VERSION "dbc-export 1 2026.26.6.5"

NS_ :

BS_:

BU_: ADSP APB APP APS APSB BB BMS CC CMP CMPD CP DAS DI DIF DIR DPB EPAS3P EPAS3S EPASTP EPASTS EPBL EPBR ESP EVSE FC GTW HCML HCMR HVP IBST ICR IDB LS OCS1P ODIN PARK PCS PCS2 PLG PM PMF PMR PNCD PTC RADC RCM RCM2 RCM3 RCU SCCM SCM SCS SDCR TAS TCU TCU2 TPMS TRCM UDS UI UIS UMC USM V2G VC VCBATT VCBATT0 VCBATT1 VCBATT2 VCCC VCFRONT VCFRONT1 VCFRONT2 VCLEFT VCRIGHT VCSEAT2L VCSEAT2R VCSEC VEH

BO_ 2011 VCRIGHT_alertLog: 8 VCRIGHT
 SG_ VCRIGHT_alertID M : 0|10@1+ (1,0) [0|1023] "" Vector__XXX
 SG_ VCRIGHT_a518_seatState m518 : 16|4@1+ (1,0) [0|14] "" Vector__XXX
 SG_ VCRIGHT_a520_epbConfig m520 : 16|4@1+ (1,0) [0|15] "" Vector__XXX
 SG_ VCRIGHT_a520_gtwEpbConfig m520 : 20|4@1+ (1,0) [0|15] "" Vector__XXX
 SG_ VCRIGHT_a525_GTW_twelveVBatteryT m525 : 16|3@1+ (1,0) [0|7] "" Vector__XXX
 SG_ VCRIGHT_a525_newLVBatteryType m525 : 19|3@1+ (1,0) [0|7] "" Vector__XXX
 SG_ VCRIGHT_a525_initialLVBatteryTyp m525 : 24|3@1+ (1,0) [0|7] "" Vector__XXX
 SG_ VCRIGHT_a525_serviceMode m525 : 27|1@1+ (1,0) [0|1] "" Vector__XXX
 SG_ VCRIGHT_a525_factoryGated m525 : 28|1@1+ (1,0) [0|1] "" Vector__XXX
 SG_ VCRIGHT_a525_frunkOpen m525 : 29|1@1+ (1,0) [0|1] "" Vector__XXX
 SG_ VCRIGHT_a538_ptcHeaterFault m538 : 16|1@1+ (1,0) [0|1] "" Vector__XXX
 SG_ VCRIGHT_a538_ductTempSensorFault m538 : 17|1@1+ (1,0) [0|1] "" Vector__XXX
 SG_ VCRIGHT_a538_evapTempSensorFault m538 : 18|1@1+ (1,0) [0|1] "" Vector__XXX
 SG_ VCRIGHT_a538_cabinTempSensorFaul m538 : 19|1@1+ (1,0) [0|1] "" Vector__XXX
 SG_ VCRIGHT_a538_cabinModelNotInitia m538 : 20|1@1+ (1,0) [0|1] "" Vector__XXX
 SG_ VCRIGHT_a538_airpathsBlocked m538 : 21|1@1+ (1,0) [0|1] "" Vector__XXX
 SG_ VCRIGHT_a538_blowerFaultOrStoppe m538 : 22|1@1+ (1,0) [0|1] "" Vector__XXX
 SG_ VCRIGHT_a538_compressorFaultOrSt m538 : 23|1@1+ (1,0) [0|1] "" Vector__XXX
 SG_ VCRIGHT_a538_heatPumpModeNotAtta m538 : 24|1@1+ (1,0) [0|1] "" Vector__XXX
 SG_ VCRIGHT_a538_thsVersionMismatch m538 : 25|1@1+ (1,0) [0|1] "" Vector__XXX
 SG_ VCRIGHT_a538_thsMia m538 : 26|1@1+ (1,0) [0|1] "" Vector__XXX
 SG_ VCRIGHT_a538_hvOn m538 : 27|1@1+ (1,0) [0|1] "" Vector__XXX
 SG_ VCRIGHT_a538_hvacPowerOn m538 : 28|1@1+ (1,0) [0|1] "" Vector__XXX
 SG_ VCRIGHT_a538_limpMode m538 : 29|1@1+ (1,0) [0|1] "" Vector__XXX
 SG_ VCRIGHT_a539_hvacSystemNotNomina m539 : 16|1@1+ (1,0) [0|1] "" Vector__XXX
 SG_ VCRIGHT_a539_modeledCabinTempOut m539 : 17|1@1+ (1,0) [0|1] "" Vector__XXX
 SG_ VCRIGHT_a539_modeledCabinTempExc m539 : 18|1@1+ (1,0) [0|1] "" Vector__XXX
 SG_ VCRIGHT_a539_cabinTempSensorFaul m539 : 19|1@1+ (1,0) [0|1] "" Vector__XXX
 SG_ VCRIGHT_a539_cabinTempSensorOutO m539 : 20|1@1+ (1,0) [0|1] "" Vector__XXX
 SG_ VCRIGHT_a539_modeledCabinTempDev m539 : 21|1@1+ (1,0) [0|1] "" Vector__XXX
 SG_ VCRIGHT_a545_GTW_twelveVBatteryT m545 : 16|3@1+ (1,0) [0|7] "" Vector__XXX
 SG_ VCRIGHT_a545_newLVBatteryType m545 : 19|3@1+ (1,0) [0|7] "" Vector__XXX
 SG_ VCRIGHT_a545_serviceMode m545 : 22|1@1+ (1,0) [0|1] "" Vector__XXX
 SG_ VCRIGHT_a545_factoryGated m545 : 23|1@1+ (1,0) [0|1] "" Vector__XXX
 SG_ VCRIGHT_a545_frunkOpen m545 : 24|1@1+ (1,0) [0|1] "" Vector__XXX
 SG_ VCRIGHT_a551_restrictDoorRelease m551 : 16|1@1+ (1,0) [0|1] "" Vector__XXX
 SG_ VCRIGHT_a551_interiorReleaseReqC m551 : 24|8@1+ (1,0) [0|255] "" Vector__XXX
 SG_ VCRIGHT_a551_lastRequestSourceFr m551 : 32|3@1+ (1,0) [0|7] "" Vector__XXX
 SG_ VCRIGHT_a551_restrictDoorRe_0001 m551 : 35|1@1+ (1,0) [0|1] "" Vector__XXX
 SG_ VCRIGHT_a551_interiorReleas_0001 m551 : 40|8@1+ (1,0) [0|255] "" Vector__XXX
 SG_ VCRIGHT_a551_lastRequestSourceRe m551 : 48|3@1+ (1,0) [0|7] "" Vector__XXX
 SG_ VCRIGHT_a560_isRearwardEndstopUn m560 : 16|1@1+ (1,0) [0|1] "" Vector__XXX
 SG_ VCRIGHT_a560_isAbsPosSensorUncal m560 : 17|1@1+ (1,0) [0|1] "" Vector__XXX
 SG_ VCRIGHT_a560_seatState m560 : 18|4@1+ (1,0) [0|14] "" Vector__XXX
 SG_ VCRIGHT_a560_motorType m560 : 22|1@1+ (1,0) [0|1] "" Vector__XXX
 SG_ VCRIGHT_a560_absPosSensState m560 : 24|2@1+ (1,0) [0|3] "" Vector__XXX
 SG_ VCRIGHT_a563_calibrated m563 : 16|1@1+ (1,0) [0|1] "" Vector__XXX
 SG_ VCRIGHT_a563_angle m563 : 17|8@1- (0.5,59) [-5|122.5] "deg" Vector__XXX
 SG_ VCRIGHT_a563_seatStatePrev m563 : 25|4@1+ (1,0) [0|14] "" Vector__XXX
 SG_ VCRIGHT_a563_obstacleDetectReaso m563 : 29|4@1+ (1,0) [0|15] "" Vector__XXX
 SG_ VCRIGHT_a563_accelLookbackTripDe m563 : 33|7@1+ (1,0) [0|127] "" Vector__XXX
 SG_ VCRIGHT_a563_duty m563 : 40|8@1- (1,0) [-128|127] "%" Vector__XXX
 SG_ VCRIGHT_a563_currentAbsFilt m563 : 48|8@1+ (0.25,0) [0|63.75] "A" Vector__XXX
 SG_ VCRIGHT_a563_motorType m563 : 56|1@1+ (1,0) [0|1] "" Vector__XXX
 SG_ VCRIGHT_a563_absolutePosSensorFo m563 : 57|1@1+ (1,0) [0|1] "" Vector__XXX
 SG_ VCRIGHT_a563_cabinTemp m563 : 58|6@1- (2,20) [-44|82] "degC" Vector__XXX
 SG_ VCRIGHT_a567_isRearwardEndstopUn m567 : 16|1@1+ (1,0) [0|1] "" Vector__XXX
 SG_ VCRIGHT_a567_isAbsPosSensorUncal m567 : 17|1@1+ (1,0) [0|1] "" Vector__XXX
 SG_ VCRIGHT_a568_seatState m568 : 16|4@1+ (1,0) [0|14] "" Vector__XXX
 SG_ VCRIGHT_a570_seatHeatCurrent m570 : 16|12@1+ (0.01,0) [0|40.95] "A" Vector__XXX
 SG_ VCRIGHT_a570_seatHeatTmp m570 : 28|12@1- (0.05,0) [-102.4|102.35] "degC" Vector__XXX
 SG_ VCRIGHT_a571_seatHeatCurrent m571 : 16|12@1+ (0.01,0) [0|40.95] "A" Vector__XXX
 SG_ VCRIGHT_a571_seatHeatTmp m571 : 28|12@1- (0.05,0) [-102.4|102.35] "degC" Vector__XXX
 SG_ VCRIGHT_a572_seatHeatCurrent m572 : 16|12@1+ (0.01,0) [0|40.95] "A" Vector__XXX
 SG_ VCRIGHT_a572_seatHeatTmp m572 : 28|12@1- (0.05,0) [-102.4|102.35] "degC" Vector__XXX
 SG_ VCRIGHT_a573_seatHeatCurrent m573 : 16|12@1+ (0.01,0) [0|40.95] "A" Vector__XXX
 SG_ VCRIGHT_a573_seatHeatTmp m573 : 28|12@1- (0.05,0) [-102.4|102.35] "degC" Vector__XXX
 SG_ VCRIGHT_a577_outputFaulted m577 : 16|1@1+ (1,0) [0|1] "" Vector__XXX
 SG_ VCRIGHT_a577_currentSenseFaulted m577 : 17|1@1+ (1,0) [0|1] "" Vector__XXX
 SG_ VCRIGHT_a577_tempSenseFaulted m577 : 18|1@1+ (1,0) [0|1] "" Vector__XXX
 SG_ VCRIGHT_a577_underCurrent m577 : 19|1@1+ (1,0) [0|1] "" Vector__XXX
 SG_ VCRIGHT_a577_overCurrent m577 : 20|1@1+ (1,0) [0|1] "" Vector__XXX
 SG_ VCRIGHT_a577_overTemperature m577 : 21|1@1+ (1,0) [0|1] "" Vector__XXX
 SG_ VCRIGHT_a578_openCircuitDoorFR m578 : 16|1@1+ (1,0) [0|1] "" Vector__XXX
 SG_ VCRIGHT_a578_shortCircuitDoorFR m578 : 17|1@1+ (1,0) [0|1] "" Vector__XXX
 SG_ VCRIGHT_a578_miaDoorFR m578 : 18|1@1+ (1,0) [0|1] "" Vector__XXX
 SG_ VCRIGHT_a578_openCircuitDoorRR m578 : 19|1@1+ (1,0) [0|1] "" Vector__XXX
 SG_ VCRIGHT_a578_shortCircuitDoorRR m578 : 20|1@1+ (1,0) [0|1] "" Vector__XXX
 SG_ VCRIGHT_a578_miaDoorRR m578 : 21|1@1+ (1,0) [0|1] "" Vector__XXX
 SG_ VCRIGHT_a579_liftgateFollowerSto m579 : 16|2@1+ (1,0) [0|3] "" Vector__XXX
 SG_ VCRIGHT_a579_liftgateFollowerPos m579 : 24|7@1- (1,43) [-21|106] "deg" Vector__XXX
 SG_ VCRIGHT_a579_liftgateFollowerLat m579 : 32|4@1+ (1,0) [1|15] "" Vector__XXX
 SG_ VCRIGHT_a585_ambientTemp m585 : 16|8@1+ (0.5,-40) [-39.5|87.5] "degC" Vector__XXX
 SG_ VCRIGHT_a586_ambientTemp m586 : 16|8@1+ (0.5,-40) [-39.5|87.5] "degC" Vector__XXX
 SG_ VCRIGHT_a587_VEH_switchStatus m587 : 63|1@1+ (1,0) [0|1] "" Vector__XXX
 SG_ VCRIGHT_a588_VEH_seatStatus2 m588 : 61|1@1+ (1,0) [0|1] "" Vector__XXX
 SG_ VCRIGHT_a588_VEH_switchStatus m588 : 62|1@1+ (1,0) [0|1] "" Vector__XXX
 SG_ VCRIGHT_a588_VEH_restraintStatus m588 : 63|1@1+ (1,0) [0|1] "" Vector__XXX
 SG_ VCRIGHT_a590_seatMotorCalibrated m590 : 16|1@1+ (1,0) [0|1] "" Vector__XXX
 SG_ VCRIGHT_a590_seatMotorCurrent m590 : 17|12@1- (0.01,0) [-20.48|20.47] "A" Vector__XXX
 SG_ VCRIGHT_a590_seatMotorState m590 : 29|3@1+ (1,0) [0|7] "" Vector__XXX
 SG_ VCRIGHT_a590_seatSwitchBack m590 : 32|2@1+ (1,0) [1|3] "" Vector__XXX
 SG_ VCRIGHT_a590_seatSwitchForward m590 : 34|2@1+ (1,0) [1|3] "" Vector__XXX
 SG_ VCRIGHT_a591_seatMotorCurrent m591 : 16|12@1- (0.01,0) [-20.48|20.47] "A" Vector__XXX
 SG_ VCRIGHT_a591_seatMotorPosReal m591 : 28|12@1- (1,0) [-2048|2047] "mm" Vector__XXX
 SG_ VCRIGHT_a591_seatMotorState m591 : 40|3@1+ (1,0) [0|7] "" Vector__XXX
 SG_ VCRIGHT_a591_seatSwitchBack m591 : 43|2@1+ (1,0) [1|3] "" Vector__XXX
 SG_ VCRIGHT_a591_seatSwitchForward m591 : 45|2@1+ (1,0) [1|3] "" Vector__XXX
 SG_ VCRIGHT_a592_seatMotorCurrent m592 : 16|12@1- (0.01,0) [-20.48|20.47] "A" Vector__XXX
 SG_ VCRIGHT_a592_seatMotorPosReal m592 : 28|12@1- (1,0) [-2048|2047] "mm" Vector__XXX
 SG_ VCRIGHT_a592_seatMotorState m592 : 40|3@1+ (1,0) [0|7] "" Vector__XXX
 SG_ VCRIGHT_a592_seatSwitchBack m592 : 43|2@1+ (1,0) [1|3] "" Vector__XXX
 SG_ VCRIGHT_a592_seatSwitchForward m592 : 45|2@1+ (1,0) [1|3] "" Vector__XXX
 SG_ VCRIGHT_a593_seatMotorCalibrated m593 : 16|1@1+ (1,0) [0|1] "" Vector__XXX
 SG_ VCRIGHT_a593_seatMotorCurrent m593 : 17|12@1- (0.01,0) [-20.48|20.47] "A" Vector__XXX
 SG_ VCRIGHT_a593_seatMotorPosReal m593 : 32|12@1- (1,0) [-2048|2047] "mm" Vector__XXX
 SG_ VCRIGHT_a593_seatMotorState m593 : 44|3@1+ (1,0) [0|7] "" Vector__XXX
 SG_ VCRIGHT_a593_seatSwitchBack m593 : 48|2@1+ (1,0) [1|3] "" Vector__XXX
 SG_ VCRIGHT_a593_seatSwitchForward m593 : 50|2@1+ (1,0) [1|3] "" Vector__XXX
 SG_ VCRIGHT_a594_seatMotorCurrent m594 : 16|12@1- (0.01,0) [-20.48|20.47] "A" Vector__XXX
 SG_ VCRIGHT_a594_seatMotorDCurrent m594 : 28|12@1- (0.01,0) [-20.48|20.47] "A" Vector__XXX
 SG_ VCRIGHT_a594_seatMotorPosReal m594 : 40|12@1- (1,0) [-2048|2047] "mm" Vector__XXX
 SG_ VCRIGHT_a594_seatMotorState m594 : 52|3@1+ (1,0) [0|7] "" Vector__XXX
 SG_ VCRIGHT_a595_seatMotorCurrent m595 : 16|12@1- (0.01,0) [-20.48|20.47] "A" Vector__XXX
 SG_ VCRIGHT_a595_seatMotorDCurrent m595 : 28|12@1- (0.01,0) [-20.48|20.47] "A" Vector__XXX
 SG_ VCRIGHT_a595_seatMotorPosReal m595 : 40|12@1- (1,0) [-2048|2047] "mm" Vector__XXX
 SG_ VCRIGHT_a595_seatMotorState m595 : 52|3@1+ (1,0) [0|7] "" Vector__XXX
 SG_ VCRIGHT_a596_frontDoorLatchAjarS m596 : 16|12@1+ (1.25,0) [0|5118.75] "mV" Vector__XXX
 SG_ VCRIGHT_a597_rearDoorLatchAjarSw m597 : 16|12@1+ (1.25,0) [0|5118.75] "mV" Vector__XXX
 SG_ VCRIGHT_a599_GTW_twelveVBatteryT m599 : 16|3@1+ (1,0) [0|7] "" Vector__XXX
 SG_ VCRIGHT_a599_newLVBatteryType m599 : 19|3@1+ (1,0) [0|7] "" Vector__XXX
 SG_ VCRIGHT_a599_initialLVBatteryTyp m599 : 24|3@1+ (1,0) [0|7] "" Vector__XXX
 SG_ VCRIGHT_a599_serviceMode m599 : 27|1@1+ (1,0) [0|1] "" Vector__XXX
 SG_ VCRIGHT_a599_factoryGated m599 : 28|1@1+ (1,0) [0|1] "" Vector__XXX
 SG_ VCRIGHT_a599_frunkOpen m599 : 29|1@1+ (1,0) [0|1] "" Vector__XXX
 SG_ VCRIGHT_a605_excessiveMacFailure m605 : 16|1@1+ (1,0) [0|1] "" Vector__XXX

BO_ 960 VCRIGHT_alertMatrix: 8 VCRIGHT
 SG_ VCRIGHT_matrixIndex M : 0|4@1+ (1,0) [0|15] "" Vector__XXX
 SG_ VCRIGHT_a001_WatchdogReset m0 : 4|1@1+ (1,0) [0|1] "" Vector__XXX
 SG_ VCRIGHT_a002_PowerLossReset m0 : 5|1@1+ (1,0) [0|1] "" Vector__XXX
 SG_ VCRIGHT_a003_SWAssertion m0 : 6|1@1+ (1,0) [0|1] "" Vector__XXX
 SG_ VCRIGHT_a005_CANTXError m0 : 8|1@1+ (1,0) [0|1] "" Vector__XXX
 SG_ VCRIGHT_a006_CANTX_cyclicError m0 : 9|1@1+ (1,0) [0|1] "" Vector__XXX
 SG_ VCRIGHT_a010_ExtSupplyVoltError m0 : 13|1@1+ (1,0) [0|1] "" Vector__XXX
 SG_ VCRIGHT_a012_CPUReset m0 : 15|1@1+ (1,0) [0|1] "" Vector__XXX
 SG_ VCRIGHT_a013_AlertManagerFault m0 : 16|1@1+ (1,0) [0|1] "" Vector__XXX
 SG_ VCRIGHT_a015_NVMMError m0 : 18|1@1+ (1,0) [0|1] "" Vector__XXX
 SG_ VCRIGHT_a016_NVMMRecordError m0 : 19|1@1+ (1,0) [0|1] "" Vector__XXX
 SG_ VCRIGHT_a017_NVMMStatusDbg m0 : 20|1@1+ (1,0) [0|1] "" Vector__XXX
 SG_ VCRIGHT_a021_TaskSchedulerError m0 : 24|1@1+ (1,0) [0|1] "" Vector__XXX
 SG_ VCRIGHT_a022_TaskInitError m0 : 25|1@1+ (1,0) [0|1] "" Vector__XXX
 SG_ VCRIGHT_a029_CoreDump m0 : 32|1@1+ (1,0) [0|1] "" Vector__XXX
 SG_ VCRIGHT_a030_ECULogUploadRequest m0 : 33|1@1+ (1,0) [0|1] "" Vector__XXX
 SG_ VCRIGHT_a031_UDSActive m0 : 34|1@1+ (1,0) [0|1] "" Vector__XXX
 SG_ VCRIGHT_a041_HighCPULoad m0 : 44|1@1+ (1,0) [0|1] "" Vector__XXX
 SG_ VCRIGHT_a042_HighStackUsage m0 : 45|1@1+ (1,0) [0|1] "" Vector__XXX
 SG_ VCRIGHT_a043_Task1msError m0 : 46|1@1+ (1,0) [0|1] "" Vector__XXX
 SG_ VCRIGHT_a044_Task10msError m0 : 47|1@1+ (1,0) [0|1] "" Vector__XXX
 SG_ VCRIGHT_a045_Task100msError m0 : 48|1@1+ (1,0) [0|1] "" Vector__XXX
 SG_ VCRIGHT_a046_Task1000msError m0 : 49|1@1+ (1,0) [0|1] "" Vector__XXX
 SG_ VCRIGHT_a057_HVP_MIA m0 : 60|1@1+ (1,0) [0|1] "" Vector__XXX
 SG_ VCRIGHT_a058_inputRHighSyncDebug m0 : 61|1@1+ (1,0) [0|1] "" Vector__XXX
 SG_ VCRIGHT_a059_inputResistanceHigh m0 : 62|1@1+ (1,0) [0|1] "" Vector__XXX
 SG_ VCRIGHT_a060_engineeringBuild m0 : 63|1@1+ (1,0) [0|1] "" Vector__XXX
 SG_ VCRIGHT_a061_XCPConnected m1 : 4|1@1+ (1,0) [0|1] "" Vector__XXX
 SG_ VCRIGHT_a062_XCPWasConnected m1 : 5|1@1+ (1,0) [0|1] "" Vector__XXX
 SG_ VCRIGHT_a063_SwitchFault m1 : 6|1@1+ (1,0) [0|1] "" Vector__XXX
 SG_ VCRIGHT_a064_busSleepReqTimeout m1 : 7|1@1+ (1,0) [0|1] "" Vector__XXX
 SG_ VCRIGHT_a065_emiosIsrRateLimited m1 : 8|1@1+ (1,0) [0|1] "" Vector__XXX
 SG_ VCRIGHT_a066_emiosIsrShortPeriod m1 : 9|1@1+ (1,0) [0|1] "" Vector__XXX
 SG_ VCRIGHT_a082_VCRIGHT_IPC_MIA m1 : 25|1@1+ (1,0) [0|1] "" Vector__XXX
 SG_ VCRIGHT_a083_VCLEFT_IPC_MIA m1 : 26|1@1+ (1,0) [0|1] "" Vector__XXX
 SG_ VCRIGHT_a084_TPMS_MIA m1 : 27|1@1+ (1,0) [0|1] "" Vector__XXX
 SG_ VCRIGHT_a085_CCCM_MIA m1 : 28|1@1+ (1,0) [0|1] "" Vector__XXX
 SG_ VCRIGHT_a086_VCBATT_MIA m1 : 29|1@1+ (1,0) [0|1] "" Vector__XXX
 SG_ VCRIGHT_a087_DIREL_MIA m1 : 30|1@1+ (1,0) [0|1] "" Vector__XXX
 SG_ VCRIGHT_a088_DIRER_MIA m1 : 31|1@1+ (1,0) [0|1] "" Vector__XXX
 SG_ VCRIGHT_a089_IBST_MIA m1 : 32|1@1+ (1,0) [0|1] "" Vector__XXX
 SG_ VCRIGHT_a090_APS_MIA m1 : 33|1@1+ (1,0) [0|1] "" Vector__XXX
 SG_ VCRIGHT_a091_CMPD_MIA m1 : 34|1@1+ (1,0) [0|1] "" Vector__XXX
 SG_ VCRIGHT_a092_VCSEATD_MIA m1 : 35|1@1+ (1,0) [0|1] "" Vector__XXX
 SG_ VCRIGHT_a093_VCSEATP_MIA m1 : 36|1@1+ (1,0) [0|1] "" Vector__XXX
 SG_ VCRIGHT_a094_EPAS3P_MIA m1 : 37|1@1+ (1,0) [0|1] "" Vector__XXX
 SG_ VCRIGHT_a095_CHG_MIA m1 : 38|1@1+ (1,0) [0|1] "" Vector__XXX
 SG_ VCRIGHT_a096_OCS1P_MIA m1 : 39|1@1+ (1,0) [0|1] "" Vector__XXX
 SG_ VCRIGHT_a097_CMP_MIA m1 : 40|1@1+ (1,0) [0|1] "" Vector__XXX
 SG_ VCRIGHT_a098_DIR_MIA m1 : 41|1@1+ (1,0) [0|1] "" Vector__XXX
 SG_ VCRIGHT_a099_PARK_MIA m1 : 42|1@1+ (1,0) [0|1] "" Vector__XXX
 SG_ VCRIGHT_a100_CANbus_MIA m1 : 43|1@1+ (1,0) [0|1] "" Vector__XXX
 SG_ VCRIGHT_a101_PM_MIA m1 : 44|1@1+ (1,0) [0|1] "" Vector__XXX
 SG_ VCRIGHT_a102_PTC_MIA m1 : 45|1@1+ (1,0) [0|1] "" Vector__XXX
 SG_ VCRIGHT_a103_CP_MIA m1 : 46|1@1+ (1,0) [0|1] "" Vector__XXX
 SG_ VCRIGHT_a104_DAS_MIA m1 : 47|1@1+ (1,0) [0|1] "" Vector__XXX
 SG_ VCRIGHT_a105_TAS_MIA m1 : 48|1@1+ (1,0) [0|1] "" Vector__XXX
 SG_ VCRIGHT_a106_PCS_MIA m1 : 49|1@1+ (1,0) [0|1] "" Vector__XXX
 SG_ VCRIGHT_a107_BMS_MIA m1 : 50|1@1+ (1,0) [0|1] "" Vector__XXX
 SG_ VCRIGHT_a108_DIF_MIA m1 : 51|1@1+ (1,0) [0|1] "" Vector__XXX
 SG_ VCRIGHT_a109_RCM_MIA m1 : 52|1@1+ (1,0) [0|1] "" Vector__XXX
 SG_ VCRIGHT_a110_GTW_MIA m1 : 53|1@1+ (1,0) [0|1] "" Vector__XXX
 SG_ VCRIGHT_a111_EPBR_MIA m1 : 54|1@1+ (1,0) [0|1] "" Vector__XXX
 SG_ VCRIGHT_a112_EPBL_MIA m1 : 55|1@1+ (1,0) [0|1] "" Vector__XXX
 SG_ VCRIGHT_a113_UI_MIA m1 : 56|1@1+ (1,0) [0|1] "" Vector__XXX
 SG_ VCRIGHT_a114_ESP_MIA m1 : 57|1@1+ (1,0) [0|1] "" Vector__XXX
 SG_ VCRIGHT_a115_VCSEC_MIA m1 : 58|1@1+ (1,0) [0|1] "" Vector__XXX
 SG_ VCRIGHT_a116_VCRIGHT_MIA m1 : 59|1@1+ (1,0) [0|1] "" Vector__XXX
 SG_ VCRIGHT_a117_VCLEFT_MIA m1 : 60|1@1+ (1,0) [0|1] "" Vector__XXX
 SG_ VCRIGHT_a118_VCFRONT_MIA m1 : 61|1@1+ (1,0) [0|1] "" Vector__XXX
 SG_ VCRIGHT_a119_SCCM_MIA m1 : 62|1@1+ (1,0) [0|1] "" Vector__XXX
 SG_ VCRIGHT_a120_DI_DRIVE_MIA m1 : 63|1@1+ (1,0) [0|1] "" Vector__XXX
 SG_ VCRIGHT_a121_ETC_MIA m2 : 4|1@1+ (1,0) [0|1] "" Vector__XXX
 SG_ VCRIGHT_a122_ICR_MIA m2 : 5|1@1+ (1,0) [0|1] "" Vector__XXX
 SG_ VCRIGHT_a123_VC_SECONDARY_LIGHTI m2 : 6|1@1+ (1,0) [0|1] "" Vector__XXX
 SG_ VCRIGHT_a124_BB_MIA m2 : 7|1@1+ (1,0) [0|1] "" Vector__XXX
 SG_ VCRIGHT_a125_RCU_MIA m2 : 8|1@1+ (1,0) [0|1] "" Vector__XXX
 SG_ VCRIGHT_a126_hvacActOpenLoadDBG m2 : 9|1@1+ (1,0) [0|1] "" Vector__XXX
 SG_ VCRIGHT_a127_hvacActOvercurrentD m2 : 10|1@1+ (1,0) [0|1] "" Vector__XXX
 SG_ VCRIGHT_a128_hvacActDrvFaultDBG m2 : 11|1@1+ (1,0) [0|1] "" Vector__XXX
 SG_ VCRIGHT_a129_hvacIntakeUncalib m2 : 12|1@1+ (1,0) [0|1] "" Vector__XXX
 SG_ VCRIGHT_a130_hvacLHBleedUncalib m2 : 13|1@1+ (1,0) [0|1] "" Vector__XXX
 SG_ VCRIGHT_a131_hvacRHBleedUncalib m2 : 14|1@1+ (1,0) [0|1] "" Vector__XXX
 SG_ VCRIGHT_a132_hvacLHVaneUncalib m2 : 15|1@1+ (1,0) [0|1] "" Vector__XXX
 SG_ VCRIGHT_a133_hvacRHVaneUncalib m2 : 16|1@1+ (1,0) [0|1] "" Vector__XXX
 SG_ VCRIGHT_a134_hvacUpprModeUncalib m2 : 17|1@1+ (1,0) [0|1] "" Vector__XXX
 SG_ VCRIGHT_a135_hvacLowrModeUncalib m2 : 18|1@1+ (1,0) [0|1] "" Vector__XXX
 SG_ VCRIGHT_a136_hvacIntakeFault m2 : 19|1@1+ (1,0) [0|1] "" Vector__XXX
 SG_ VCRIGHT_a137_hvacLHBleedFault m2 : 20|1@1+ (1,0) [0|1] "" Vector__XXX
 SG_ VCRIGHT_a138_hvacRHBleedFault m2 : 21|1@1+ (1,0) [0|1] "" Vector__XXX
 SG_ VCRIGHT_a139_hvacLHVaneFault m2 : 22|1@1+ (1,0) [0|1] "" Vector__XXX
 SG_ VCRIGHT_a140_hvacRHVaneFault m2 : 23|1@1+ (1,0) [0|1] "" Vector__XXX
 SG_ VCRIGHT_a141_hvacUpperModeFault m2 : 24|1@1+ (1,0) [0|1] "" Vector__XXX
 SG_ VCRIGHT_a142_hvacLowerModeFault m2 : 25|1@1+ (1,0) [0|1] "" Vector__XXX
 SG_ VCRIGHT_a143_mirrorManuallyFolde m2 : 26|1@1+ (1,0) [0|1] "" Vector__XXX
 SG_ VCRIGHT_a144_evaporatorTempSns m2 : 27|1@1+ (1,0) [0|1] "" Vector__XXX
 SG_ VCRIGHT_a145_ductLeftTempSns m2 : 28|1@1+ (1,0) [0|1] "" Vector__XXX
 SG_ VCRIGHT_a146_ductRightTempSns m2 : 29|1@1+ (1,0) [0|1] "" Vector__XXX
 SG_ VCRIGHT_a147_incarProbeTempSns m2 : 30|1@1+ (1,0) [0|1] "" Vector__XXX
 SG_ VCRIGHT_a148_incarMidTempSns m2 : 31|1@1+ (1,0) [0|1] "" Vector__XXX
 SG_ VCRIGHT_a149_incarDeepTempSns m2 : 32|1@1+ (1,0) [0|1] "" Vector__XXX
 SG_ VCRIGHT_a150_windowPinchFront m2 : 33|1@1+ (1,0) [0|1] "" Vector__XXX
 SG_ VCRIGHT_a151_windowPinchRear m2 : 34|1@1+ (1,0) [0|1] "" Vector__XXX
 SG_ VCRIGHT_a152_windowUncalFront m2 : 35|1@1+ (1,0) [0|1] "" Vector__XXX
 SG_ VCRIGHT_a153_windowUncalRear m2 : 36|1@1+ (1,0) [0|1] "" Vector__XXX
 SG_ VCRIGHT_a154_windowThermalFront m2 : 37|1@1+ (1,0) [0|1] "" Vector__XXX
 SG_ VCRIGHT_a155_windowThermalRear m2 : 38|1@1+ (1,0) [0|1] "" Vector__XXX
 SG_ VCRIGHT_a156_windowNoInputFront m2 : 39|1@1+ (1,0) [0|1] "" Vector__XXX
 SG_ VCRIGHT_a157_windowNoInputRear m2 : 40|1@1+ (1,0) [0|1] "" Vector__XXX
 SG_ VCRIGHT_a158_windowPinchOverideF m2 : 41|1@1+ (1,0) [0|1] "" Vector__XXX
 SG_ VCRIGHT_a159_windowPinchOverideR m2 : 42|1@1+ (1,0) [0|1] "" Vector__XXX
 SG_ VCRIGHT_a160_windowUndercurrentF m2 : 43|1@1+ (1,0) [0|1] "" Vector__XXX
 SG_ VCRIGHT_a161_windowUndercurrentR m2 : 44|1@1+ (1,0) [0|1] "" Vector__XXX
 SG_ VCRIGHT_a162_windowEncoderStallF m2 : 45|1@1+ (1,0) [0|1] "" Vector__XXX
 SG_ VCRIGHT_a163_windowEncoderStallR m2 : 46|1@1+ (1,0) [0|1] "" Vector__XXX
 SG_ VCRIGHT_a164_windowFactoryTest m2 : 47|1@1+ (1,0) [0|1] "" Vector__XXX
 SG_ VCRIGHT_a165_windowFactoryTest2 m2 : 48|1@1+ (1,0) [0|1] "" Vector__XXX
 SG_ VCRIGHT_a166_windowDebug m2 : 49|1@1+ (1,0) [0|1] "" Vector__XXX
 SG_ VCRIGHT_a167_windowDebugPinchF m2 : 50|1@1+ (1,0) [0|1] "" Vector__XXX
 SG_ VCRIGHT_a168_windowDebugPinchR m2 : 51|1@1+ (1,0) [0|1] "" Vector__XXX
 SG_ VCRIGHT_a169_windowCurrentPeakF m2 : 52|1@1+ (1,0) [0|1] "" Vector__XXX
 SG_ VCRIGHT_a170_windowCurrentPeakR m2 : 53|1@1+ (1,0) [0|1] "" Vector__XXX
 SG_ VCRIGHT_a171_hvacRearUncalib m2 : 54|1@1+ (1,0) [0|1] "" Vector__XXX
 SG_ VCRIGHT_a172_SPI_MIA m2 : 55|1@1+ (1,0) [0|1] "" Vector__XXX
 SG_ VCRIGHT_a173_windowBtnDoorOpen m2 : 56|1@1+ (1,0) [0|1] "" Vector__XXX
 SG_ VCRIGHT_a174_BLERightPowerCycled m2 : 57|1@1+ (1,0) [0|1] "" Vector__XXX
 SG_ VCRIGHT_a175_windowSealDefectFro m2 : 58|1@1+ (1,0) [0|1] "" Vector__XXX
 SG_ VCRIGHT_a176_windowSealDefectRea m2 : 59|1@1+ (1,0) [0|1] "" Vector__XXX
 SG_ VCRIGHT_a177_hvacRearFault m2 : 60|1@1+ (1,0) [0|1] "" Vector__XXX
 SG_ VCRIGHT_a178_trunkSwitchVCBATTMI m2 : 61|1@1+ (1,0) [0|1] "" Vector__XXX
 SG_ VCRIGHT_a179_trunkSwitchVCFRONTM m2 : 62|1@1+ (1,0) [0|1] "" Vector__XXX
 SG_ VCRIGHT_a180_frontDoorLatchRehom m2 : 63|1@1+ (1,0) [0|1] "" Vector__XXX
 SG_ VCRIGHT_a181_rearDoorLatchRehome m3 : 4|1@1+ (1,0) [0|1] "" Vector__XXX
 SG_ VCRIGHT_a182_emergencyLatchRel m3 : 5|1@1+ (1,0) [0|1] "" Vector__XXX
 SG_ VCRIGHT_a183_doorStateFactoryTes m3 : 6|1@1+ (1,0) [0|1] "" Vector__XXX
 SG_ VCRIGHT_a184_trunkFailedOpening m3 : 7|1@1+ (1,0) [0|1] "" Vector__XXX
 SG_ VCRIGHT_a185_summonAborted m3 : 8|1@1+ (1,0) [0|1] "" Vector__XXX
 SG_ VCRIGHT_a186_latchReleaseFailedF m3 : 9|1@1+ (1,0) [0|1] "" Vector__XXX
 SG_ VCRIGHT_a187_latchReleaseFailedR m3 : 10|1@1+ (1,0) [0|1] "" Vector__XXX
 SG_ VCRIGHT_a188_latchUnableToRearmF m3 : 11|1@1+ (1,0) [0|1] "" Vector__XXX
 SG_ VCRIGHT_a189_latchUnableToRearmR m3 : 12|1@1+ (1,0) [0|1] "" Vector__XXX
 SG_ VCRIGHT_a190_eFuseMgmtVbatFused m3 : 13|1@1+ (1,0) [0|1] "" Vector__XXX
 SG_ VCRIGHT_a191_gloveboxPower m3 : 14|1@1+ (1,0) [0|1] "" Vector__XXX
 SG_ VCRIGHT_a192_gloveboxLatchRel m3 : 15|1@1+ (1,0) [0|1] "" Vector__XXX
 SG_ VCRIGHT_a193_amplifierEFuseFault m3 : 16|1@1+ (1,0) [0|1] "" Vector__XXX
 SG_ VCRIGHT_a194_cntctrPwrEFuseFault m3 : 17|1@1+ (1,0) [0|1] "" Vector__XXX
 SG_ VCRIGHT_a195_hvcEFuseFault m3 : 18|1@1+ (1,0) [0|1] "" Vector__XXX
 SG_ VCRIGHT_a196_VEHCANOverterminate m3 : 19|1@1+ (1,0) [0|1] "" Vector__XXX
 SG_ VCRIGHT_a197_VEHCANUndertrminate m3 : 20|1@1+ (1,0) [0|1] "" Vector__XXX
 SG_ VCRIGHT_a198_PRVCANOverterminate m3 : 21|1@1+ (1,0) [0|1] "" Vector__XXX
 SG_ VCRIGHT_a199_PRVCANUndertrminate m3 : 22|1@1+ (1,0) [0|1] "" Vector__XXX
 SG_ VCRIGHT_a200_motorPhantomEncoder m3 : 23|1@1+ (1,0) [0|1] "" Vector__XXX
 SG_ VCRIGHT_a201_motorDutyEncDisabl m3 : 24|1@1+ (1,0) [0|1] "" Vector__XXX
 SG_ VCRIGHT_a202_epbmUnderIStatic m3 : 25|1@1+ (1,0) [0|1] "" Vector__XXX
 SG_ VCRIGHT_a203_epbmOverIStatic m3 : 26|1@1+ (1,0) [0|1] "" Vector__XXX
 SG_ VCRIGHT_a204_epbmUnderIDyn m3 : 27|1@1+ (1,0) [0|1] "" Vector__XXX
 SG_ VCRIGHT_a205_epbmOverIDyn m3 : 28|1@1+ (1,0) [0|1] "" Vector__XXX
 SG_ VCRIGHT_a206_epbWrongDirection m3 : 29|1@1+ (1,0) [0|1] "" Vector__XXX
 SG_ VCRIGHT_a207_epbmEnableWrong m3 : 30|1@1+ (1,0) [0|1] "" Vector__XXX
 SG_ VCRIGHT_a208_epbFaulted m3 : 31|1@1+ (1,0) [0|1] "" Vector__XXX
 SG_ VCRIGHT_a209_epbStateMisTime m3 : 32|1@1+ (1,0) [0|1] "" Vector__XXX
 SG_ VCRIGHT_a210_epbStateTime m3 : 33|1@1+ (1,0) [0|1] "" Vector__XXX
 SG_ VCRIGHT_a211_epbmUnderIStaticNew m3 : 34|1@1+ (1,0) [0|1] "" Vector__XXX
 SG_ VCRIGHT_a212_epbmOverIStaticNew m3 : 35|1@1+ (1,0) [0|1] "" Vector__XXX
 SG_ VCRIGHT_a213_epbmUnderIDynNew m3 : 36|1@1+ (1,0) [0|1] "" Vector__XXX
 SG_ VCRIGHT_a214_epbmOverIDynNew m3 : 37|1@1+ (1,0) [0|1] "" Vector__XXX
 SG_ VCRIGHT_a215_currentDesyncWarnin m3 : 38|1@1+ (1,0) [0|1] "" Vector__XXX
 SG_ VCRIGHT_a216_SPI_MIA_debugData1 m3 : 39|1@1+ (1,0) [0|1] "" Vector__XXX
 SG_ VCRIGHT_a217_SPI_MIA_debugData2 m3 : 40|1@1+ (1,0) [0|1] "" Vector__XXX
 SG_ VCRIGHT_a218_motorDriverFault m3 : 41|1@1+ (1,0) [0|1] "" Vector__XXX
 SG_ VCRIGHT_a219_motorCurrentDropout m3 : 42|1@1+ (1,0) [0|1] "" Vector__XXX
 SG_ VCRIGHT_a220_reverseLightFaultUs m3 : 43|1@1+ (1,0) [0|1] "" Vector__XXX
 SG_ VCRIGHT_a221_undervoltageLoadshe m3 : 44|1@1+ (1,0) [0|1] "" Vector__XXX
 SG_ VCRIGHT_a222_rearFasciaFogLightF m3 : 45|1@1+ (1,0) [0|1] "" Vector__XXX
 SG_ VCRIGHT_a223_VCBATT1_MIA m3 : 46|1@1+ (1,0) [0|1] "" Vector__XXX
 SG_ VCRIGHT_a224_seatEncStallTrack m3 : 47|1@1+ (1,0) [0|1] "" Vector__XXX
 SG_ VCRIGHT_a225_seatEncStallBack m3 : 48|1@1+ (1,0) [0|1] "" Vector__XXX
 SG_ VCRIGHT_a226_seatEncStallTilt m3 : 49|1@1+ (1,0) [0|1] "" Vector__XXX
 SG_ VCRIGHT_a227_seatEncStallLift m3 : 50|1@1+ (1,0) [0|1] "" Vector__XXX
 SG_ VCRIGHT_a228_seatEncOverTrack m3 : 51|1@1+ (1,0) [0|1] "" Vector__XXX
 SG_ VCRIGHT_a229_seatEncOverBack m3 : 52|1@1+ (1,0) [0|1] "" Vector__XXX
 SG_ VCRIGHT_a230_seatEncOverTilt m3 : 53|1@1+ (1,0) [0|1] "" Vector__XXX
 SG_ VCRIGHT_a231_seatEncOverLift m3 : 54|1@1+ (1,0) [0|1] "" Vector__XXX
 SG_ VCRIGHT_a232_seatCurrUnderTrack m3 : 55|1@1+ (1,0) [0|1] "" Vector__XXX
 SG_ VCRIGHT_a233_seatCurrUnderBack m3 : 56|1@1+ (1,0) [0|1] "" Vector__XXX
 SG_ VCRIGHT_a234_seatCurrUnderTilt m3 : 57|1@1+ (1,0) [0|1] "" Vector__XXX
 SG_ VCRIGHT_a235_seatCurrUnderLift m3 : 58|1@1+ (1,0) [0|1] "" Vector__XXX
 SG_ VCRIGHT_a236_lumbarOverPresA m3 : 59|1@1+ (1,0) [0|1] "" Vector__XXX
 SG_ VCRIGHT_a237_lumbarOverPresB m3 : 60|1@1+ (1,0) [0|1] "" Vector__XXX
 SG_ VCRIGHT_a238_lumbarValveMIA m3 : 61|1@1+ (1,0) [0|1] "" Vector__XXX
 SG_ VCRIGHT_a239_seatHeatIFront m3 : 62|1@1+ (1,0) [0|1] "" Vector__XXX
 SG_ VCRIGHT_a240_seatHeatShortFront m3 : 63|1@1+ (1,0) [0|1] "" Vector__XXX
 SG_ VCRIGHT_a241_seatHeatMIAFront m4 : 4|1@1+ (1,0) [0|1] "" Vector__XXX
 SG_ VCRIGHT_a242_seatHeatIRearL m4 : 5|1@1+ (1,0) [0|1] "" Vector__XXX
 SG_ VCRIGHT_a243_seatHeatShortRearL m4 : 6|1@1+ (1,0) [0|1] "" Vector__XXX
 SG_ VCRIGHT_a244_seatHeatMIARearL m4 : 7|1@1+ (1,0) [0|1] "" Vector__XXX
 SG_ VCRIGHT_a245_seatHeatIRearC m4 : 8|1@1+ (1,0) [0|1] "" Vector__XXX
 SG_ VCRIGHT_a246_seatHeatShortRearC m4 : 9|1@1+ (1,0) [0|1] "" Vector__XXX
 SG_ VCRIGHT_a247_seatHeatMIARearC m4 : 10|1@1+ (1,0) [0|1] "" Vector__XXX
 SG_ VCRIGHT_a248_seatHeatIRearR m4 : 11|1@1+ (1,0) [0|1] "" Vector__XXX
 SG_ VCRIGHT_a249_seatHeatShortRearR m4 : 12|1@1+ (1,0) [0|1] "" Vector__XXX
 SG_ VCRIGHT_a250_seatHeatMIARearR m4 : 13|1@1+ (1,0) [0|1] "" Vector__XXX
 SG_ VCRIGHT_a251_seatUncalTrack m4 : 14|1@1+ (1,0) [0|1] "" Vector__XXX
 SG_ VCRIGHT_a252_seatUncalBack m4 : 15|1@1+ (1,0) [0|1] "" Vector__XXX
 SG_ VCRIGHT_a253_seatUncalTilt m4 : 16|1@1+ (1,0) [0|1] "" Vector__XXX
 SG_ VCRIGHT_a254_seatUncalLift m4 : 17|1@1+ (1,0) [0|1] "" Vector__XXX
 SG_ VCRIGHT_a255_PTCOverTemp m4 : 18|1@1+ (1,0) [0|1] "" Vector__XXX
 SG_ VCRIGHT_a256_PTCCurrentDrawNoReq m4 : 19|1@1+ (1,0) [0|1] "" Vector__XXX
 SG_ VCRIGHT_a257_THSMIA m4 : 20|1@1+ (1,0) [0|1] "" Vector__XXX
 SG_ VCRIGHT_a258_PTCStuckInBoot m4 : 21|1@1+ (1,0) [0|1] "" Vector__XXX
 SG_ VCRIGHT_a259_latchDisarmDelayF m4 : 22|1@1+ (1,0) [0|1] "" Vector__XXX
 SG_ VCRIGHT_a260_latchDisarmDelayR m4 : 23|1@1+ (1,0) [0|1] "" Vector__XXX
 SG_ VCRIGHT_a261_emergencyLatchRelRe m4 : 24|1@1+ (1,0) [0|1] "" Vector__XXX
 SG_ VCRIGHT_a262_PTCFaulted m4 : 25|1@1+ (1,0) [0|1] "" Vector__XXX
 SG_ VCRIGHT_a263_seatTrackStallDebug m4 : 26|1@1+ (1,0) [0|1] "" Vector__XXX
 SG_ VCRIGHT_a264_seatBackStallDebug m4 : 27|1@1+ (1,0) [0|1] "" Vector__XXX
 SG_ VCRIGHT_a265_seatTiltStallDebug m4 : 28|1@1+ (1,0) [0|1] "" Vector__XXX
 SG_ VCRIGHT_a266_seatLiftStallDebug m4 : 29|1@1+ (1,0) [0|1] "" Vector__XXX
 SG_ VCRIGHT_a267_seatTrackHCEncStlDb m4 : 30|1@1+ (1,0) [0|1] "" Vector__XXX
 SG_ VCRIGHT_a268_seatBackHCEncStlDbg m4 : 31|1@1+ (1,0) [0|1] "" Vector__XXX
 SG_ VCRIGHT_a269_seatTiltHCEncStlDbg m4 : 32|1@1+ (1,0) [0|1] "" Vector__XXX
 SG_ VCRIGHT_a270_seatLiftHCEncStlDbg m4 : 33|1@1+ (1,0) [0|1] "" Vector__XXX
 SG_ VCRIGHT_a271_THSSensorFault m4 : 34|1@1+ (1,0) [0|1] "" Vector__XXX
 SG_ VCRIGHT_a272_vhclPwrStateMsmtch m4 : 35|1@1+ (1,0) [0|1] "" Vector__XXX
 SG_ VCRIGHT_a273_handleStuckActiveF m4 : 36|1@1+ (1,0) [0|1] "" Vector__XXX
 SG_ VCRIGHT_a274_handleStuckActiveR m4 : 37|1@1+ (1,0) [0|1] "" Vector__XXX
 SG_ VCRIGHT_a275_rightTurnLightFault m4 : 38|1@1+ (1,0) [0|1] "" Vector__XXX
 SG_ VCRIGHT_a276_mirrorDebug m4 : 39|1@1+ (1,0) [0|1] "" Vector__XXX
 SG_ VCRIGHT_a277_BLERightUnderVoltag m4 : 40|1@1+ (1,0) [0|1] "" Vector__XXX
 SG_ VCRIGHT_a278_hvacPtcHeatingUnava m4 : 41|1@1+ (1,0) [0|1] "" Vector__XXX
 SG_ VCRIGHT_a279_trunkFailedToClose m4 : 42|1@1+ (1,0) [0|1] "" Vector__XXX
 SG_ VCRIGHT_a280_latchDidNotDisarmF m4 : 43|1@1+ (1,0) [0|1] "" Vector__XXX
 SG_ VCRIGHT_a281_latchDidNotDisarmR m4 : 44|1@1+ (1,0) [0|1] "" Vector__XXX
 SG_ VCRIGHT_a282_latchUnexpectedArmF m4 : 45|1@1+ (1,0) [0|1] "" Vector__XXX
 SG_ VCRIGHT_a283_latchUnexpectedArmR m4 : 46|1@1+ (1,0) [0|1] "" Vector__XXX
 SG_ VCRIGHT_a284_gloveboxUnderCurren m4 : 47|1@1+ (1,0) [0|1] "" Vector__XXX
 SG_ VCRIGHT_a285_gloveboxOverCurrent m4 : 48|1@1+ (1,0) [0|1] "" Vector__XXX
 SG_ VCRIGHT_a286_windowSpeedInvalidF m4 : 49|1@1+ (1,0) [0|1] "" Vector__XXX
 SG_ VCRIGHT_a287_windowSpeedInvalidR m4 : 50|1@1+ (1,0) [0|1] "" Vector__XXX
 SG_ VCRIGHT_a288_handlePWMPeriodF m4 : 51|1@1+ (1,0) [0|1] "" Vector__XXX
 SG_ VCRIGHT_a289_handlePWMPeriodR m4 : 52|1@1+ (1,0) [0|1] "" Vector__XXX
 SG_ VCRIGHT_a290_occupancyFaultedFro m4 : 53|1@1+ (1,0) [0|1] "" Vector__XXX
 SG_ VCRIGHT_a291_buckleFaultedFront m4 : 54|1@1+ (1,0) [0|1] "" Vector__XXX
 SG_ VCRIGHT_a292_buckleFaultedRearC m4 : 55|1@1+ (1,0) [0|1] "" Vector__XXX
 SG_ VCRIGHT_a293_buckleFaultedRearR m4 : 56|1@1+ (1,0) [0|1] "" Vector__XXX
 SG_ VCRIGHT_a294_occupancyFaultedRea m4 : 57|1@1+ (1,0) [0|1] "" Vector__XXX
 SG_ VCRIGHT_a295_occupancyFaulted3Ro m4 : 58|1@1+ (1,0) [0|1] "" Vector__XXX
 SG_ VCRIGHT_a296_occupancyFaulted3Ro m4 : 59|1@1+ (1,0) [0|1] "" Vector__XXX
 SG_ VCRIGHT_a297_seatBelowMinPumpTmp m4 : 60|1@1+ (1,0) [0|1] "" Vector__XXX
 SG_ VCRIGHT_a298_buckleFaulted3RowL m4 : 61|1@1+ (1,0) [0|1] "" Vector__XXX
 SG_ VCRIGHT_a299_buckleFaulted3RowR m4 : 62|1@1+ (1,0) [0|1] "" Vector__XXX
 SG_ VCRIGHT_a300_VCFRONT1_MIA m4 : 63|1@1+ (1,0) [0|1] "" Vector__XXX
 SG_ VCRIGHT_a301_airwaveRightVertica m5 : 4|1@1+ (1,0) [0|1] "" Vector__XXX
 SG_ VCRIGHT_a302_airwaveRightVertica m5 : 5|1@1+ (1,0) [0|1] "" Vector__XXX
 SG_ VCRIGHT_a303_eFuseMgmtWindowLift m5 : 6|1@1+ (1,0) [0|1] "" Vector__XXX
 SG_ VCRIGHT_a304_frontIntHandleUnexp m5 : 7|1@1+ (1,0) [0|1] "" Vector__XXX
 SG_ VCRIGHT_a305_rearIntHandleUnexpe m5 : 8|1@1+ (1,0) [0|1] "" Vector__XXX
 SG_ VCRIGHT_a306_handleDisconnectedF m5 : 9|1@1+ (1,0) [0|1] "" Vector__XXX
 SG_ VCRIGHT_a307_handleDisconnectedR m5 : 10|1@1+ (1,0) [0|1] "" Vector__XXX
 SG_ VCRIGHT_a308_airwaveRightLateral m5 : 11|1@1+ (1,0) [0|1] "" Vector__XXX
 SG_ VCRIGHT_a310_mirrorFoldStall m5 : 13|1@1+ (1,0) [0|1] "" Vector__XXX
 SG_ VCRIGHT_a311_rightBrakeLightFaul m5 : 14|1@1+ (1,0) [0|1] "" Vector__XXX
 SG_ VCRIGHT_a312_rightTailLightFault m5 : 15|1@1+ (1,0) [0|1] "" Vector__XXX
 SG_ VCRIGHT_a313_rightFootwellLightF m5 : 16|1@1+ (1,0) [0|1] "" Vector__XXX
 SG_ VCRIGHT_a314_rightMapPocketLight m5 : 17|1@1+ (1,0) [0|1] "" Vector__XXX
 SG_ VCRIGHT_a315_rightInteriorTrunkL m5 : 18|1@1+ (1,0) [0|1] "" Vector__XXX
 SG_ VCRIGHT_a316_mirrorPrematureFold m5 : 19|1@1+ (1,0) [0|1] "" Vector__XXX
 SG_ VCRIGHT_a317_epbmLimpModeEnabled m5 : 20|1@1+ (1,0) [0|1] "" Vector__XXX
 SG_ VCRIGHT_a318_leftExteriorTrunkLi m5 : 21|1@1+ (1,0) [0|1] "" Vector__XXX
 SG_ VCRIGHT_a319_rightExteriorTrunkL m5 : 22|1@1+ (1,0) [0|1] "" Vector__XXX
 SG_ VCRIGHT_a320_windowReportCracked m5 : 23|1@1+ (1,0) [0|1] "" Vector__XXX
 SG_ VCRIGHT_a321_windowRezeroedDebug m5 : 24|1@1+ (1,0) [0|1] "" Vector__XXX
 SG_ VCRIGHT_a322_windowRezeroedDebug m5 : 25|1@1+ (1,0) [0|1] "" Vector__XXX
 SG_ VCRIGHT_a323_mirrorCalibrated m5 : 26|1@1+ (1,0) [0|1] "" Vector__XXX
 SG_ VCRIGHT_a324_mirrorHeatFault m5 : 27|1@1+ (1,0) [0|1] "" Vector__XXX
 SG_ VCRIGHT_a325_airwaveLeftVertical m5 : 28|1@1+ (1,0) [0|1] "" Vector__XXX
 SG_ VCRIGHT_a326_airwaveLeftLateralU m5 : 29|1@1+ (1,0) [0|1] "" Vector__XXX
 SG_ VCRIGHT_a327_airwaveLeftLateralW m5 : 30|1@1+ (1,0) [0|1] "" Vector__XXX
 SG_ VCRIGHT_a328_airwaveLeftVertical m5 : 31|1@1+ (1,0) [0|1] "" Vector__XXX
 SG_ VCRIGHT_a329_airwaveRightLateral m5 : 32|1@1+ (1,0) [0|1] "" Vector__XXX
 SG_ VCRIGHT_a330_shortDropFailedF m5 : 33|1@1+ (1,0) [0|1] "" Vector__XXX
 SG_ VCRIGHT_a331_shortDropFailedR m5 : 34|1@1+ (1,0) [0|1] "" Vector__XXX
 SG_ VCRIGHT_a336_windowDropRevTherma m5 : 39|1@1+ (1,0) [0|1] "" Vector__XXX
 SG_ VCRIGHT_a337_windowDropRevTherma m5 : 40|1@1+ (1,0) [0|1] "" Vector__XXX
 SG_ VCRIGHT_a342_rearDefrostDisabled m5 : 45|1@1+ (1,0) [0|1] "" Vector__XXX
 SG_ VCRIGHT_a343_rearDefrostUndercur m5 : 46|1@1+ (1,0) [0|1] "" Vector__XXX
 SG_ VCRIGHT_a344_rearDefrostOvercurr m5 : 47|1@1+ (1,0) [0|1] "" Vector__XXX
 SG_ VCRIGHT_a345_HVACPTCHeaterPwrEFu m5 : 48|1@1+ (1,0) [0|1] "" Vector__XXX
 SG_ VCRIGHT_a346_cabinRadarEFuseFaul m5 : 49|1@1+ (1,0) [0|1] "" Vector__XXX
 SG_ VCRIGHT_a347_nonContMonitorClear m5 : 50|1@1+ (1,0) [0|1] "" Vector__XXX
 SG_ VCRIGHT_a352_audioCurrentSpikeDa m5 : 55|1@1+ (1,0) [0|1] "" Vector__XXX
 SG_ VCRIGHT_a355_hvacLHBleedWarning m5 : 58|1@1+ (1,0) [0|1] "" Vector__XXX
 SG_ VCRIGHT_a356_hvacRHBleedWarning m5 : 59|1@1+ (1,0) [0|1] "" Vector__XXX
 SG_ VCRIGHT_a357_hvacLHVaneWarning m5 : 60|1@1+ (1,0) [0|1] "" Vector__XXX
 SG_ VCRIGHT_a358_hvacRHVaneWarning m5 : 61|1@1+ (1,0) [0|1] "" Vector__XXX
 SG_ VCRIGHT_a359_hvacUpperModeWarnin m5 : 62|1@1+ (1,0) [0|1] "" Vector__XXX
 SG_ VCRIGHT_a360_detectedStationaryW m5 : 63|1@1+ (1,0) [0|1] "" Vector__XXX
 SG_ VCRIGHT_a361_stationaryThreshold m6 : 4|1@1+ (1,0) [0|1] "" Vector__XXX
 SG_ VCRIGHT_a362_movingThresholdsInc m6 : 5|1@1+ (1,0) [0|1] "" Vector__XXX
 SG_ VCRIGHT_a363_hvacLowerModeWarnin m6 : 6|1@1+ (1,0) [0|1] "" Vector__XXX
 SG_ VCRIGHT_a364_hvacIntakeWarning m6 : 7|1@1+ (1,0) [0|1] "" Vector__XXX
 SG_ VCRIGHT_a365_pitchUnlatchDisable m6 : 8|1@1+ (1,0) [0|1] "" Vector__XXX
 SG_ VCRIGHT_a366_trunkLatchUnhomed m6 : 9|1@1+ (1,0) [0|1] "" Vector__XXX
 SG_ VCRIGHT_a367_trunkLatchSwFault m6 : 10|1@1+ (1,0) [0|1] "" Vector__XXX
 SG_ VCRIGHT_a368_ductLeftLowerTempSn m6 : 11|1@1+ (1,0) [0|1] "" Vector__XXX
 SG_ VCRIGHT_a369_ductRightLowerTempS m6 : 12|1@1+ (1,0) [0|1] "" Vector__XXX
 SG_ VCRIGHT_a370_seat2RowPitchUnlatc m6 : 13|1@1+ (1,0) [0|1] "" Vector__XXX
 SG_ VCRIGHT_a371_seat2RowTrackUnlatc m6 : 14|1@1+ (1,0) [0|1] "" Vector__XXX
 SG_ VCRIGHT_a372_seat2RowBackrestUnl m6 : 15|1@1+ (1,0) [0|1] "" Vector__XXX
 SG_ VCRIGHT_a373_windowSwOpenReqInDo m6 : 16|1@1+ (1,0) [0|1] "" Vector__XXX
 SG_ VCRIGHT_a375_windowPinchOverride m6 : 18|1@1+ (1,0) [0|1] "" Vector__XXX
 SG_ VCRIGHT_a376_seat2RowBridgeCurre m6 : 19|1@1+ (1,0) [0|1] "" Vector__XXX
 SG_ VCRIGHT_a377_ambientTempSns m6 : 20|1@1+ (1,0) [0|1] "" Vector__XXX
 SG_ VCRIGHT_a378_ductLeftUpperTempSn m6 : 21|1@1+ (1,0) [0|1] "" Vector__XXX
 SG_ VCRIGHT_a379_ductRightUpperTempS m6 : 22|1@1+ (1,0) [0|1] "" Vector__XXX
 SG_ VCRIGHT_a380_reverseLightFault m6 : 23|1@1+ (1,0) [0|1] "" Vector__XXX
 SG_ VCRIGHT_a381_rearFogLightFault m6 : 24|1@1+ (1,0) [0|1] "" Vector__XXX
 SG_ VCRIGHT_a382_leftLiftgateTailLig m6 : 25|1@1+ (1,0) [0|1] "" Vector__XXX
 SG_ VCRIGHT_a383_hvacRearWarning m6 : 26|1@1+ (1,0) [0|1] "" Vector__XXX
 SG_ VCRIGHT_a385_glareShieldHeaterUn m6 : 28|1@1+ (1,0) [0|1] "" Vector__XXX
 SG_ VCRIGHT_a406_aptivOCSMIA m6 : 49|1@1+ (1,0) [0|1] "" Vector__XXX
 SG_ VCRIGHT_a407_aptivOCSInterfaceEr m6 : 50|1@1+ (1,0) [0|1] "" Vector__XXX
 SG_ VCRIGHT_a408_aptivOCSDeviceError m6 : 51|1@1+ (1,0) [0|1] "" Vector__XXX
 SG_ VCRIGHT_a409_aptivOCSDeviceError m6 : 52|1@1+ (1,0) [0|1] "" Vector__XXX
 SG_ VCRIGHT_a411_undervoltageSelfTes m6 : 54|1@1+ (1,0) [0|1] "" Vector__XXX
 SG_ VCRIGHT_a412_rightBrakeTailLight m6 : 55|1@1+ (1,0) [0|1] "" Vector__XXX
 SG_ VCRIGHT_a413_centerHighMountStop m6 : 56|1@1+ (1,0) [0|1] "" Vector__XXX
 SG_ VCRIGHT_a414_rearFasciaReverseLi m6 : 57|1@1+ (1,0) [0|1] "" Vector__XXX
 SG_ VCRIGHT_a415_rearFasciaFogLightF m6 : 58|1@1+ (1,0) [0|1] "" Vector__XXX
 SG_ VCRIGHT_a416_rearFasciaTailLight m6 : 59|1@1+ (1,0) [0|1] "" Vector__XXX
 SG_ VCRIGHT_a417_rearFasciaLeftTurnL m6 : 60|1@1+ (1,0) [0|1] "" Vector__XXX
 SG_ VCRIGHT_a418_rearFasciaRightTurn m6 : 61|1@1+ (1,0) [0|1] "" Vector__XXX
 SG_ VCRIGHT_a419_tailFasciaLeftLight m6 : 62|1@1+ (1,0) [0|1] "" Vector__XXX
 SG_ VCRIGHT_a420_tailFasciaRightLigh m6 : 63|1@1+ (1,0) [0|1] "" Vector__XXX
 SG_ VCRIGHT_a421_leftTailLightFault m7 : 4|1@1+ (1,0) [0|1] "" Vector__XXX
 SG_ VCRIGHT_a422_undervoltageSelfTes m7 : 5|1@1+ (1,0) [0|1] "" Vector__XXX
 SG_ VCRIGHT_a426_seatAbuseMotorWarn m7 : 9|1@1+ (1,0) [0|1] "" Vector__XXX
 SG_ VCRIGHT_a427_seatAbuseMotorStop m7 : 10|1@1+ (1,0) [0|1] "" Vector__XXX
 SG_ VCRIGHT_a428_seatAbuseBufferWarn m7 : 11|1@1+ (1,0) [0|1] "" Vector__XXX
 SG_ VCRIGHT_a429_seatAbuseBufferFull m7 : 12|1@1+ (1,0) [0|1] "" Vector__XXX
 SG_ VCRIGHT_a444_drv8703Fault m7 : 27|1@1+ (1,0) [0|1] "" Vector__XXX
 SG_ VCRIGHT_a445_drv8703SpiFaultDBG m7 : 28|1@1+ (1,0) [0|1] "" Vector__XXX
 SG_ VCRIGHT_a446_cabinHVACUnavailabl m7 : 29|1@1+ (1,0) [0|1] "" Vector__XXX
 SG_ VCRIGHT_a448_manualHVACAlert m7 : 31|1@1+ (1,0) [0|1] "" Vector__XXX
 SG_ VCRIGHT_a450_ptcForcedOutOfSeqRo m7 : 33|1@1+ (1,0) [0|1] "" Vector__XXX
 SG_ VCRIGHT_a451_ptcSeqRodOutOfRetri m7 : 34|1@1+ (1,0) [0|1] "" Vector__XXX
 SG_ VCRIGHT_a454_ptcHeaterBadRodDete m7 : 37|1@1+ (1,0) [0|1] "" Vector__XXX
 SG_ VCRIGHT_a482_NCV77XXFault m8 : 5|1@1+ (1,0) [0|1] "" Vector__XXX
 SG_ VCRIGHT_a483_rightTurnLightFault m8 : 6|1@1+ (1,0) [0|1] "" Vector__XXX
 SG_ VCRIGHT_a484_rightBrakeLightFaul m8 : 7|1@1+ (1,0) [0|1] "" Vector__XXX
 SG_ VCRIGHT_a485_leftTailLightFaultU m8 : 8|1@1+ (1,0) [0|1] "" Vector__XXX
 SG_ VCRIGHT_a486_rightTailLightFault m8 : 9|1@1+ (1,0) [0|1] "" Vector__XXX
 SG_ VCRIGHT_a487_centerHighMountStop m8 : 10|1@1+ (1,0) [0|1] "" Vector__XXX
 SG_ VCRIGHT_a488_undervoltageSelfTes m8 : 11|1@1+ (1,0) [0|1] "" Vector__XXX
 SG_ VCRIGHT_a489_undervoltageSelfTes m8 : 12|1@1+ (1,0) [0|1] "" Vector__XXX
 SG_ VCRIGHT_a490_vehicleOccupiedOnOT m8 : 13|1@1+ (1,0) [0|1] "" Vector__XXX
 SG_ VCRIGHT_a491_BPillarCameraHeater m8 : 14|1@1+ (1,0) [0|1] "" Vector__XXX
 SG_ VCRIGHT_a492_uvSelfTestLoadUnatt m8 : 15|1@1+ (1,0) [0|1] "" Vector__XXX
 SG_ VCRIGHT_a496_gloveboxOpenFailed m8 : 19|1@1+ (1,0) [0|1] "" Vector__XXX
 SG_ VCRIGHT_a497_CANMsgMACVerificati m8 : 20|1@1+ (1,0) [0|1] "" Vector__XXX
 SG_ VCRIGHT_a498_CANMsgMACVerificati m8 : 21|1@1+ (1,0) [0|1] "" Vector__XXX
 SG_ VCRIGHT_a499_epbmInvalidateCdp m8 : 22|1@1+ (1,0) [0|1] "" Vector__XXX
 SG_ VCRIGHT_a510_3RowSeatUncalibrate m8 : 33|1@1+ (1,0) [0|1] "" Vector__XXX
 SG_ VCRIGHT_a511_3RowSeatPositionNon m8 : 34|1@1+ (1,0) [0|1] "" Vector__XXX
 SG_ VCRIGHT_a512_3RowSeatAbsPosOffse m8 : 35|1@1+ (1,0) [0|1] "" Vector__XXX
 SG_ VCRIGHT_a513_3RowSeatObstacleDet m8 : 36|1@1+ (1,0) [0|1] "" Vector__XXX
 SG_ VCRIGHT_a514_3RowSeatTempHigh m8 : 37|1@1+ (1,0) [0|1] "" Vector__XXX
 SG_ VCRIGHT_a515_3RowSeatAbsPosSenso m8 : 38|1@1+ (1,0) [0|1] "" Vector__XXX
 SG_ VCRIGHT_a516_3RowSeatStatsFromLa m8 : 39|1@1+ (1,0) [0|1] "" Vector__XXX
 SG_ VCRIGHT_a517_3RowSeatRequestWhil m8 : 40|1@1+ (1,0) [0|1] "" Vector__XXX
 SG_ VCRIGHT_a518_3RowSeatClashAvoida m8 : 41|1@1+ (1,0) [0|1] "" Vector__XXX
 SG_ VCRIGHT_a519_3RowSeatOverfolded m8 : 42|1@1+ (1,0) [0|1] "" Vector__XXX
 SG_ VCRIGHT_a520_configMismatch m8 : 43|1@1+ (1,0) [0|1] "" Vector__XXX
 SG_ VCRIGHT_a525_LVBatterySWMisconfi m8 : 48|1@1+ (1,0) [0|1] "" Vector__XXX
 SG_ VCRIGHT_a526_pcbaOverTemperature m8 : 49|1@1+ (1,0) [0|1] "" Vector__XXX
 SG_ VCRIGHT_a527_continuousFeedUnexp m8 : 50|1@1+ (1,0) [0|1] "" Vector__XXX
 SG_ VCRIGHT_a528_unableToRunStuckOnT m8 : 51|1@1+ (1,0) [0|1] "" Vector__XXX
 SG_ VCRIGHT_a529_airflowFeedBackMode m8 : 52|1@1+ (1,0) [0|1] "" Vector__XXX
 SG_ VCRIGHT_a531_airflowModelTmpComp m8 : 54|1@1+ (1,0) [0|1] "" Vector__XXX
 SG_ VCRIGHT_a532_airflowModelFeedFor m8 : 55|1@1+ (1,0) [0|1] "" Vector__XXX
 SG_ VCRIGHT_a533_cabinModelDebug m8 : 56|1@1+ (1,0) [0|1] "" Vector__XXX
 SG_ VCRIGHT_a537_solarCalcsNotNomina m8 : 60|1@1+ (1,0) [0|1] "" Vector__XXX
 SG_ VCRIGHT_a538_hvacSystemNotNomina m8 : 61|1@1+ (1,0) [0|1] "" Vector__XXX
 SG_ VCRIGHT_a539_dogModeMonitorTrip m8 : 62|1@1+ (1,0) [0|1] "" Vector__XXX
 SG_ VCRIGHT_a540_hvacActuatorDitherD m8 : 63|1@1+ (1,0) [0|1] "" Vector__XXX
 SG_ VCRIGHT_a542_steeringWheelHeatin m9 : 5|1@1+ (1,0) [0|1] "" Vector__XXX
 SG_ VCRIGHT_a545_LVBatteryTypeUnknow m9 : 8|1@1+ (1,0) [0|1] "" Vector__XXX
 SG_ VCRIGHT_a546_mirrorFoldTypeChang m9 : 9|1@1+ (1,0) [0|1] "" Vector__XXX
 SG_ VCRIGHT_a550_ambientTempDelta m9 : 13|1@1+ (1,0) [0|1] "" Vector__XXX
 SG_ VCRIGHT_a551_interiorDoorRequest m9 : 14|1@1+ (1,0) [0|1] "" Vector__XXX
 SG_ VCRIGHT_a555_RCM2_MIA m9 : 18|1@1+ (1,0) [0|1] "" Vector__XXX
 SG_ VCRIGHT_a556_rcmReportedOCSError m9 : 19|1@1+ (1,0) [0|1] "" Vector__XXX
 SG_ VCRIGHT_a560_2RowSeatUncalibrate m9 : 23|1@1+ (1,0) [0|1] "" Vector__XXX
 SG_ VCRIGHT_a561_2RowSeatPositionNon m9 : 24|1@1+ (1,0) [0|1] "" Vector__XXX
 SG_ VCRIGHT_a562_2RowSeatAbsPosOffse m9 : 25|1@1+ (1,0) [0|1] "" Vector__XXX
 SG_ VCRIGHT_a563_2RowSeatObstacleDet m9 : 26|1@1+ (1,0) [0|1] "" Vector__XXX
 SG_ VCRIGHT_a564_2RowSeatTempHigh m9 : 27|1@1+ (1,0) [0|1] "" Vector__XXX
 SG_ VCRIGHT_a565_2RowSeatAbsPosSenso m9 : 28|1@1+ (1,0) [0|1] "" Vector__XXX
 SG_ VCRIGHT_a566_2RowSeatStatsFromLa m9 : 29|1@1+ (1,0) [0|1] "" Vector__XXX
 SG_ VCRIGHT_a567_2RowSeatRequestWhil m9 : 30|1@1+ (1,0) [0|1] "" Vector__XXX
 SG_ VCRIGHT_a568_2RowSeatClashAvoida m9 : 31|1@1+ (1,0) [0|1] "" Vector__XXX
 SG_ VCRIGHT_a569_2RowSeatOverfolded m9 : 32|1@1+ (1,0) [0|1] "" Vector__XXX
 SG_ VCRIGHT_a570_seatHeatDisabledF m9 : 33|1@1+ (1,0) [0|1] "" Vector__XXX
 SG_ VCRIGHT_a571_seatHeatDisabledRea m9 : 34|1@1+ (1,0) [0|1] "" Vector__XXX
 SG_ VCRIGHT_a572_seatHeatDisabledRea m9 : 35|1@1+ (1,0) [0|1] "" Vector__XXX
 SG_ VCRIGHT_a573_seatHeatDisabledRea m9 : 36|1@1+ (1,0) [0|1] "" Vector__XXX
 SG_ VCRIGHT_a574_2RowSeatStatsFromLa m9 : 37|1@1+ (1,0) [0|1] "" Vector__XXX
 SG_ VCRIGHT_a575_3RowSeatStatsFromLa m9 : 38|1@1+ (1,0) [0|1] "" Vector__XXX
 SG_ VCRIGHT_a577_bsiHardwareIssue m9 : 40|1@1+ (1,0) [0|1] "" Vector__XXX
 SG_ VCRIGHT_a578_RGBLightFault m9 : 41|1@1+ (1,0) [0|1] "" Vector__XXX
 SG_ VCRIGHT_a579_liftgateFollowerUne m9 : 42|1@1+ (1,0) [0|1] "" Vector__XXX
 SG_ VCRIGHT_a580_debugLiftgateFollow m9 : 43|1@1+ (1,0) [0|1] "" Vector__XXX
 SG_ VCRIGHT_a583_doorRemoteUnlatched m9 : 46|1@1+ (1,0) [0|1] "" Vector__XXX
 SG_ VCRIGHT_a584_doorRemoteUnlatched m9 : 47|1@1+ (1,0) [0|1] "" Vector__XXX
 SG_ VCRIGHT_a585_doorRemoteUnlatchFa m9 : 48|1@1+ (1,0) [0|1] "" Vector__XXX
 SG_ VCRIGHT_a586_doorRemoteUnlatchFa m9 : 49|1@1+ (1,0) [0|1] "" Vector__XXX
 SG_ VCRIGHT_a587_VCSEAT2L_MIA m9 : 50|1@1+ (1,0) [0|1] "" Vector__XXX
 SG_ VCRIGHT_a588_VCSEAT2R_MIA m9 : 51|1@1+ (1,0) [0|1] "" Vector__XXX
 SG_ VCRIGHT_a589_defogSysDriverlessS m9 : 52|1@1+ (1,0) [0|1] "" Vector__XXX
 SG_ VCRIGHT_a590_seatEncStallThighSu m9 : 53|1@1+ (1,0) [0|1] "" Vector__XXX
 SG_ VCRIGHT_a591_seatCurrUnderThighS m9 : 54|1@1+ (1,0) [0|1] "" Vector__XXX
 SG_ VCRIGHT_a592_seatUncalThighSuppo m9 : 55|1@1+ (1,0) [0|1] "" Vector__XXX
 SG_ VCRIGHT_a593_seatEncOverThighSup m9 : 56|1@1+ (1,0) [0|1] "" Vector__XXX
 SG_ VCRIGHT_a594_seatThighSupportSta m9 : 57|1@1+ (1,0) [0|1] "" Vector__XXX
 SG_ VCRIGHT_a595_seatThighSupportHCE m9 : 58|1@1+ (1,0) [0|1] "" Vector__XXX
 SG_ VCRIGHT_a596_frontDoorLatchUnexp m9 : 59|1@1+ (1,0) [0|1] "" Vector__XXX
 SG_ VCRIGHT_a597_rearDoorLatchUnexpe m9 : 60|1@1+ (1,0) [0|1] "" Vector__XXX
 SG_ VCRIGHT_a598_childModeMonitorTri m9 : 61|1@1+ (1,0) [0|1] "" Vector__XXX
 SG_ VCRIGHT_a599_LVBatteryTypeUnsupp m9 : 62|1@1+ (1,0) [0|1] "" Vector__XXX
 SG_ VCRIGHT_a601_wakeToOpenDoorDbg m10 : 4|1@1+ (1,0) [0|1] "" Vector__XXX
 SG_ VCRIGHT_a605_CANMsgMACVerificati m10 : 8|1@1+ (1,0) [0|1] "" Vector__XXX
 SG_ VCRIGHT_a617_APP_MIA m10 : 20|1@1+ (1,0) [0|1] "" Vector__XXX

BO_ 1795 VCRIGHT_debugThermal10Hz: 8 VCRIGHT
 SG_ VCRIGHT_debugThermal10HzIndex M : 0|4@1+ (1,0) [0|15] "" Vector__XXX
 SG_ VCRIGHT_hvacPanelFloorSplitRow1 m2 : 8|8@1+ (0.4,0) [0|100] "%" Vector__XXX
 SG_ VCRIGHT_hvacDefrostPercent m2 : 16|8@1+ (0.4,0) [0|100] "%" Vector__XXX
 SG_ VCRIGHT_hvacRow2Percent m2 : 24|8@1+ (0.4,0) [0|100] "%" Vector__XXX
 SG_ VCRIGHT_hvacPanelFloorSplitRow2 m2 : 32|8@1+ (0.4,0) [0|100] "%" Vector__XXX
 SG_ VCRIGHT_hvacFreshMassCounter m2 : 40|12@1+ (10,0) [0|40000] "kg" Vector__XXX
 SG_ VCRIGHT_hvacRecircMassCounter m2 : 52|12@1+ (10,0) [0|40000] "kg" Vector__XXX
 SG_ VCRIGHT_setTempAdjustmentLeft m3 : 8|7@1+ (0.1,0) [0|12] "degC" Vector__XXX
 SG_ VCRIGHT_setTempAdjustmentRight m3 : 16|7@1+ (0.1,0) [0|12] "degC" Vector__XXX
 SG_ VCRIGHT_hvacLHVaneVelocity m3 : 24|8@1- (0.8,0) [-100|100] "deg/s" Vector__XXX
 SG_ VCRIGHT_hvacRHVaneVelocity m3 : 32|8@1- (0.8,0) [-100|100] "deg/s" Vector__XXX
 SG_ VCRIGHT_hvacVehicleSpeed m3 : 40|5@1+ (5,0) [0|150] "kph" Vector__XXX
 SG_ VCRIGHT_hvacMassflowCompensated m3 : 47|8@1+ (1.5,0) [0|250] "g/s" Vector__XXX
 SG_ VCRIGHT_PTCcenterPowerLeft m5 : 8|6@1+ (30,0) [0|1800] "W" Vector__XXX
 SG_ VCRIGHT_PTCouterPowerLeft m5 : 16|6@1+ (30,0) [0|1800] "W" Vector__XXX
 SG_ VCRIGHT_PTCinnerPowerLeft m5 : 24|6@1+ (30,0) [0|1800] "W" Vector__XXX
 SG_ VCRIGHT_PTCcenterPowerRight m5 : 32|6@1+ (30,0) [0|1800] "W" Vector__XXX
 SG_ VCRIGHT_PTCouterPowerRight m5 : 40|6@1+ (30,0) [0|1800] "W" Vector__XXX
 SG_ VCRIGHT_PTCinnerPowerRight m5 : 48|6@1+ (30,0) [0|1800] "W" Vector__XXX
 SG_ VCRIGHT_PTCcenterStoneTempLeft m6 : 8|8@1+ (2,-70) [-70|438] "degC" Vector__XXX
 SG_ VCRIGHT_PTCcenterStoneTempRight m6 : 16|8@1+ (2,-70) [-70|438] "degC" Vector__XXX
 SG_ VCRIGHT_PTCinnerStoneTempLeft m6 : 24|8@1+ (2,-70) [-70|438] "degC" Vector__XXX
 SG_ VCRIGHT_PTCinnerStoneTempRight m6 : 32|8@1+ (2,-70) [-70|438] "degC" Vector__XXX
 SG_ VCRIGHT_PTCouterStoneTempLeft m7 : 8|8@1+ (2,-70) [-70|438] "degC" Vector__XXX
 SG_ VCRIGHT_PTCouterRodTempLeft m7 : 16|8@1+ (2,-70) [-70|438] "degC" Vector__XXX
 SG_ VCRIGHT_PTCouterAirTempLeft m7 : 24|8@1+ (2,-70) [-70|438] "degC" Vector__XXX
 SG_ VCRIGHT_PTCcenterRodTempLeft m7 : 32|8@1+ (2,-70) [-70|438] "degC" Vector__XXX
 SG_ VCRIGHT_PTCinnerRodTempLeft m7 : 40|8@1+ (2,-70) [-70|438] "degC" Vector__XXX
 SG_ VCRIGHT_PTCcenterAirTempLeft m7 : 48|8@1+ (2,-70) [-70|438] "degC" Vector__XXX
 SG_ VCRIGHT_PTCinnerAirTempLeft m7 : 56|8@1+ (2,-70) [-70|438] "degC" Vector__XXX
 SG_ VCRIGHT_PTCouterStoneTempRight m8 : 8|8@1+ (2,-70) [-70|438] "degC" Vector__XXX
 SG_ VCRIGHT_PTCouterRodTempRight m8 : 16|8@1+ (2,-70) [-70|438] "degC" Vector__XXX
 SG_ VCRIGHT_PTCouterAirTempRight m8 : 24|8@1+ (2,-70) [-70|438] "degC" Vector__XXX
 SG_ VCRIGHT_PTCcenterRodTempRight m8 : 32|8@1+ (2,-70) [-70|438] "degC" Vector__XXX
 SG_ VCRIGHT_PTCinnerRodTempRight m8 : 40|8@1+ (2,-70) [-70|438] "degC" Vector__XXX
 SG_ VCRIGHT_PTCcenterAirTempRight m8 : 48|8@1+ (2,-70) [-70|438] "degC" Vector__XXX
 SG_ VCRIGHT_PTCinnerAirTempRight m8 : 56|8@1+ (2,-70) [-70|438] "degC" Vector__XXX

BO_ 259 VCRIGHT_doorStatus: 8 VCRIGHT
 SG_ VCRIGHT_doorClosureStatusFront : 0|4@1+ (1,0) [1|15] "" Vector__XXX
 SG_ VCRIGHT_doorClosureStatusRear : 4|4@1+ (1,0) [1|15] "" Vector__XXX
 SG_ VCRIGHT_frontLatchSwitch : 8|1@1+ (1,0) [0|1] "" Vector__XXX
 SG_ VCRIGHT_rearLatchSwitch : 9|1@1+ (1,0) [0|1] "" Vector__XXX
 SG_ VCRIGHT_frontHandlePulled : 10|1@1+ (1,0) [0|1] "" Vector__XXX
 SG_ VCRIGHT_rearHandlePulled : 11|1@1+ (1,0) [0|1] "" Vector__XXX
 SG_ VCRIGHT_frontRelActuatorSwitch : 12|1@1+ (1,0) [0|1] "" Vector__XXX
 SG_ VCRIGHT_rearRelActuatorSwitch : 13|1@1+ (1,0) [0|1] "" Vector__XXX
 SG_ VCRIGHT_frontLatchStatus : 14|4@1+ (1,0) [1|15] "" Vector__XXX
 SG_ VCRIGHT_rearLatchStatus : 18|4@1+ (1,0) [1|15] "" Vector__XXX
 SG_ VCRIGHT_lastDoorReqSourceFront : 22|3@1+ (1,0) [0|7] "" Vector__XXX
 SG_ VCRIGHT_lastDoorReqSourceRear : 25|3@1+ (1,0) [0|7] "" Vector__XXX
 SG_ VCRIGHT_frontIntSwitchFaulted : 28|1@1+ (1,0) [0|1] "" Vector__XXX
 SG_ VCRIGHT_rearIntSwitchFaulted : 29|1@1+ (1,0) [0|1] "" Vector__XXX
 SG_ VCRIGHT_frontHandlePulledPersist : 30|1@1+ (1,0) [0|1] "" Vector__XXX
 SG_ VCRIGHT_frontIntSwitchPressed : 31|1@1+ (1,0) [0|1] "" Vector__XXX
 SG_ VCRIGHT_rearIntSwitchPressed : 32|1@1+ (1,0) [0|1] "" Vector__XXX
 SG_ VCRIGHT_mirrorTiltXPosition : 33|8@1+ (0.02,0) [0|5] "V" Vector__XXX
 SG_ VCRIGHT_mirrorTiltYPosition : 41|8@1+ (0.02,0) [0|5] "V" Vector__XXX
 SG_ VCRIGHT_mirrorState : 49|3@1+ (1,0) [0|7] "" Vector__XXX
 SG_ VCRIGHT_mirrorFoldState : 52|3@1+ (1,0) [0|7] "" Vector__XXX
 SG_ VCRIGHT_mirrorDipped : 55|1@1+ (1,0) [0|1] "" Vector__XXX
 SG_ VCRIGHT_trunkLatchStatus : 56|4@1+ (1,0) [1|15] "" Vector__XXX
 SG_ VCRIGHT_mirrorRecallState : 60|3@1+ (1,0) [0|7] "" Vector__XXX
 SG_ VCRIGHT_rearHandlePulledPersist : 63|1@1+ (1,0) [0|1] "" Vector__XXX

BO_ 2010 VCRIGHT_doorStatus2: 8 VCRIGHT
 SG_ VCRIGHT_doorStatus2Index M : 0|1@1+ (1,0) [0|1] "" Vector__XXX
 SG_ VCRIGHT_frontLatchRelDuty m1 : 8|8@1+ (1,0) [0|255] "%" Vector__XXX
 SG_ VCRIGHT_BPillarCameraHeaterState m1 : 16|3@1+ (1,0) [1|7] "" Vector__XXX
 SG_ VCRIGHT_doorLatchAjarSwitchVolta m1 : 24|8@1+ (0.02,0) [0|5] "V" Vector__XXX
 SG_ VCRIGHT_doorLatchAjarSwitch_0001 m1 : 32|8@1+ (0.02,0) [0|5] "V" Vector__XXX
 SG_ VCRIGHT_BPillarCameraHeaterCurre m1 : 40|6@1+ (0.02,0) [0|1.24] "A" Vector__XXX
 SG_ VCRIGHT_mirrorTiltXOffset m1 : 48|8@1- (0.02,0) [-2.5|2.5] "V" Vector__XXX
 SG_ VCRIGHT_mirrorTiltYOffset m1 : 56|8@1- (0.02,0) [-2.5|2.5] "V" Vector__XXX

BO_ 915 VCRIGHT_epbmDebug: 8 VCRIGHT
 SG_ VCRIGHT_epbmDebugIndex M : 0|1@1+ (1,0) [0|1] "" Vector__XXX
 SG_ VCRIGHT_epbmCaliperState m0 : 1|3@1+ (1,0) [0|7] "" Vector__XXX
 SG_ VCRIGHT_epbmMotorEnabled m0 : 4|1@1+ (1,0) [0|1] "" Vector__XXX
 SG_ VCRIGHT_epbMotorCurrent m0 : 5|11@1+ (0.01,0) [0|20.47] "A" Vector__XXX
 SG_ VCRIGHT_epbmApplyVoltage m0 : 16|11@1+ (0.01,0) [0|20.47] "A" Vector__XXX
 SG_ VCRIGHT_epbmReleaseVoltage m0 : 27|11@1+ (0.01,0) [0|20.47] "A" Vector__XXX
 SG_ VCRIGHT_summonFaultReason m0 : 38|5@1+ (1,0) [0|31] "" Vector__XXX
 SG_ VCRIGHT_epbSummonState m0 : 43|3@1+ (1,0) [0|7] "" Vector__XXX
 SG_ VCRIGHT_epbmSummonState m0 : 46|3@1+ (1,0) [0|7] "" Vector__XXX
 SG_ VCRIGHT_epbUnitStatus m0 : 49|5@1+ (1,0) [0|31] "" Vector__XXX
 SG_ VCRIGHT_epbmFaultStatus m0 : 54|2@1+ (1,0) [0|3] "" Vector__XXX
 SG_ VCRIGHT_epbFaultStatus m0 : 56|2@1+ (1,0) [0|3] "" Vector__XXX
 SG_ VCRIGHT_epbmSystemStatus m0 : 58|4@1+ (1,0) [0|15] "" Vector__XXX
 SG_ VCRIGHT_epbmAutonomyBehavior m0 : 62|2@1+ (1,0) [0|3] "" Vector__XXX

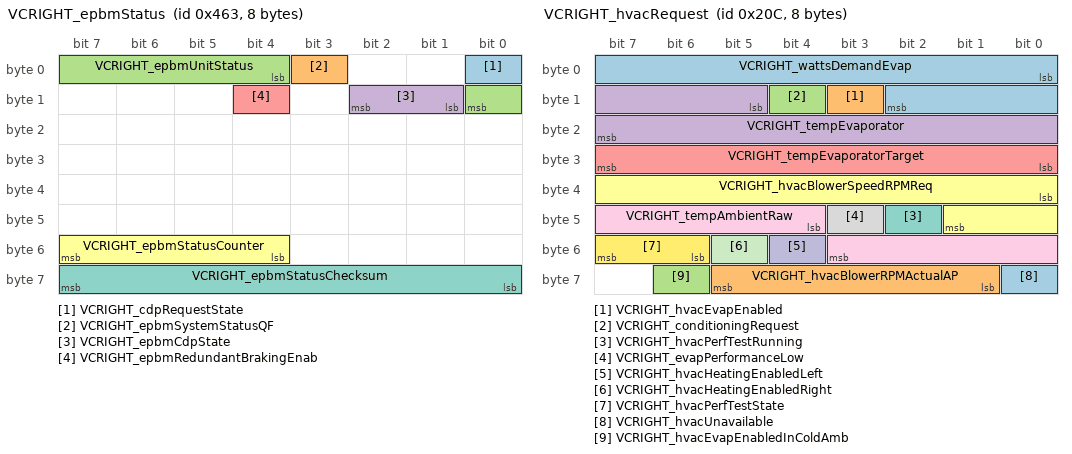
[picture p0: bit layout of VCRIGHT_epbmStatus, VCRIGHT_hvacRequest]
BO_ 1123 VCRIGHT_epbmStatus: 8 VCRIGHT
 SG_ VCRIGHT_cdpRequestState : 0|1@1+ (1,0) [0|1] "" Vector__XXX
 SG_ VCRIGHT_epbmSystemStatusQF : 3|1@1+ (1,0) [0|1] "" Vector__XXX
 SG_ VCRIGHT_epbmUnitStatus : 4|5@1+ (1,0) [0|31] "" Vector__XXX
 SG_ VCRIGHT_epbmCdpState : 9|2@1+ (1,0) [0|3] "" Vector__XXX
 SG_ VCRIGHT_epbmRedundantBrakingEnab : 12|1@1+ (1,0) [0|1] "" Vector__XXX
 SG_ VCRIGHT_epbmStatusCounter : 52|4@1+ (1,0) [0|15] "" Vector__XXX
 SG_ VCRIGHT_epbmStatusChecksum : 56|8@1+ (1,0) [0|255] "" Vector__XXX

BO_ 524 VCRIGHT_hvacRequest: 8 VCRIGHT
 SG_ VCRIGHT_wattsDemandEvap : 0|11@1+ (5,0) [0|10000] "W" Vector__XXX
 SG_ VCRIGHT_hvacEvapEnabled : 11|1@1+ (1,0) [0|1] "" Vector__XXX
 SG_ VCRIGHT_conditioningRequest : 12|1@1+ (1,0) [0|1] "" Vector__XXX
 SG_ VCRIGHT_tempEvaporator : 13|11@1+ (0.1,-40) [-40|105] "degC" Vector__XXX
 SG_ VCRIGHT_tempEvaporatorTarget : 24|8@1+ (0.2,0) [0|50] "degC" Vector__XXX
 SG_ VCRIGHT_hvacBlowerSpeedRPMReq : 32|10@1+ (5,0) [0|5115] "RPM" Vector__XXX
 SG_ VCRIGHT_hvacPerfTestRunning : 42|1@1+ (1,0) [0|1] "" Vector__XXX
 SG_ VCRIGHT_evapPerformanceLow : 43|1@1+ (1,0) [0|1] "" Vector__XXX
 SG_ VCRIGHT_tempAmbientRaw : 44|8@1+ (0.5,-40) [-39.5|80] "degC" Vector__XXX
 SG_ VCRIGHT_hvacHeatingEnabledLeft : 52|1@1+ (1,0) [0|1] "" Vector__XXX
 SG_ VCRIGHT_hvacHeatingEnabledRight : 53|1@1+ (1,0) [0|1] "" Vector__XXX
 SG_ VCRIGHT_hvacPerfTestState : 54|2@1+ (1,0) [0|3] "" Vector__XXX
 SG_ VCRIGHT_hvacUnavailable : 56|1@1+ (1,0) [0|1] "" Vector__XXX
 SG_ VCRIGHT_hvacBlowerRPMActualAP : 57|5@1+ (200,0) [0|4200] "rpm" Vector__XXX
 SG_ VCRIGHT_hvacEvapEnabledInColdAmb : 62|1@1+ (1,0) [0|1] "" Vector__XXX

BO_ 579 VCRIGHT_hvacStatus: 8 VCRIGHT
 SG_ VCRIGHT_hvacStatusIndex M : 0|3@1+ (1,0) [0|7] "" Vector__XXX
 SG_ VCRIGHT_warmingUpStatus m0 : 10|5@1+ (3,7) [7|100] "%" Vector__XXX
 SG_ VCRIGHT_coolingDownStatus m0 : 15|5@1+ (3,7) [7|100] "%" Vector__XXX
 SG_ VCRIGHT_childModeHVACState m0 : 20|2@1+ (1,0) [0|3] "" Vector__XXX
 SG_ VCRIGHT_dogModeState m0 : 22|4@1+ (1,0) [0|15] "" Vector__XXX
 SG_ VCRIGHT_hvacCabinTempEstValid m0 : 26|1@1+ (1,0) [0|1] "" Vector__XXX
 SG_ VCRIGHT_COPNotRunningReasonFilte m0 : 27|3@1+ (1,0) [0|7] "" Vector__XXX
 SG_ VCRIGHT_hvacCabinTempEst m0 : 30|11@1+ (0.1,-40) [-40|164] "degC" Vector__XXX
 SG_ VCRIGHT_hvacAirDistributionMode m0 : 41|3@1+ (1,0) [0|7] "" Vector__XXX
 SG_ VCRIGHT_hvacBlowerSegment m0 : 44|4@1+ (1,0) [0|15] "" Vector__XXX
 SG_ VCRIGHT_hvacRecirc m0 : 48|2@1+ (1,0) [0|3] "" Vector__XXX
 SG_ VCRIGHT_hvacACRunning m0 : 50|1@1+ (1,0) [0|1] "" Vector__XXX
 SG_ VCRIGHT_hvacPowerState m0 : 51|3@1+ (1,0) [0|7] "" Vector__XXX
 SG_ VCRIGHT_hvacVentStatus m0 : 54|2@1+ (1,0) [0|3] "" Vector__XXX
 SG_ VCRIGHT_hvacSecondRowState m0 : 56|3@1+ (1,0) [0|7] "" Vector__XXX
 SG_ VCRIGHT_hvacSystemNominal m0 : 59|1@1+ (1,0) [0|1] "" Vector__XXX
 SG_ VCRIGHT_hvacModelInitStatus m0 : 60|4@1+ (1,0) [0|15] "" Vector__XXX
 SG_ VCRIGHT_hvacMassflowRefrigSysRig m1 : 3|7@1+ (1,0) [0|125] "g/s" Vector__XXX
 SG_ VCRIGHT_hvacRecircDoorPercent m1 : 10|6@1+ (1.6,0) [0|100] "%" Vector__XXX
 SG_ VCRIGHT_tempDuctLeft m1 : 16|8@1+ (0.5,-22) [-22|105] "degC" Vector__XXX
 SG_ VCRIGHT_hvacMassflowRefrigSystem m1 : 24|8@1+ (1,0) [0|250] "g/s" Vector__XXX
 SG_ VCRIGHT_tempDuctRight m1 : 32|8@1+ (0.5,-22) [-22|105] "degC" Vector__XXX
 SG_ VCRIGHT_hvacMassflowRefrigSysLef m1 : 40|7@1+ (1,0) [0|125] "g/s" Vector__XXX
 SG_ VCRIGHT_hvacDuctTargetLeft m1 : 48|8@1+ (0.5,-40) [-40|80] "degC" Vector__XXX
 SG_ VCRIGHT_hvacDuctTargetRight m1 : 56|8@1+ (0.5,-40) [-40|80] "degC" Vector__XXX
 SG_ VCRIGHT_enableTripleCameraFanPow m2 : 9|1@1+ (1,0) [0|1] "" Vector__XXX
 SG_ VCRIGHT_tempDuctRightUpper m2 : 10|8@1+ (0.5,-22) [-22|105] "degC" Vector__XXX
 SG_ VCRIGHT_hpSplitTempsEnabled m2 : 18|1@1+ (1,0) [0|1] "" Vector__XXX
 SG_ VCRIGHT_hvacEvapInletTempEstimat m2 : 19|10@1+ (0.13,-40) [-40|90] "degC" Vector__XXX
 SG_ VCRIGHT_tempMonitorNotNominal m2 : 29|1@1+ (1,0) [0|1] "" Vector__XXX
 SG_ VCRIGHT_hvacCabinAtTempTarget m2 : 30|1@1+ (1,0) [0|1] "" Vector__XXX
 SG_ VCRIGHT_hvacReqSecondRow m2 : 31|1@1+ (1,0) [0|1] "" Vector__XXX
 SG_ VCRIGHT_hvacAirflowReason m2 : 32|5@1+ (1,0) [0|31] "" Vector__XXX
 SG_ VCRIGHT_autoHvacBlowerShouldLimi m2 : 37|1@1+ (1,0) [0|1] "" Vector__XXX
 SG_ VCRIGHT_hvacReqThirdRow m2 : 38|1@1+ (1,0) [0|1] "" Vector__XXX
 SG_ VCRIGHT_solarLoadOnVehicle m2 : 40|8@1+ (4,0) [0|1016] "W/m2" Vector__XXX
 SG_ VCRIGHT_refrigDistCommanded m2 : 48|1@1+ (1,0) [0|1] "" Vector__XXX
 SG_ VCRIGHT_hvacFrontRightSeatFanSta m2 : 49|2@1+ (1,0) [0|3] "" Vector__XXX
 SG_ VCRIGHT_hvacFrontLeftSeatFanStat m2 : 51|2@1+ (1,0) [0|3] "" Vector__XXX
 SG_ VCRIGHT_hvacRefHighPowerRequest m2 : 53|1@1+ (1,0) [0|1] "" Vector__XXX
 SG_ VCRIGHT_windshieldCameraHeaterDu m2 : 54|5@1+ (5,0) [0|100] "%" Vector__XXX
 SG_ VCRIGHT_extendedHvacPerfTestSupp m2 : 59|4@1+ (1,0) [0|15] "" Vector__XXX
 SG_ VCRIGHT_hvacFrontRightSeatHeatSt m3 : 4|2@1+ (1,0) [0|3] "" Vector__XXX
 SG_ VCRIGHT_hvacSeatFrontLeftTempTar m3 : 6|8@1+ (0.5,-40) [-40|80] "degC" Vector__XXX
 SG_ VCRIGHT_hvacManualToAutoNotify m3 : 14|3@1+ (1,0) [0|7] "" Vector__XXX
 SG_ VCRIGHT_hvacRequestsFullAuto m3 : 17|3@1+ (1,0) [0|7] "" Vector__XXX
 SG_ VCRIGHT_passengerPresentHvacCycl m3 : 21|1@1+ (1,0) [0|1] "" Vector__XXX
 SG_ VCRIGHT_hvacRequestsAutoIntake m3 : 22|1@1+ (1,0) [0|1] "" Vector__XXX
 SG_ VCRIGHT_steeringWheelHeatStatus m3 : 24|2@1+ (1,0) [0|3] "" Vector__XXX
 SG_ VCRIGHT_autoDefogStatus m3 : 26|2@1+ (1,0) [0|3] "" Vector__XXX
 SG_ VCRIGHT_solarElevation m3 : 31|9@1- (0.5,0) [-127.5|127.5] "deg" Vector__XXX
 SG_ VCRIGHT_minsToSunrise m3 : 40|8@1+ (10,0) [0|2540] "min" Vector__XXX
 SG_ VCRIGHT_minsToSunset m3 : 48|8@1+ (10,0) [0|2540] "min" Vector__XXX
 SG_ VCRIGHT_hvacLimitedReasonRight m3 : 56|3@1+ (1,0) [0|7] "" Vector__XXX
 SG_ VCRIGHT_hvacLimitedReasonLeft m3 : 59|3@1+ (1,0) [0|7] "" Vector__XXX
 SG_ VCRIGHT_hvacOverheatProtActive m3 : 63|1@1+ (1,0) [0|1] "" Vector__XXX
 SG_ VCRIGHT_autoSwingAvailable m4 : 9|1@1+ (1,0) [0|1] "" Vector__XXX
 SG_ VCRIGHT_tempDuctLeftUpper m4 : 10|8@1+ (0.5,-22) [-22|105] "degC" Vector__XXX
 SG_ VCRIGHT_hvacFrontLeftSeatHeatSta m4 : 18|2@1+ (1,0) [0|3] "" Vector__XXX
 SG_ VCRIGHT_hvacQdotLeft m4 : 20|14@1+ (1,-8191) [-8191|8191] "W" Vector__XXX
 SG_ VCRIGHT_hvacQdotRight m4 : 34|14@1+ (1,-8191) [-8191|8191] "W" Vector__XXX
 SG_ VCRIGHT_tempDuctLeftLower m4 : 48|8@1+ (0.5,-22) [-22|105] "degC" Vector__XXX
 SG_ VCRIGHT_tempDuctRightLower m4 : 56|8@1+ (0.5,-22) [-22|105] "degC" Vector__XXX
 SG_ VCRIGHT_foggingControllerResetRe m5 : 9|15@1+ (1,0) [0|32767] "" Vector__XXX
 SG_ VCRIGHT_modeledCabinPressure m5 : 24|8@1+ (1,0) [0|255] "Pa" Vector__XXX
 SG_ VCRIGHT_blowerTorqueIndex m5 : 32|7@1+ (1,0) [0|127] "%" Vector__XXX
 SG_ VCRIGHT_autoSwingLeftPosX m5 : 39|8@1+ (0.4,0) [0|100] "%" Vector__XXX
 SG_ VCRIGHT_autoSwingRightPositionX m5 : 48|8@1+ (0.4,0) [0|100] "%" Vector__XXX

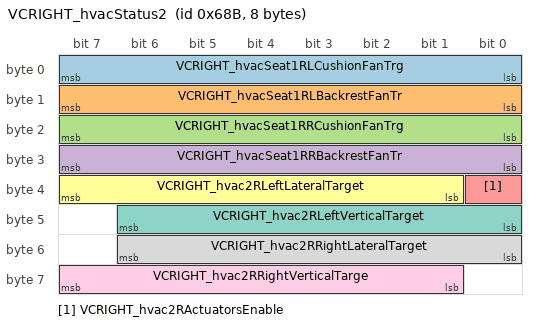
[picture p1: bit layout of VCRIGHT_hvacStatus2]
BO_ 1675 VCRIGHT_hvacStatus2: 8 VCRIGHT
 SG_ VCRIGHT_hvacSeat1RLCushionFanTrg : 0|8@1+ (0.5,0) [0|100] "%" Vector__XXX
 SG_ VCRIGHT_hvacSeat1RLBackrestFanTr : 8|8@1+ (0.5,0) [0|100] "%" Vector__XXX
 SG_ VCRIGHT_hvacSeat1RRCushionFanTrg : 16|8@1+ (0.5,0) [0|100] "%" Vector__XXX
 SG_ VCRIGHT_hvacSeat1RRBackrestFanTr : 24|8@1+ (0.5,0) [0|100] "%" Vector__XXX
 SG_ VCRIGHT_hvac2RActuatorsEnable : 32|1@1+ (1,0) [0|1] "" Vector__XXX
 SG_ VCRIGHT_hvac2RLeftLateralTarget : 33|7@1+ (1,0) [0|100] "%" Vector__XXX
 SG_ VCRIGHT_hvac2RLeftVerticalTarget : 40|7@1+ (1,0) [0|100] "%" Vector__XXX
 SG_ VCRIGHT_hvac2RRightLateralTarget : 48|7@1+ (1,0) [0|100] "%" Vector__XXX
 SG_ VCRIGHT_hvac2RRightVerticalTarge : 57|7@1+ (1,0) [0|100] "%" Vector__XXX

BO_ 774 VCRIGHT_info: 8 VCRIGHT
 SG_ VCRIGHT_infoIndex M : 0|8@1+ (1,0) [0|255] "" Vector__XXX
 SG_ VCRIGHT_infoBuildType m10 : 8|3@1+ (1,0) [0|7] "" Vector__XXX
 SG_ VCRIGHT_infoBuildConfigId m10 : 16|16@1+ (1,0) [0|65535] "" Vector__XXX
 SG_ VCRIGHT_infoHardwareId m10 : 32|16@1+ (1,0) [0|65535] "" Vector__XXX
 SG_ VCRIGHT_infoComponentId m10 : 48|16@1+ (1,0) [0|65535] "" Vector__XXX
 SG_ VCRIGHT_infoPcbaId m11 : 8|8@1+ (1,0) [0|255] "" Vector__XXX
 SG_ VCRIGHT_infoAssemblyId m11 : 16|8@1+ (1,0) [0|254] "" Vector__XXX
 SG_ VCRIGHT_infoUsageId m11 : 24|16@1+ (1,0) [0|65535] "" Vector__XXX
 SG_ VCRIGHT_infoSubUsageId m11 : 40|16@1+ (1,0) [0|65535] "" Vector__XXX
 SG_ VCRIGHT_infoAppCrc m13 : 8|32@1+ (1,0) [0|4294967295] "" Vector__XXX
 SG_ VCRIGHT_infoLUMBARRAppCRC m16 : 32|32@1+ (1,0) [0|4294967295] "" Vector__XXX
 SG_ VCRIGHT_infoAppGitHash m17 : 8|56@1+ (1,0) [0|7.20575940379e+16] "" Vector__XXX
 SG_ VCRIGHT_infoBootGitHash m18 : 8|56@1+ (1,0) [0|7.20575940379e+16] "" Vector__XXX
 SG_ VCRIGHT_infoPlatformType m19 : 8|8@1+ (1,0) [0|255] "" Vector__XXX
 SG_ VCRIGHT_infoBootUdsProtoVersion m20 : 8|16@1+ (1,0) [0|65535] "" Vector__XXX
 SG_ VCRIGHT_infoBootCrc m20 : 24|32@1+ (1,0) [0|4294967295] "" Vector__XXX

BO_TX_BU_ 960 : VCRIGHT;
BO_TX_BU_ 1795 : VCRIGHT;
BO_TX_BU_ 259 : VCRIGHT;
BO_TX_BU_ 2010 : VCRIGHT;
BO_TX_BU_ 915 : VCRIGHT;
BO_TX_BU_ 1123 : VCRIGHT;
BO_TX_BU_ 524 : VCRIGHT;
BO_TX_BU_ 579 : VCRIGHT;
BO_TX_BU_ 1675 : VCRIGHT;
BO_TX_BU_ 774 : VCRIGHT;
CM_ SG_ 2011 VCRIGHT_a518_seatState "Right body controller: a518 seat state; raw 15 = signal not available (SNA)";
CM_ SG_ 2011 VCRIGHT_a520_epbConfig "Right body controller: a520 epb config";
CM_ SG_ 2011 VCRIGHT_a520_gtwEpbConfig "Right body controller: a520 gtw epb config";
CM_ SG_ 2011 VCRIGHT_a525_GTW_twelveVBatteryT "Right body controller: a525 GTW twelve v battery type";
CM_ SG_ 2011 VCRIGHT_a525_newLVBatteryType "Right body controller: a525 new LV battery type";
CM_ SG_ 2011 VCRIGHT_a525_initialLVBatteryTyp "Right body controller: a525 initial LV battery type";
CM_ SG_ 2011 VCRIGHT_a525_serviceMode "Signal reported by Right body controller";
CM_ SG_ 2011 VCRIGHT_a525_factoryGated "Right body controller: a525 factory gated";
CM_ SG_ 2011 VCRIGHT_a525_frunkOpen "Right body controller: a525 frunk open";
CM_ SG_ 2011 VCRIGHT_a538_ptcHeaterFault "Right body controller: a538 ptc heater fault";
CM_ SG_ 2011 VCRIGHT_a538_ductTempSensorFault "Right body controller: a538 duct temp sensor fault";
CM_ SG_ 2011 VCRIGHT_a538_evapTempSensorFault "Right body controller: a538 evap temp sensor fault";
CM_ SG_ 2011 VCRIGHT_a538_cabinTempSensorFaul "Right body controller: a538 cabin temp sensor fault";
CM_ SG_ 2011 VCRIGHT_a538_cabinModelNotInitia "Right body controller: a538 cabin model not initialized";
CM_ SG_ 2011 VCRIGHT_a538_airpathsBlocked "Right body controller: a538 airpaths blocked";
CM_ SG_ 2011 VCRIGHT_a538_blowerFaultOrStoppe "Right body controller: a538 blower fault or stopped";
CM_ SG_ 2011 VCRIGHT_a538_compressorFaultOrSt "Right body controller: a538 compressor fault or standby";
CM_ SG_ 2011 VCRIGHT_a538_heatPumpModeNotAtta "Right body controller: a538 heat pump mode not attainable";
CM_ SG_ 2011 VCRIGHT_a538_thsVersionMismatch "Right body controller: a538 ths version mismatch";
CM_ SG_ 2011 VCRIGHT_a538_thsMia "Right body controller: a538 ths mia";
CM_ SG_ 2011 VCRIGHT_a538_hvOn "Right body controller: a538 hv on";
CM_ SG_ 2011 VCRIGHT_a538_hvacPowerOn "Right body controller: a538 hvac power on";
CM_ SG_ 2011 VCRIGHT_a538_limpMode "Right body controller: a538 limp mode";
CM_ SG_ 2011 VCRIGHT_a539_hvacSystemNotNomina "Right body controller: a539 hvac system not nominal";
CM_ SG_ 2011 VCRIGHT_a539_modeledCabinTempOut "Right body controller: a539 modeled cabin temp out of range";
CM_ SG_ 2011 VCRIGHT_a539_modeledCabinTempExc "Right body controller: a539 modeled cabin temp exceeding set temp";
CM_ SG_ 2011 VCRIGHT_a539_cabinTempSensorFaul "Right body controller: a539 cabin temp sensor fault";
CM_ SG_ 2011 VCRIGHT_a539_cabinTempSensorOutO "Right body controller: a539 cabin temp sensor out of range";
CM_ SG_ 2011 VCRIGHT_a539_modeledCabinTempDev "Right body controller: a539 modeled cabin temp deviation";
CM_ SG_ 2011 VCRIGHT_a545_GTW_twelveVBatteryT "Right body controller: a545 GTW twelve v battery type";
CM_ SG_ 2011 VCRIGHT_a545_newLVBatteryType "Right body controller: a545 new LV battery type";
CM_ SG_ 2011 VCRIGHT_a545_serviceMode "Signal reported by Right body controller";
CM_ SG_ 2011 VCRIGHT_a545_factoryGated "Right body controller: a545 factory gated";
CM_ SG_ 2011 VCRIGHT_a545_frunkOpen "Right body controller: a545 frunk open";
CM_ SG_ 2011 VCRIGHT_a551_restrictDoorRelease "Right body controller: a551 restrict door release signal front";
CM_ SG_ 2011 VCRIGHT_a551_interiorReleaseReqC "Right body controller: a551 interior release req count front";
CM_ SG_ 2011 VCRIGHT_a551_lastRequestSourceFr "Right body controller: a551 last request source front";
CM_ SG_ 2011 VCRIGHT_a551_restrictDoorRe_0001 "Right body controller: a551 restrict door release signal rear";
CM_ SG_ 2011 VCRIGHT_a551_interiorReleas_0001 "Right body controller: a551 interior release req count rear";
CM_ SG_ 2011 VCRIGHT_a551_lastRequestSourceRe "Right body controller: a551 last request source rear";
CM_ SG_ 2011 VCRIGHT_a560_isRearwardEndstopUn "Right body controller: a560 is rearward endstop uncalibrated";
CM_ SG_ 2011 VCRIGHT_a560_isAbsPosSensorUncal "Right body controller: a560 is abs pos sensor uncalibrated";
CM_ SG_ 2011 VCRIGHT_a560_seatState "Right body controller: a560 seat state; raw 15 = signal not available (SNA)";
CM_ SG_ 2011 VCRIGHT_a560_motorType "Right body controller: a560 motor type";
CM_ SG_ 2011 VCRIGHT_a560_absPosSensState "Right body controller: a560 abs pos sens state";
CM_ SG_ 2011 VCRIGHT_a563_calibrated "Right body controller: a563 calibrated";
CM_ SG_ 2011 VCRIGHT_a563_angle "Right body controller: a563 angle";
CM_ SG_ 2011 VCRIGHT_a563_seatStatePrev "Right body controller: a563 seat state prev; raw 15 = signal not available (SNA)";
CM_ SG_ 2011 VCRIGHT_a563_obstacleDetectReaso "Right body controller: a563 obstacle detect reason";
CM_ SG_ 2011 VCRIGHT_a563_accelLookbackTripDe "Right body controller: a563 accel lookback trip depth";
CM_ SG_ 2011 VCRIGHT_a563_duty "Right body controller: a563 duty";
CM_ SG_ 2011 VCRIGHT_a563_currentAbsFilt "Right body controller: a563 current abs filt";
CM_ SG_ 2011 VCRIGHT_a563_motorType "Right body controller: a563 motor type";
CM_ SG_ 2011 VCRIGHT_a563_absolutePosSensorFo "Right body controller: a563 absolute pos sensor forward";
CM_ SG_ 2011 VCRIGHT_a563_cabinTemp "Right body controller: a563 cabin temp";
CM_ SG_ 2011 VCRIGHT_a567_isRearwardEndstopUn "Right body controller: a567 is rearward endstop uncalibrated";
CM_ SG_ 2011 VCRIGHT_a567_isAbsPosSensorUncal "Right body controller: a567 is abs pos sensor uncalibrated";
CM_ SG_ 2011 VCRIGHT_a568_seatState "Right body controller: a568 seat state; raw 15 = signal not available (SNA)";
CM_ SG_ 2011 VCRIGHT_a570_seatHeatCurrent "Right body controller: a570 seat heat current";
CM_ SG_ 2011 VCRIGHT_a570_seatHeatTmp "Right body controller: a570 seat heat tmp";
CM_ SG_ 2011 VCRIGHT_a571_seatHeatCurrent "Right body controller: a571 seat heat current";
CM_ SG_ 2011 VCRIGHT_a571_seatHeatTmp "Right body controller: a571 seat heat tmp";
CM_ SG_ 2011 VCRIGHT_a572_seatHeatCurrent "Right body controller: a572 seat heat current";
CM_ SG_ 2011 VCRIGHT_a572_seatHeatTmp "Right body controller: a572 seat heat tmp";
CM_ SG_ 2011 VCRIGHT_a573_seatHeatCurrent "Right body controller: a573 seat heat current";
CM_ SG_ 2011 VCRIGHT_a573_seatHeatTmp "Right body controller: a573 seat heat tmp";
CM_ SG_ 2011 VCRIGHT_a577_outputFaulted "Right body controller: a577 output faulted";
CM_ SG_ 2011 VCRIGHT_a577_currentSenseFaulted "Right body controller: a577 current sense faulted";
CM_ SG_ 2011 VCRIGHT_a577_tempSenseFaulted "Right body controller: a577 temp sense faulted";
CM_ SG_ 2011 VCRIGHT_a577_underCurrent "Right body controller: a577 under current";
CM_ SG_ 2011 VCRIGHT_a577_overCurrent "Right body controller: a577 over current";
CM_ SG_ 2011 VCRIGHT_a577_overTemperature "Right body controller: a577 over temperature";
CM_ SG_ 2011 VCRIGHT_a578_openCircuitDoorFR "Right body controller: a578 open circuit door FR";
CM_ SG_ 2011 VCRIGHT_a578_shortCircuitDoorFR "Right body controller: a578 short circuit door FR";
CM_ SG_ 2011 VCRIGHT_a578_miaDoorFR "Right body controller: a578 mia door FR";
CM_ SG_ 2011 VCRIGHT_a578_openCircuitDoorRR "Right body controller: a578 open circuit door RR";
CM_ SG_ 2011 VCRIGHT_a578_shortCircuitDoorRR "Right body controller: a578 short circuit door RR";
CM_ SG_ 2011 VCRIGHT_a578_miaDoorRR "Right body controller: a578 mia door RR";
CM_ SG_ 2011 VCRIGHT_a579_liftgateFollowerSto "Right body controller: a579 liftgate follower stopping condition";
CM_ SG_ 2011 VCRIGHT_a579_liftgateFollowerPos "Right body controller: a579 liftgate follower position";
CM_ SG_ 2011 VCRIGHT_a579_liftgateFollowerLat "Right body controller: a579 liftgate follower latch status; raw 0 = signal not available (SNA)";
CM_ SG_ 2011 VCRIGHT_a585_ambientTemp "Right body controller: a585 ambient temp; raw 0 = signal not available (SNA)";
CM_ SG_ 2011 VCRIGHT_a586_ambientTemp "Right body controller: a586 ambient temp; raw 0 = signal not available (SNA)";
CM_ SG_ 2011 VCRIGHT_a587_VEH_switchStatus "Right body controller: a587 VEH switch status";
CM_ SG_ 2011 VCRIGHT_a588_VEH_seatStatus2 "Right body controller: a588 VEH seat status2";
CM_ SG_ 2011 VCRIGHT_a588_VEH_switchStatus "Right body controller: a588 VEH switch status";
CM_ SG_ 2011 VCRIGHT_a588_VEH_restraintStatus "Right body controller: a588 VEH restraint status";
CM_ SG_ 2011 VCRIGHT_a590_seatMotorCalibrated "Right body controller: a590 seat motor calibrated";
CM_ SG_ 2011 VCRIGHT_a590_seatMotorCurrent "Right body controller: a590 seat motor current";
CM_ SG_ 2011 VCRIGHT_a590_seatMotorState "Right body controller: a590 seat motor state";
CM_ SG_ 2011 VCRIGHT_a590_seatSwitchBack "Right body controller: a590 seat switch back; raw 0 = signal not available (SNA)";
CM_ SG_ 2011 VCRIGHT_a590_seatSwitchForward "Right body controller: a590 seat switch forward; raw 0 = signal not available (SNA)";
CM_ SG_ 2011 VCRIGHT_a591_seatMotorCurrent "Right body controller: a591 seat motor current";
CM_ SG_ 2011 VCRIGHT_a591_seatMotorPosReal "Right body controller: a591 seat motor pos real";
CM_ SG_ 2011 VCRIGHT_a591_seatMotorState "Right body controller: a591 seat motor state";
CM_ SG_ 2011 VCRIGHT_a591_seatSwitchBack "Right body controller: a591 seat switch back; raw 0 = signal not available (SNA)";
CM_ SG_ 2011 VCRIGHT_a591_seatSwitchForward "Right body controller: a591 seat switch forward; raw 0 = signal not available (SNA)";
CM_ SG_ 2011 VCRIGHT_a592_seatMotorCurrent "Right body controller: a592 seat motor current";
CM_ SG_ 2011 VCRIGHT_a592_seatMotorPosReal "Right body controller: a592 seat motor pos real";
CM_ SG_ 2011 VCRIGHT_a592_seatMotorState "Right body controller: a592 seat motor state";
CM_ SG_ 2011 VCRIGHT_a592_seatSwitchBack "Right body controller: a592 seat switch back; raw 0 = signal not available (SNA)";
CM_ SG_ 2011 VCRIGHT_a592_seatSwitchForward "Right body controller: a592 seat switch forward; raw 0 = signal not available (SNA)";
CM_ SG_ 2011 VCRIGHT_a593_seatMotorCalibrated "Right body controller: a593 seat motor calibrated";
CM_ SG_ 2011 VCRIGHT_a593_seatMotorCurrent "Right body controller: a593 seat motor current";
CM_ SG_ 2011 VCRIGHT_a593_seatMotorPosReal "Right body controller: a593 seat motor pos real";
CM_ SG_ 2011 VCRIGHT_a593_seatMotorState "Right body controller: a593 seat motor state";
CM_ SG_ 2011 VCRIGHT_a593_seatSwitchBack "Right body controller: a593 seat switch back; raw 0 = signal not available (SNA)";
CM_ SG_ 2011 VCRIGHT_a593_seatSwitchForward "Right body controller: a593 seat switch forward; raw 0 = signal not available (SNA)";
CM_ SG_ 2011 VCRIGHT_a594_seatMotorCurrent "Right body controller: a594 seat motor current";
CM_ SG_ 2011 VCRIGHT_a594_seatMotorDCurrent "Right body controller: a594 seat motor d current";
CM_ SG_ 2011 VCRIGHT_a594_seatMotorPosReal "Right body controller: a594 seat motor pos real";
CM_ SG_ 2011 VCRIGHT_a594_seatMotorState "Right body controller: a594 seat motor state";
CM_ SG_ 2011 VCRIGHT_a595_seatMotorCurrent "Right body controller: a595 seat motor current";
CM_ SG_ 2011 VCRIGHT_a595_seatMotorDCurrent "Right body controller: a595 seat motor d current";
CM_ SG_ 2011 VCRIGHT_a595_seatMotorPosReal "Right body controller: a595 seat motor pos real";
CM_ SG_ 2011 VCRIGHT_a595_seatMotorState "Right body controller: a595 seat motor state";
CM_ SG_ 2011 VCRIGHT_a596_frontDoorLatchAjarS "Right body controller: a596 front door latch ajar switch voltage";
CM_ SG_ 2011 VCRIGHT_a597_rearDoorLatchAjarSw "Right body controller: a597 rear door latch ajar switch voltage";
CM_ SG_ 2011 VCRIGHT_a599_GTW_twelveVBatteryT "Right body controller: a599 GTW twelve v battery type";
CM_ SG_ 2011 VCRIGHT_a599_newLVBatteryType "Right body controller: a599 new LV battery type";
CM_ SG_ 2011 VCRIGHT_a599_initialLVBatteryTyp "Right body controller: a599 initial LV battery type";
CM_ SG_ 2011 VCRIGHT_a599_serviceMode "Signal reported by Right body controller";
CM_ SG_ 2011 VCRIGHT_a599_factoryGated "Right body controller: a599 factory gated";
CM_ SG_ 2011 VCRIGHT_a599_frunkOpen "Right body controller: a599 frunk open";
CM_ SG_ 2011 VCRIGHT_a605_excessiveMacFailure "Right body controller: a605 excessive mac failures";
CM_ BO_ 960 "Right body controller message: alert matrix";
CM_ SG_ 960 VCRIGHT_matrixIndex "Right body controller: matrix index";
CM_ SG_ 960 VCRIGHT_a001_WatchdogReset "Right body controller: a001 watchdog reset";
CM_ SG_ 960 VCRIGHT_a002_PowerLossReset "Right body controller: a002 power loss reset";
CM_ SG_ 960 VCRIGHT_a003_SWAssertion "Right body controller: a003 SW assertion";
CM_ SG_ 960 VCRIGHT_a005_CANTXError "Right body controller: a005 CANTX error";
CM_ SG_ 960 VCRIGHT_a006_CANTX_cyclicError "Right body controller: a006 CANTX cyclic error";
CM_ SG_ 960 VCRIGHT_a010_ExtSupplyVoltError "Right body controller: a010 ext supply volt error";
CM_ SG_ 960 VCRIGHT_a012_CPUReset "Right body controller: a012 CPU reset";
CM_ SG_ 960 VCRIGHT_a013_AlertManagerFault "Right body controller: a013 alert manager fault";
CM_ SG_ 960 VCRIGHT_a015_NVMMError "Right body controller: a015 NVMM error";
CM_ SG_ 960 VCRIGHT_a016_NVMMRecordError "Right body controller: a016 NVMM record error";
CM_ SG_ 960 VCRIGHT_a017_NVMMStatusDbg "Right body controller: a017 NVMM status dbg";
CM_ SG_ 960 VCRIGHT_a021_TaskSchedulerError "Right body controller: a021 task scheduler error";
CM_ SG_ 960 VCRIGHT_a022_TaskInitError "Right body controller: a022 task init error";
CM_ SG_ 960 VCRIGHT_a029_CoreDump "Right body controller: a029 core dump";
CM_ SG_ 960 VCRIGHT_a030_ECULogUploadRequest "Right body controller: a030 ECU log upload request";
CM_ SG_ 960 VCRIGHT_a031_UDSActive "Right body controller: a031 UDS active";
CM_ SG_ 960 VCRIGHT_a041_HighCPULoad "Right body controller: a041 high CPU load";
CM_ SG_ 960 VCRIGHT_a042_HighStackUsage "Right body controller: a042 high stack usage";
CM_ SG_ 960 VCRIGHT_a043_Task1msError "Right body controller: a043 task1ms error";
CM_ SG_ 960 VCRIGHT_a044_Task10msError "Right body controller: a044 task10ms error";
CM_ SG_ 960 VCRIGHT_a045_Task100msError "Right body controller: a045 task100ms error";
CM_ SG_ 960 VCRIGHT_a046_Task1000msError "Right body controller: a046 task1000ms error";
CM_ SG_ 960 VCRIGHT_a057_HVP_MIA "Right body controller: a057 HVP MIA";
CM_ SG_ 960 VCRIGHT_a058_inputRHighSyncDebug "Right body controller: a058 input r high sync debug";
CM_ SG_ 960 VCRIGHT_a059_inputResistanceHigh "Right body controller: a059 input resistance high";
CM_ SG_ 960 VCRIGHT_a060_engineeringBuild "Right body controller: a060 engineering build";
CM_ SG_ 960 VCRIGHT_a061_XCPConnected "Right body controller: a061 XCP connected";
CM_ SG_ 960 VCRIGHT_a062_XCPWasConnected "Right body controller: a062 XCP was connected";
CM_ SG_ 960 VCRIGHT_a063_SwitchFault "Right body controller: a063 switch fault";
CM_ SG_ 960 VCRIGHT_a064_busSleepReqTimeout "Right body controller: a064 bus sleep req timeout";
CM_ SG_ 960 VCRIGHT_a065_emiosIsrRateLimited "Right body controller: a065 emios isr rate limited dbg";
CM_ SG_ 960 VCRIGHT_a066_emiosIsrShortPeriod "Right body controller: a066 emios isr short period detected dbg";
CM_ SG_ 960 VCRIGHT_a082_VCRIGHT_IPC_MIA "Right body controller: a082 VCRIGHT IPC MIA";
CM_ SG_ 960 VCRIGHT_a083_VCLEFT_IPC_MIA "Right body controller: a083 VCLEFT IPC MIA";
CM_ SG_ 960 VCRIGHT_a084_TPMS_MIA "Right body controller: a084 TPMS MIA";
CM_ SG_ 960 VCRIGHT_a085_CCCM_MIA "Right body controller: a085 CCCM MIA";
CM_ SG_ 960 VCRIGHT_a086_VCBATT_MIA "Right body controller: a086 VCBATT MIA";
CM_ SG_ 960 VCRIGHT_a087_DIREL_MIA "Right body controller: a087 DIREL MIA";
CM_ SG_ 960 VCRIGHT_a088_DIRER_MIA "Right body controller: a088 DIRER MIA";
CM_ SG_ 960 VCRIGHT_a089_IBST_MIA "Right body controller: a089 IBST MIA";
CM_ SG_ 960 VCRIGHT_a090_APS_MIA "Right body controller: a090 APS MIA";
CM_ SG_ 960 VCRIGHT_a091_CMPD_MIA "Right body controller: a091 CMPD MIA";
CM_ SG_ 960 VCRIGHT_a092_VCSEATD_MIA "Right body controller: a092 VCSEATD MIA";
CM_ SG_ 960 VCRIGHT_a093_VCSEATP_MIA "Right body controller: a093 VCSEATP MIA";
CM_ SG_ 960 VCRIGHT_a094_EPAS3P_MIA "Right body controller: a094 EPAS3 p MIA";
CM_ SG_ 960 VCRIGHT_a095_CHG_MIA "Right body controller: a095 CHG MIA";
CM_ SG_ 960 VCRIGHT_a096_OCS1P_MIA "Right body controller: a096 OCS1 p MIA";
CM_ SG_ 960 VCRIGHT_a097_CMP_MIA "Right body controller: a097 CMP MIA";
CM_ SG_ 960 VCRIGHT_a098_DIR_MIA "Right body controller: a098 DIR MIA";
CM_ SG_ 960 VCRIGHT_a099_PARK_MIA "Right body controller: a099 PARK MIA";
CM_ SG_ 960 VCRIGHT_a100_CANbus_MIA "Right body controller: a100 CA nbus MIA";
CM_ SG_ 960 VCRIGHT_a101_PM_MIA "Right body controller: a101 PM MIA";
CM_ SG_ 960 VCRIGHT_a102_PTC_MIA "Right body controller: a102 PTC MIA";
CM_ SG_ 960 VCRIGHT_a103_CP_MIA "Right body controller: a103 CP MIA";
CM_ SG_ 960 VCRIGHT_a104_DAS_MIA "Right body controller: a104 DAS MIA";
CM_ SG_ 960 VCRIGHT_a105_TAS_MIA "Right body controller: a105 TAS MIA";
CM_ SG_ 960 VCRIGHT_a106_PCS_MIA "Right body controller: a106 PCS MIA";
CM_ SG_ 960 VCRIGHT_a107_BMS_MIA "Right body controller: a107 BMS MIA";
CM_ SG_ 960 VCRIGHT_a108_DIF_MIA "Right body controller: a108 DIF MIA";
CM_ SG_ 960 VCRIGHT_a109_RCM_MIA "Right body controller: a109 RCM MIA";
CM_ SG_ 960 VCRIGHT_a110_GTW_MIA "Right body controller: a110 GTW MIA";
CM_ SG_ 960 VCRIGHT_a111_EPBR_MIA "Right body controller: a111 EPBR MIA";
CM_ SG_ 960 VCRIGHT_a112_EPBL_MIA "Right body controller: a112 EPBL MIA";
CM_ SG_ 960 VCRIGHT_a113_UI_MIA "Right body controller: a113 UI MIA";
CM_ SG_ 960 VCRIGHT_a114_ESP_MIA "Right body controller: a114 ESP MIA";
CM_ SG_ 960 VCRIGHT_a115_VCSEC_MIA "Right body controller: a115 VCSEC MIA";
CM_ SG_ 960 VCRIGHT_a116_VCRIGHT_MIA "Right body controller: a116 VCRIGHT MIA";
CM_ SG_ 960 VCRIGHT_a117_VCLEFT_MIA "Right body controller: a117 VCLEFT MIA";
CM_ SG_ 960 VCRIGHT_a118_VCFRONT_MIA "Right body controller: a118 VCFRONT MIA";
CM_ SG_ 960 VCRIGHT_a119_SCCM_MIA "Right body controller: a119 SCCM MIA";
CM_ SG_ 960 VCRIGHT_a120_DI_DRIVE_MIA "Right body controller: a120 DI DRIVE MIA";
CM_ SG_ 960 VCRIGHT_a121_ETC_MIA "Right body controller: a121 ETC MIA";
CM_ SG_ 960 VCRIGHT_a122_ICR_MIA "Right body controller: a122 ICR MIA";
CM_ SG_ 960 VCRIGHT_a123_VC_SECONDARY_LIGHTI "Right body controller: a123 VC SECONDARY LIGHTING LEADER MIA";
CM_ SG_ 960 VCRIGHT_a124_BB_MIA "Right body controller: a124 BB MIA";
CM_ SG_ 960 VCRIGHT_a125_RCU_MIA "Right body controller: a125 RCU MIA";
CM_ SG_ 960 VCRIGHT_a126_hvacActOpenLoadDBG "Right body controller: a126 hvac act open load DBG";
CM_ SG_ 960 VCRIGHT_a127_hvacActOvercurrentD "Right body controller: a127 hvac act overcurrent DBG";
CM_ SG_ 960 VCRIGHT_a128_hvacActDrvFaultDBG "Right body controller: a128 hvac act drv fault DBG";
CM_ SG_ 960 VCRIGHT_a129_hvacIntakeUncalib "Right body controller: a129 hvac intake uncalib";
CM_ SG_ 960 VCRIGHT_a130_hvacLHBleedUncalib "Right body controller: a130 hvac LH bleed uncalib";
CM_ SG_ 960 VCRIGHT_a131_hvacRHBleedUncalib "Right body controller: a131 hvac RH bleed uncalib";
CM_ SG_ 960 VCRIGHT_a132_hvacLHVaneUncalib "Right body controller: a132 hvac LH vane uncalib";
CM_ SG_ 960 VCRIGHT_a133_hvacRHVaneUncalib "Right body controller: a133 hvac RH vane uncalib";
CM_ SG_ 960 VCRIGHT_a134_hvacUpprModeUncalib "Right body controller: a134 hvac uppr mode uncalib";
CM_ SG_ 960 VCRIGHT_a135_hvacLowrModeUncalib "Right body controller: a135 hvac lowr mode uncalib";
CM_ SG_ 960 VCRIGHT_a136_hvacIntakeFault "Right body controller: a136 hvac intake fault";
CM_ SG_ 960 VCRIGHT_a137_hvacLHBleedFault "Right body controller: a137 hvac LH bleed fault";
CM_ SG_ 960 VCRIGHT_a138_hvacRHBleedFault "Right body controller: a138 hvac RH bleed fault";
CM_ SG_ 960 VCRIGHT_a139_hvacLHVaneFault "Right body controller: a139 hvac LH vane fault";
CM_ SG_ 960 VCRIGHT_a140_hvacRHVaneFault "Right body controller: a140 hvac RH vane fault";
CM_ SG_ 960 VCRIGHT_a141_hvacUpperModeFault "Right body controller: a141 hvac upper mode fault";
CM_ SG_ 960 VCRIGHT_a142_hvacLowerModeFault "Right body controller: a142 hvac lower mode fault";
CM_ SG_ 960 VCRIGHT_a143_mirrorManuallyFolde "Right body controller: a143 mirror manually folded";
CM_ SG_ 960 VCRIGHT_a144_evaporatorTempSns "Right body controller: a144 evaporator temp sns";
CM_ SG_ 960 VCRIGHT_a145_ductLeftTempSns "Right body controller: a145 duct left temp sns";
CM_ SG_ 960 VCRIGHT_a146_ductRightTempSns "Right body controller: a146 duct right temp sns";
CM_ SG_ 960 VCRIGHT_a147_incarProbeTempSns "Right body controller: a147 incar probe temp sns";
CM_ SG_ 960 VCRIGHT_a148_incarMidTempSns "Right body controller: a148 incar mid temp sns";
CM_ SG_ 960 VCRIGHT_a149_incarDeepTempSns "Right body controller: a149 incar deep temp sns";
CM_ SG_ 960 VCRIGHT_a150_windowPinchFront "Right body controller: a150 window pinch front";
CM_ SG_ 960 VCRIGHT_a151_windowPinchRear "Right body controller: a151 window pinch rear";
CM_ SG_ 960 VCRIGHT_a152_windowUncalFront "Right body controller: a152 window uncal front";
CM_ SG_ 960 VCRIGHT_a153_windowUncalRear "Right body controller: a153 window uncal rear";
CM_ SG_ 960 VCRIGHT_a154_windowThermalFront "Right body controller: a154 window thermal front";
CM_ SG_ 960 VCRIGHT_a155_windowThermalRear "Right body controller: a155 window thermal rear";
CM_ SG_ 960 VCRIGHT_a156_windowNoInputFront "Right body controller: a156 window no input front";
CM_ SG_ 960 VCRIGHT_a157_windowNoInputRear "Right body controller: a157 window no input rear";
CM_ SG_ 960 VCRIGHT_a158_windowPinchOverideF "Right body controller: a158 window pinch overide f";
CM_ SG_ 960 VCRIGHT_a159_windowPinchOverideR "Right body controller: a159 window pinch overide r";
CM_ SG_ 960 VCRIGHT_a160_windowUndercurrentF "Right body controller: a160 window undercurrent f";
CM_ SG_ 960 VCRIGHT_a161_windowUndercurrentR "Right body controller: a161 window undercurrent r";
CM_ SG_ 960 VCRIGHT_a162_windowEncoderStallF "Right body controller: a162 window encoder stall f";
CM_ SG_ 960 VCRIGHT_a163_windowEncoderStallR "Right body controller: a163 window encoder stall r";
CM_ SG_ 960 VCRIGHT_a164_windowFactoryTest "Right body controller: a164 window factory test";
CM_ SG_ 960 VCRIGHT_a165_windowFactoryTest2 "Right body controller: a165 window factory test2";
CM_ SG_ 960 VCRIGHT_a166_windowDebug "Right body controller: a166 window debug";
CM_ SG_ 960 VCRIGHT_a167_windowDebugPinchF "Right body controller: a167 window debug pinch f";
CM_ SG_ 960 VCRIGHT_a168_windowDebugPinchR "Right body controller: a168 window debug pinch r";
CM_ SG_ 960 VCRIGHT_a169_windowCurrentPeakF "Right body controller: a169 window current peak f";
CM_ SG_ 960 VCRIGHT_a170_windowCurrentPeakR "Right body controller: a170 window current peak r";
CM_ SG_ 960 VCRIGHT_a171_hvacRearUncalib "Right body controller: a171 hvac rear uncalib";
CM_ SG_ 960 VCRIGHT_a172_SPI_MIA "Right body controller: a172 SPI MIA";
CM_ SG_ 960 VCRIGHT_a173_windowBtnDoorOpen "Right body controller: a173 window btn door open";
CM_ SG_ 960 VCRIGHT_a174_BLERightPowerCycled "Right body controller: a174 BLE right power cycled";
CM_ SG_ 960 VCRIGHT_a175_windowSealDefectFro "Right body controller: a175 window seal defect front";
CM_ SG_ 960 VCRIGHT_a176_windowSealDefectRea "Right body controller: a176 window seal defect rear";
CM_ SG_ 960 VCRIGHT_a177_hvacRearFault "Right body controller: a177 hvac rear fault";
CM_ SG_ 960 VCRIGHT_a178_trunkSwitchVCBATTMI "Right body controller: a178 trunk switch VCBATTMIA";
CM_ SG_ 960 VCRIGHT_a179_trunkSwitchVCFRONTM "Right body controller: a179 trunk switch VCFRONTMIA";
CM_ SG_ 960 VCRIGHT_a180_frontDoorLatchRehom "Right body controller: a180 front door latch rehome";
CM_ SG_ 960 VCRIGHT_a181_rearDoorLatchRehome "Right body controller: a181 rear door latch rehome";
CM_ SG_ 960 VCRIGHT_a182_emergencyLatchRel "Right body controller: a182 emergency latch rel";
CM_ SG_ 960 VCRIGHT_a183_doorStateFactoryTes "Right body controller: a183 door state factory test";
CM_ SG_ 960 VCRIGHT_a184_trunkFailedOpening "Right body controller: a184 trunk failed opening";
CM_ SG_ 960 VCRIGHT_a185_summonAborted "Right body controller: a185 summon aborted";
CM_ SG_ 960 VCRIGHT_a186_latchReleaseFailedF "Right body controller: a186 latch release failed f";
CM_ SG_ 960 VCRIGHT_a187_latchReleaseFailedR "Right body controller: a187 latch release failed r";
CM_ SG_ 960 VCRIGHT_a188_latchUnableToRearmF "Right body controller: a188 latch unable to rearm f";
CM_ SG_ 960 VCRIGHT_a189_latchUnableToRearmR "Right body controller: a189 latch unable to rearm r";
CM_ SG_ 960 VCRIGHT_a190_eFuseMgmtVbatFused "Right body controller: a190 e fuse mgmt vbat fused";
CM_ SG_ 960 VCRIGHT_a191_gloveboxPower "Right body controller: a191 glovebox power";
CM_ SG_ 960 VCRIGHT_a192_gloveboxLatchRel "Right body controller: a192 glovebox latch rel";
CM_ SG_ 960 VCRIGHT_a193_amplifierEFuseFault "Right body controller: a193 amplifier e fuse fault";
CM_ SG_ 960 VCRIGHT_a194_cntctrPwrEFuseFault "Right body controller: a194 cntctr pwr e fuse fault";
CM_ SG_ 960 VCRIGHT_a195_hvcEFuseFault "Right body controller: a195 hvc e fuse fault";
CM_ SG_ 960 VCRIGHT_a196_VEHCANOverterminate "Right body controller: a196 VEHCAN overterminate";
CM_ SG_ 960 VCRIGHT_a197_VEHCANUndertrminate "Right body controller: a197 VEHCAN undertrminate";
CM_ SG_ 960 VCRIGHT_a198_PRVCANOverterminate "Right body controller: a198 PRVCAN overterminate";
CM_ SG_ 960 VCRIGHT_a199_PRVCANUndertrminate "Right body controller: a199 PRVCAN undertrminate";
CM_ SG_ 960 VCRIGHT_a200_motorPhantomEncoder "Right body controller: a200 motor phantom encoder";
CM_ SG_ 960 VCRIGHT_a201_motorDutyEncDisabl "Right body controller: a201 motor duty enc disabl";
CM_ SG_ 960 VCRIGHT_a202_epbmUnderIStatic "Right body controller: a202 epbm under i static";
CM_ SG_ 960 VCRIGHT_a203_epbmOverIStatic "Right body controller: a203 epbm over i static";
CM_ SG_ 960 VCRIGHT_a204_epbmUnderIDyn "Right body controller: a204 epbm under i dyn";
CM_ SG_ 960 VCRIGHT_a205_epbmOverIDyn "Right body controller: a205 epbm over i dyn";
CM_ SG_ 960 VCRIGHT_a206_epbWrongDirection "Right body controller: a206 epb wrong direction";
CM_ SG_ 960 VCRIGHT_a207_epbmEnableWrong "Right body controller: a207 epbm enable wrong";
CM_ SG_ 960 VCRIGHT_a208_epbFaulted "Right body controller: a208 epb faulted";
CM_ SG_ 960 VCRIGHT_a209_epbStateMisTime "Right body controller: a209 epb state mis time";
CM_ SG_ 960 VCRIGHT_a210_epbStateTime "Right body controller: a210 epb state time";
CM_ SG_ 960 VCRIGHT_a211_epbmUnderIStaticNew "Right body controller: a211 epbm under i static new";
CM_ SG_ 960 VCRIGHT_a212_epbmOverIStaticNew "Right body controller: a212 epbm over i static new";
CM_ SG_ 960 VCRIGHT_a213_epbmUnderIDynNew "Right body controller: a213 epbm under i dyn new";
CM_ SG_ 960 VCRIGHT_a214_epbmOverIDynNew "Right body controller: a214 epbm over i dyn new";
CM_ SG_ 960 VCRIGHT_a215_currentDesyncWarnin "Right body controller: a215 current desync warning";
CM_ SG_ 960 VCRIGHT_a216_SPI_MIA_debugData1 "Right body controller: a216 SPI MIA debug data1";
CM_ SG_ 960 VCRIGHT_a217_SPI_MIA_debugData2 "Right body controller: a217 SPI MIA debug data2";
CM_ SG_ 960 VCRIGHT_a218_motorDriverFault "Right body controller: a218 motor driver fault";
CM_ SG_ 960 VCRIGHT_a219_motorCurrentDropout "Right body controller: a219 motor current dropout";
CM_ SG_ 960 VCRIGHT_a220_reverseLightFaultUs "Right body controller: a220 reverse light fault user";
CM_ SG_ 960 VCRIGHT_a221_undervoltageLoadshe "Right body controller: a221 undervoltage loadshed triggered";
CM_ SG_ 960 VCRIGHT_a222_rearFasciaFogLightF "Right body controller: a222 rear fascia fog light fault user";
CM_ SG_ 960 VCRIGHT_a223_VCBATT1_MIA "Right body controller: a223 VCBATT1 MIA";
CM_ SG_ 960 VCRIGHT_a224_seatEncStallTrack "Right body controller: a224 seat enc stall track";
CM_ SG_ 960 VCRIGHT_a225_seatEncStallBack "Right body controller: a225 seat enc stall back";
CM_ SG_ 960 VCRIGHT_a226_seatEncStallTilt "Right body controller: a226 seat enc stall tilt";
CM_ SG_ 960 VCRIGHT_a227_seatEncStallLift "Right body controller: a227 seat enc stall lift";
CM_ SG_ 960 VCRIGHT_a228_seatEncOverTrack "Right body controller: a228 seat enc over track";
CM_ SG_ 960 VCRIGHT_a229_seatEncOverBack "Right body controller: a229 seat enc over back";
CM_ SG_ 960 VCRIGHT_a230_seatEncOverTilt "Right body controller: a230 seat enc over tilt";
CM_ SG_ 960 VCRIGHT_a231_seatEncOverLift "Right body controller: a231 seat enc over lift";
CM_ SG_ 960 VCRIGHT_a232_seatCurrUnderTrack "Right body controller: a232 seat curr under track";
CM_ SG_ 960 VCRIGHT_a233_seatCurrUnderBack "Right body controller: a233 seat curr under back";
CM_ SG_ 960 VCRIGHT_a234_seatCurrUnderTilt "Right body controller: a234 seat curr under tilt";
CM_ SG_ 960 VCRIGHT_a235_seatCurrUnderLift "Right body controller: a235 seat curr under lift";
CM_ SG_ 960 VCRIGHT_a236_lumbarOverPresA "Right body controller: a236 lumbar over pres a";
CM_ SG_ 960 VCRIGHT_a237_lumbarOverPresB "Right body controller: a237 lumbar over pres b";
CM_ SG_ 960 VCRIGHT_a238_lumbarValveMIA "Right body controller: a238 lumbar valve MIA";
CM_ SG_ 960 VCRIGHT_a239_seatHeatIFront "Right body controller: a239 seat heat i front";
CM_ SG_ 960 VCRIGHT_a240_seatHeatShortFront "Right body controller: a240 seat heat short front";
CM_ SG_ 960 VCRIGHT_a241_seatHeatMIAFront "Right body controller: a241 seat heat MIA front";
CM_ SG_ 960 VCRIGHT_a242_seatHeatIRearL "Right body controller: a242 seat heat i rear l";
CM_ SG_ 960 VCRIGHT_a243_seatHeatShortRearL "Right body controller: a243 seat heat short rear l";
CM_ SG_ 960 VCRIGHT_a244_seatHeatMIARearL "Right body controller: a244 seat heat MIA rear l";
CM_ SG_ 960 VCRIGHT_a245_seatHeatIRearC "Right body controller: a245 seat heat i rear c";
CM_ SG_ 960 VCRIGHT_a246_seatHeatShortRearC "Right body controller: a246 seat heat short rear c";
CM_ SG_ 960 VCRIGHT_a247_seatHeatMIARearC "Right body controller: a247 seat heat MIA rear c";
CM_ SG_ 960 VCRIGHT_a248_seatHeatIRearR "Right body controller: a248 seat heat i rear r";
CM_ SG_ 960 VCRIGHT_a249_seatHeatShortRearR "Right body controller: a249 seat heat short rear r";
CM_ SG_ 960 VCRIGHT_a250_seatHeatMIARearR "Right body controller: a250 seat heat MIA rear r";
CM_ SG_ 960 VCRIGHT_a251_seatUncalTrack "Right body controller: a251 seat uncal track";
CM_ SG_ 960 VCRIGHT_a252_seatUncalBack "Right body controller: a252 seat uncal back";
CM_ SG_ 960 VCRIGHT_a253_seatUncalTilt "Right body controller: a253 seat uncal tilt";
CM_ SG_ 960 VCRIGHT_a254_seatUncalLift "Right body controller: a254 seat uncal lift";
CM_ SG_ 960 VCRIGHT_a255_PTCOverTemp "Right body controller: a255 PTC over temp";
CM_ SG_ 960 VCRIGHT_a256_PTCCurrentDrawNoReq "Right body controller: a256 PTC current draw no req";
CM_ SG_ 960 VCRIGHT_a257_THSMIA "Right body controller: a257 THSMIA";
CM_ SG_ 960 VCRIGHT_a258_PTCStuckInBoot "Right body controller: a258 PTC stuck in boot";
CM_ SG_ 960 VCRIGHT_a259_latchDisarmDelayF "Right body controller: a259 latch disarm delay f";
CM_ SG_ 960 VCRIGHT_a260_latchDisarmDelayR "Right body controller: a260 latch disarm delay r";
CM_ SG_ 960 VCRIGHT_a261_emergencyLatchRelRe "Right body controller: a261 emergency latch rel rear";
CM_ SG_ 960 VCRIGHT_a262_PTCFaulted "Right body controller: a262 PTC faulted";
CM_ SG_ 960 VCRIGHT_a263_seatTrackStallDebug "Right body controller: a263 seat track stall debug";
CM_ SG_ 960 VCRIGHT_a264_seatBackStallDebug "Right body controller: a264 seat back stall debug";
CM_ SG_ 960 VCRIGHT_a265_seatTiltStallDebug "Right body controller: a265 seat tilt stall debug";
CM_ SG_ 960 VCRIGHT_a266_seatLiftStallDebug "Right body controller: a266 seat lift stall debug";
CM_ SG_ 960 VCRIGHT_a267_seatTrackHCEncStlDb "Right body controller: a267 seat track HC enc stl dbg";
CM_ SG_ 960 VCRIGHT_a268_seatBackHCEncStlDbg "Right body controller: a268 seat back HC enc stl dbg";
CM_ SG_ 960 VCRIGHT_a269_seatTiltHCEncStlDbg "Right body controller: a269 seat tilt HC enc stl dbg";
CM_ SG_ 960 VCRIGHT_a270_seatLiftHCEncStlDbg "Right body controller: a270 seat lift HC enc stl dbg";
CM_ SG_ 960 VCRIGHT_a271_THSSensorFault "Right body controller: a271 THS sensor fault";
CM_ SG_ 960 VCRIGHT_a272_vhclPwrStateMsmtch "Right body controller: a272 vhcl pwr state msmtch";
CM_ SG_ 960 VCRIGHT_a273_handleStuckActiveF "Right body controller: a273 handle stuck active f";
CM_ SG_ 960 VCRIGHT_a274_handleStuckActiveR "Right body controller: a274 handle stuck active r";
CM_ SG_ 960 VCRIGHT_a275_rightTurnLightFault "Right body controller: a275 right turn light fault";
CM_ SG_ 960 VCRIGHT_a276_mirrorDebug "Right body controller: a276 mirror debug";
CM_ SG_ 960 VCRIGHT_a277_BLERightUnderVoltag "Right body controller: a277 BLE right under voltage";
CM_ SG_ 960 VCRIGHT_a278_hvacPtcHeatingUnava "Right body controller: a278 hvac ptc heating unavailable";
CM_ SG_ 960 VCRIGHT_a279_trunkFailedToClose "Right body controller: a279 trunk failed to close";
CM_ SG_ 960 VCRIGHT_a280_latchDidNotDisarmF "Right body controller: a280 latch did not disarm f";
CM_ SG_ 960 VCRIGHT_a281_latchDidNotDisarmR "Right body controller: a281 latch did not disarm r";
CM_ SG_ 960 VCRIGHT_a282_latchUnexpectedArmF "Right body controller: a282 latch unexpected arm f";
CM_ SG_ 960 VCRIGHT_a283_latchUnexpectedArmR "Right body controller: a283 latch unexpected arm r";
CM_ SG_ 960 VCRIGHT_a284_gloveboxUnderCurren "Right body controller: a284 glovebox under current detected";
CM_ SG_ 960 VCRIGHT_a285_gloveboxOverCurrent "Right body controller: a285 glovebox over current detected";
CM_ SG_ 960 VCRIGHT_a286_windowSpeedInvalidF "Right body controller: a286 window speed invalid f";
CM_ SG_ 960 VCRIGHT_a287_windowSpeedInvalidR "Right body controller: a287 window speed invalid r";
CM_ SG_ 960 VCRIGHT_a288_handlePWMPeriodF "Right body controller: a288 handle PWM period f";
CM_ SG_ 960 VCRIGHT_a289_handlePWMPeriodR "Right body controller: a289 handle PWM period r";
CM_ SG_ 960 VCRIGHT_a290_occupancyFaultedFro "Right body controller: a290 occupancy faulted front";
CM_ SG_ 960 VCRIGHT_a291_buckleFaultedFront "Right body controller: a291 buckle faulted front";
CM_ SG_ 960 VCRIGHT_a292_buckleFaultedRearC "Right body controller: a292 buckle faulted rear c";
CM_ SG_ 960 VCRIGHT_a293_buckleFaultedRearR "Right body controller: a293 buckle faulted rear r";
CM_ SG_ 960 VCRIGHT_a294_occupancyFaultedRea "Right body controller: a294 occupancy faulted rear r";
CM_ SG_ 960 VCRIGHT_a295_occupancyFaulted3Ro "Right body controller: a295 occupancy faulted3 row l";
CM_ SG_ 960 VCRIGHT_a296_occupancyFaulted3Ro "Right body controller: a296 occupancy faulted3 row r";
CM_ SG_ 960 VCRIGHT_a297_seatBelowMinPumpTmp "Right body controller: a297 seat below min pump tmp";
CM_ SG_ 960 VCRIGHT_a298_buckleFaulted3RowL "Right body controller: a298 buckle faulted3 row l";
CM_ SG_ 960 VCRIGHT_a299_buckleFaulted3RowR "Right body controller: a299 buckle faulted3 row r";
CM_ SG_ 960 VCRIGHT_a300_VCFRONT1_MIA "Right body controller: a300 VCFRONT1 MIA";
CM_ SG_ 960 VCRIGHT_a301_airwaveRightVertica "Right body controller: a301 airwave right vertical warning";
CM_ SG_ 960 VCRIGHT_a302_airwaveRightVertica "Right body controller: a302 airwave right vertical unavailable";
CM_ SG_ 960 VCRIGHT_a303_eFuseMgmtWindowLift "Right body controller: a303 e fuse mgmt window lift";
CM_ SG_ 960 VCRIGHT_a304_frontIntHandleUnexp "Right body controller: a304 front int handle unexpected voltage";
CM_ SG_ 960 VCRIGHT_a305_rearIntHandleUnexpe "Right body controller: a305 rear int handle unexpected voltage";
CM_ SG_ 960 VCRIGHT_a306_handleDisconnectedF "Right body controller: a306 handle disconnected f";
CM_ SG_ 960 VCRIGHT_a307_handleDisconnectedR "Right body controller: a307 handle disconnected r";
CM_ SG_ 960 VCRIGHT_a308_airwaveRightLateral "Right body controller: a308 airwave right lateral unavailable";
CM_ SG_ 960 VCRIGHT_a310_mirrorFoldStall "Right body controller: a310 mirror fold stall";
CM_ SG_ 960 VCRIGHT_a311_rightBrakeLightFaul "Right body controller: a311 right brake light fault";
CM_ SG_ 960 VCRIGHT_a312_rightTailLightFault "Right body controller: a312 right tail light fault";
CM_ SG_ 960 VCRIGHT_a313_rightFootwellLightF "Right body controller: a313 right footwell light fault";
CM_ SG_ 960 VCRIGHT_a314_rightMapPocketLight "Right body controller: a314 right map pocket light fault";
CM_ SG_ 960 VCRIGHT_a315_rightInteriorTrunkL "Right body controller: a315 right interior trunk light fault";
CM_ SG_ 960 VCRIGHT_a316_mirrorPrematureFold "Right body controller: a316 mirror premature fold stall";
CM_ SG_ 960 VCRIGHT_a317_epbmLimpModeEnabled "Right body controller: a317 epbm limp mode enabled";
CM_ SG_ 960 VCRIGHT_a318_leftExteriorTrunkLi "Right body controller: a318 left exterior trunk light fault";
CM_ SG_ 960 VCRIGHT_a319_rightExteriorTrunkL "Right body controller: a319 right exterior trunk light fault";
CM_ SG_ 960 VCRIGHT_a320_windowReportCracked "Right body controller: a320 window report cracked at trim clear";
CM_ SG_ 960 VCRIGHT_a321_windowRezeroedDebug "Right body controller: a321 window rezeroed debug f";
CM_ SG_ 960 VCRIGHT_a322_windowRezeroedDebug "Right body controller: a322 window rezeroed debug r";
CM_ SG_ 960 VCRIGHT_a323_mirrorCalibrated "Right body controller: a323 mirror calibrated";
CM_ SG_ 960 VCRIGHT_a324_mirrorHeatFault "Right body controller: a324 mirror heat fault";
CM_ SG_ 960 VCRIGHT_a325_airwaveLeftVertical "Right body controller: a325 airwave left vertical unavailable";
CM_ SG_ 960 VCRIGHT_a326_airwaveLeftLateralU "Right body controller: a326 airwave left lateral unavailable";
CM_ SG_ 960 VCRIGHT_a327_airwaveLeftLateralW "Right body controller: a327 airwave left lateral warning";
CM_ SG_ 960 VCRIGHT_a328_airwaveLeftVertical "Right body controller: a328 airwave left vertical warning";
CM_ SG_ 960 VCRIGHT_a329_airwaveRightLateral "Right body controller: a329 airwave right lateral warning";
CM_ SG_ 960 VCRIGHT_a330_shortDropFailedF "Right body controller: a330 short drop failed f";
CM_ SG_ 960 VCRIGHT_a331_shortDropFailedR "Right body controller: a331 short drop failed r";
CM_ SG_ 960 VCRIGHT_a336_windowDropRevTherma "Right body controller: a336 window drop rev thermal f";
CM_ SG_ 960 VCRIGHT_a337_windowDropRevTherma "Right body controller: a337 window drop rev thermal r";
CM_ SG_ 960 VCRIGHT_a342_rearDefrostDisabled "Right body controller: a342 rear defrost disabled";
CM_ SG_ 960 VCRIGHT_a343_rearDefrostUndercur "Right body controller: a343 rear defrost undercurrent";
CM_ SG_ 960 VCRIGHT_a344_rearDefrostOvercurr "Right body controller: a344 rear defrost overcurrent";
CM_ SG_ 960 VCRIGHT_a345_HVACPTCHeaterPwrEFu "Right body controller: a345 HVACPTC heater pwr e fuse fault";
CM_ SG_ 960 VCRIGHT_a346_cabinRadarEFuseFaul "Right body controller: a346 cabin radar e fuse fault";
CM_ SG_ 960 VCRIGHT_a347_nonContMonitorClear "Right body controller: a347 non cont monitor cleared DBG";
CM_ SG_ 960 VCRIGHT_a352_audioCurrentSpikeDa "Right body controller: a352 audio current spike data";
CM_ SG_ 960 VCRIGHT_a355_hvacLHBleedWarning "Right body controller: a355 hvac LH bleed warning";
CM_ SG_ 960 VCRIGHT_a356_hvacRHBleedWarning "Right body controller: a356 hvac RH bleed warning";
CM_ SG_ 960 VCRIGHT_a357_hvacLHVaneWarning "Right body controller: a357 hvac LH vane warning";
CM_ SG_ 960 VCRIGHT_a358_hvacRHVaneWarning "Right body controller: a358 hvac RH vane warning";
CM_ SG_ 960 VCRIGHT_a359_hvacUpperModeWarnin "Right body controller: a359 hvac upper mode warning";
CM_ SG_ 960 VCRIGHT_a360_detectedStationaryW "Right body controller: a360 detected stationary while moving";
CM_ SG_ 960 VCRIGHT_a361_stationaryThreshold "Right body controller: a361 stationary thresholds incorrect";
CM_ SG_ 960 VCRIGHT_a362_movingThresholdsInc "Right body controller: a362 moving thresholds incorrect";
CM_ SG_ 960 VCRIGHT_a363_hvacLowerModeWarnin "Right body controller: a363 hvac lower mode warning";
CM_ SG_ 960 VCRIGHT_a364_hvacIntakeWarning "Right body controller: a364 hvac intake warning";
CM_ SG_ 960 VCRIGHT_a365_pitchUnlatchDisable "Right body controller: a365 pitch unlatch disabled";
CM_ SG_ 960 VCRIGHT_a366_trunkLatchUnhomed "Right body controller: a366 trunk latch unhomed";
CM_ SG_ 960 VCRIGHT_a367_trunkLatchSwFault "Right body controller: a367 trunk latch sw fault";
CM_ SG_ 960 VCRIGHT_a368_ductLeftLowerTempSn "Right body controller: a368 duct left lower temp sns";
CM_ SG_ 960 VCRIGHT_a369_ductRightLowerTempS "Right body controller: a369 duct right lower temp sns";
CM_ SG_ 960 VCRIGHT_a370_seat2RowPitchUnlatc "Right body controller: a370 seat2 row pitch unlatched";
CM_ SG_ 960 VCRIGHT_a371_seat2RowTrackUnlatc "Right body controller: a371 seat2 row track unlatched";
CM_ SG_ 960 VCRIGHT_a372_seat2RowBackrestUnl "Right body controller: a372 seat2 row backrest unlatched";
CM_ SG_ 960 VCRIGHT_a373_windowSwOpenReqInDo "Right body controller: a373 window sw open req in dog mode";
CM_ SG_ 960 VCRIGHT_a375_windowPinchOverride "Right body controller: a375 window pinch override nudge";
CM_ SG_ 960 VCRIGHT_a376_seat2RowBridgeCurre "Right body controller: a376 seat2 row bridge current exceeded";
CM_ SG_ 960 VCRIGHT_a377_ambientTempSns "Right body controller: a377 ambient temp sns";
CM_ SG_ 960 VCRIGHT_a378_ductLeftUpperTempSn "Right body controller: a378 duct left upper temp sns";
CM_ SG_ 960 VCRIGHT_a379_ductRightUpperTempS "Right body controller: a379 duct right upper temp sns";
CM_ SG_ 960 VCRIGHT_a380_reverseLightFault "Right body controller: a380 reverse light fault";
CM_ SG_ 960 VCRIGHT_a381_rearFogLightFault "Right body controller: a381 rear fog light fault";
CM_ SG_ 960 VCRIGHT_a382_leftLiftgateTailLig "Right body controller: a382 left liftgate tail light fault";
CM_ SG_ 960 VCRIGHT_a383_hvacRearWarning "Right body controller: a383 hvac rear warning";
CM_ SG_ 960 VCRIGHT_a385_glareShieldHeaterUn "Right body controller: a385 glare shield heater unavailable";
CM_ SG_ 960 VCRIGHT_a406_aptivOCSMIA "Right body controller: a406 aptiv OCSMIA";
CM_ SG_ 960 VCRIGHT_a407_aptivOCSInterfaceEr "Right body controller: a407 aptiv OCS interface error";
CM_ SG_ 960 VCRIGHT_a408_aptivOCSDeviceError "Right body controller: a408 aptiv OCS device error";
CM_ SG_ 960 VCRIGHT_a409_aptivOCSDeviceError "Right body controller: a409 aptiv OCS device error debug";
CM_ SG_ 960 VCRIGHT_a411_undervoltageSelfTes "Right body controller: a411 undervoltage self test failure";
CM_ SG_ 960 VCRIGHT_a412_rightBrakeTailLight "Right body controller: a412 right brake tail light fault";
CM_ SG_ 960 VCRIGHT_a413_centerHighMountStop "Right body controller: a413 center high mount stop light fault";
CM_ SG_ 960 VCRIGHT_a414_rearFasciaReverseLi "Right body controller: a414 rear fascia reverse light fault";
CM_ SG_ 960 VCRIGHT_a415_rearFasciaFogLightF "Right body controller: a415 rear fascia fog light fault";
CM_ SG_ 960 VCRIGHT_a416_rearFasciaTailLight "Right body controller: a416 rear fascia tail light fault";
CM_ SG_ 960 VCRIGHT_a417_rearFasciaLeftTurnL "Right body controller: a417 rear fascia left turn light fault";
CM_ SG_ 960 VCRIGHT_a418_rearFasciaRightTurn "Right body controller: a418 rear fascia right turn light fault";
CM_ SG_ 960 VCRIGHT_a419_tailFasciaLeftLight "Right body controller: a419 tail fascia left light fault";
CM_ SG_ 960 VCRIGHT_a420_tailFasciaRightLigh "Right body controller: a420 tail fascia right light fault";
CM_ SG_ 960 VCRIGHT_a421_leftTailLightFault "Right body controller: a421 left tail light fault";
CM_ SG_ 960 VCRIGHT_a422_undervoltageSelfTes "Right body controller: a422 undervoltage self test stuck off";
CM_ SG_ 960 VCRIGHT_a426_seatAbuseMotorWarn "Right body controller: a426 seat abuse motor warn";
CM_ SG_ 960 VCRIGHT_a427_seatAbuseMotorStop "Right body controller: a427 seat abuse motor stop";
CM_ SG_ 960 VCRIGHT_a428_seatAbuseBufferWarn "Right body controller: a428 seat abuse buffer warn";
CM_ SG_ 960 VCRIGHT_a429_seatAbuseBufferFull "Right body controller: a429 seat abuse buffer full";
CM_ SG_ 960 VCRIGHT_a444_drv8703Fault "Right body controller: a444 drv8703 fault";
CM_ SG_ 960 VCRIGHT_a445_drv8703SpiFaultDBG "Right body controller: a445 drv8703 spi fault DBG";
CM_ SG_ 960 VCRIGHT_a446_cabinHVACUnavailabl "Right body controller: a446 cabin HVAC unavailable context";
CM_ SG_ 960 VCRIGHT_a448_manualHVACAlert "Right body controller: a448 manual HVAC alert";
CM_ SG_ 960 VCRIGHT_a450_ptcForcedOutOfSeqRo "Right body controller: a450 ptc forced out of seq rod";
CM_ SG_ 960 VCRIGHT_a451_ptcSeqRodOutOfRetri "Right body controller: a451 ptc seq rod out of retries";
CM_ SG_ 960 VCRIGHT_a454_ptcHeaterBadRodDete "Right body controller: a454 ptc heater bad rod detected";
CM_ SG_ 960 VCRIGHT_a482_NCV77XXFault "Right body controller: a482 NCV77 XX fault";
CM_ SG_ 960 VCRIGHT_a483_rightTurnLightFault "Right body controller: a483 right turn light fault user";
CM_ SG_ 960 VCRIGHT_a484_rightBrakeLightFaul "Right body controller: a484 right brake light fault user";
CM_ SG_ 960 VCRIGHT_a485_leftTailLightFaultU "Right body controller: a485 left tail light fault user";
CM_ SG_ 960 VCRIGHT_a486_rightTailLightFault "Right body controller: a486 right tail light fault user";
CM_ SG_ 960 VCRIGHT_a487_centerHighMountStop "Right body controller: a487 center high mount stop light fault user";
CM_ SG_ 960 VCRIGHT_a488_undervoltageSelfTes "Right body controller: a488 undervoltage self test stuck on debug";
CM_ SG_ 960 VCRIGHT_a489_undervoltageSelfTes "Right body controller: a489 undervoltage self test stuck on";
CM_ SG_ 960 VCRIGHT_a490_vehicleOccupiedOnOT "Right body controller: a490 vehicle occupied on OTA start";
CM_ SG_ 960 VCRIGHT_a491_BPillarCameraHeater "Right body controller: a491 b pillar camera heater fault";
CM_ SG_ 960 VCRIGHT_a492_uvSelfTestLoadUnatt "Right body controller: a492 uv self test load unattempted on dbg";
CM_ SG_ 960 VCRIGHT_a496_gloveboxOpenFailed "Right body controller: a496 glovebox open failed";
CM_ SG_ 960 VCRIGHT_a497_CANMsgMACVerificati "Right body controller: a497 CAN msg MAC verification key not provisioned";
CM_ SG_ 960 VCRIGHT_a498_CANMsgMACVerificati "Right body controller: a498 CAN msg MAC verification failure";
CM_ SG_ 960 VCRIGHT_a499_epbmInvalidateCdp "Right body controller: a499 epbm invalidate cdp";
CM_ SG_ 960 VCRIGHT_a510_3RowSeatUncalibrate "Right body controller: a510 3 row seat uncalibrated";
CM_ SG_ 960 VCRIGHT_a511_3RowSeatPositionNon "Right body controller: a511 3 row seat position nonsensical";
CM_ SG_ 960 VCRIGHT_a512_3RowSeatAbsPosOffse "Right body controller: a512 3 row seat abs pos offset applied";
CM_ SG_ 960 VCRIGHT_a513_3RowSeatObstacleDet "Right body controller: a513 3 row seat obstacle detected";
CM_ SG_ 960 VCRIGHT_a514_3RowSeatTempHigh "Right body controller: a514 3 row seat temp high";
CM_ SG_ 960 VCRIGHT_a515_3RowSeatAbsPosSenso "Right body controller: a515 3 row seat abs pos sensor transition dbg";
CM_ SG_ 960 VCRIGHT_a516_3RowSeatStatsFromLa "Right body controller: a516 3 row seat stats from last state dbg";
CM_ SG_ 960 VCRIGHT_a517_3RowSeatRequestWhil "Right body controller: a517 3 row seat request while uncalibrated";
CM_ SG_ 960 VCRIGHT_a518_3RowSeatClashAvoida "Right body controller: a518 3 row seat clash avoidance blocked";
CM_ SG_ 960 VCRIGHT_a519_3RowSeatOverfolded "Right body controller: a519 3 row seat overfolded";
CM_ SG_ 960 VCRIGHT_a520_configMismatch "Right body controller: a520 config mismatch";
CM_ SG_ 960 VCRIGHT_a525_LVBatterySWMisconfi "Right body controller: a525 LV battery SW misconfiguration";
CM_ SG_ 960 VCRIGHT_a526_pcbaOverTemperature "Right body controller: a526 pcba over temperature";
CM_ SG_ 960 VCRIGHT_a527_continuousFeedUnexp "Right body controller: a527 continuous feed unexpected voltage";
CM_ SG_ 960 VCRIGHT_a528_unableToRunStuckOnT "Right body controller: a528 unable to run stuck on test";
CM_ SG_ 960 VCRIGHT_a529_airflowFeedBackMode "Right body controller: a529 airflow feed back model error";
CM_ SG_ 960 VCRIGHT_a531_airflowModelTmpComp "Right body controller: a531 airflow model tmp comp disabled";
CM_ SG_ 960 VCRIGHT_a532_airflowModelFeedFor "Right body controller: a532 airflow model feed forward error";
CM_ SG_ 960 VCRIGHT_a533_cabinModelDebug "Right body controller: a533 cabin model debug";
CM_ SG_ 960 VCRIGHT_a537_solarCalcsNotNomina "Right body controller: a537 solar calcs not nominal";
CM_ SG_ 960 VCRIGHT_a538_hvacSystemNotNomina "Right body controller: a538 hvac system not nominal";
CM_ SG_ 960 VCRIGHT_a539_dogModeMonitorTrip "Right body controller: a539 dog mode monitor trip";
CM_ SG_ 960 VCRIGHT_a540_hvacActuatorDitherD "Right body controller: a540 hvac actuator dither debug";
CM_ SG_ 960 VCRIGHT_a542_steeringWheelHeatin "Right body controller: a542 steering wheel heating inhibited";
CM_ SG_ 960 VCRIGHT_a545_LVBatteryTypeUnknow "Right body controller: a545 LV battery type unknown";
CM_ SG_ 960 VCRIGHT_a546_mirrorFoldTypeChang "Right body controller: a546 mirror fold type changed";
CM_ SG_ 960 VCRIGHT_a550_ambientTempDelta "Right body controller: a550 ambient temp delta";
CM_ SG_ 960 VCRIGHT_a551_interiorDoorRequest "Right body controller: a551 interior door request inhibited";
CM_ SG_ 960 VCRIGHT_a555_RCM2_MIA "Right body controller: a555 RCM2 MIA";
CM_ SG_ 960 VCRIGHT_a556_rcmReportedOCSError "Right body controller: a556 rcm reported OCS error";
CM_ SG_ 960 VCRIGHT_a560_2RowSeatUncalibrate "Right body controller: a560 2 row seat uncalibrated";
CM_ SG_ 960 VCRIGHT_a561_2RowSeatPositionNon "Right body controller: a561 2 row seat position nonsensical";
CM_ SG_ 960 VCRIGHT_a562_2RowSeatAbsPosOffse "Right body controller: a562 2 row seat abs pos offset applied";
CM_ SG_ 960 VCRIGHT_a563_2RowSeatObstacleDet "Right body controller: a563 2 row seat obstacle detected";
CM_ SG_ 960 VCRIGHT_a564_2RowSeatTempHigh "Right body controller: a564 2 row seat temp high";
CM_ SG_ 960 VCRIGHT_a565_2RowSeatAbsPosSenso "Right body controller: a565 2 row seat abs pos sensor transition dbg";
CM_ SG_ 960 VCRIGHT_a566_2RowSeatStatsFromLa "Right body controller: a566 2 row seat stats from last state dbg";
CM_ SG_ 960 VCRIGHT_a567_2RowSeatRequestWhil "Right body controller: a567 2 row seat request while uncalibrated";
CM_ SG_ 960 VCRIGHT_a568_2RowSeatClashAvoida "Right body controller: a568 2 row seat clash avoidance blocked";
CM_ SG_ 960 VCRIGHT_a569_2RowSeatOverfolded "Right body controller: a569 2 row seat overfolded";
CM_ SG_ 960 VCRIGHT_a570_seatHeatDisabledF "Right body controller: a570 seat heat disabled f";
CM_ SG_ 960 VCRIGHT_a571_seatHeatDisabledRea "Right body controller: a571 seat heat disabled rear l";
CM_ SG_ 960 VCRIGHT_a572_seatHeatDisabledRea "Right body controller: a572 seat heat disabled rear c";
CM_ SG_ 960 VCRIGHT_a573_seatHeatDisabledRea "Right body controller: a573 seat heat disabled rear r";
CM_ SG_ 960 VCRIGHT_a574_2RowSeatStatsFromLa "Right body controller: a574 2 row seat stats from last state dbg2";
CM_ SG_ 960 VCRIGHT_a575_3RowSeatStatsFromLa "Right body controller: a575 3 row seat stats from last state dbg2";
CM_ SG_ 960 VCRIGHT_a577_bsiHardwareIssue "Right body controller: a577 bsi hardware issue";
CM_ SG_ 960 VCRIGHT_a578_RGBLightFault "Right body controller: a578 RGB light fault";
CM_ SG_ 960 VCRIGHT_a579_liftgateFollowerUne "Right body controller: a579 liftgate follower unexpected stop";
CM_ SG_ 960 VCRIGHT_a580_debugLiftgateFollow "Right body controller: a580 debug liftgate follower current spike";
CM_ SG_ 960 VCRIGHT_a583_doorRemoteUnlatched "Right body controller: a583 door remote unlatched front";
CM_ SG_ 960 VCRIGHT_a584_doorRemoteUnlatched "Right body controller: a584 door remote unlatched rear";
CM_ SG_ 960 VCRIGHT_a585_doorRemoteUnlatchFa "Right body controller: a585 door remote unlatch failed front";
CM_ SG_ 960 VCRIGHT_a586_doorRemoteUnlatchFa "Right body controller: a586 door remote unlatch failed rear";
CM_ SG_ 960 VCRIGHT_a587_VCSEAT2L_MIA "Right body controller: a587 VCSEAT2 l MIA";
CM_ SG_ 960 VCRIGHT_a588_VCSEAT2R_MIA "Right body controller: a588 VCSEAT2 r MIA";
CM_ SG_ 960 VCRIGHT_a589_defogSysDriverlessS "Right body controller: a589 defog sys driverless self test";
CM_ SG_ 960 VCRIGHT_a590_seatEncStallThighSu "Right body controller: a590 seat enc stall thigh support";
CM_ SG_ 960 VCRIGHT_a591_seatCurrUnderThighS "Right body controller: a591 seat curr under thigh support";
CM_ SG_ 960 VCRIGHT_a592_seatUncalThighSuppo "Right body controller: a592 seat uncal thigh support";
CM_ SG_ 960 VCRIGHT_a593_seatEncOverThighSup "Right body controller: a593 seat enc over thigh support";
CM_ SG_ 960 VCRIGHT_a594_seatThighSupportSta "Right body controller: a594 seat thigh support stall debug";
CM_ SG_ 960 VCRIGHT_a595_seatThighSupportHCE "Right body controller: a595 seat thigh support HC enc stl dbg";
CM_ SG_ 960 VCRIGHT_a596_frontDoorLatchUnexp "Right body controller: a596 front door latch unexpected voltage";
CM_ SG_ 960 VCRIGHT_a597_rearDoorLatchUnexpe "Right body controller: a597 rear door latch unexpected voltage";
CM_ SG_ 960 VCRIGHT_a598_childModeMonitorTri "Right body controller: a598 child mode monitor trip";
CM_ SG_ 960 VCRIGHT_a599_LVBatteryTypeUnsupp "Right body controller: a599 LV battery type unsupported";
CM_ SG_ 960 VCRIGHT_a601_wakeToOpenDoorDbg "Right body controller: a601 wake to open door dbg";
CM_ SG_ 960 VCRIGHT_a605_CANMsgMACVerificati "Right body controller: a605 CAN msg MAC verification key mismatch";
CM_ SG_ 960 VCRIGHT_a617_APP_MIA "Right body controller: a617 APP MIA";
CM_ BO_ 1795 "Right body controller message: debug thermal10 hz";
CM_ SG_ 1795 VCRIGHT_debugThermal10HzIndex "Right body controller: debug thermal10 hz index";
CM_ SG_ 1795 VCRIGHT_hvacPanelFloorSplitRow1 "Right body controller: hvac panel floor split row1";
CM_ SG_ 1795 VCRIGHT_hvacDefrostPercent "Right body controller: hvac defrost percent";
CM_ SG_ 1795 VCRIGHT_hvacRow2Percent "Right body controller: hvac row2 percent";
CM_ SG_ 1795 VCRIGHT_hvacPanelFloorSplitRow2 "Right body controller: hvac panel floor split row2";
CM_ SG_ 1795 VCRIGHT_hvacFreshMassCounter "Right body controller: hvac fresh mass counter";
CM_ SG_ 1795 VCRIGHT_hvacRecircMassCounter "Right body controller: hvac recirc mass counter";
CM_ SG_ 1795 VCRIGHT_setTempAdjustmentLeft "Right body controller: set temp adjustment left; raw 127 = signal not available (SNA)";
CM_ SG_ 1795 VCRIGHT_setTempAdjustmentRight "Right body controller: set temp adjustment right; raw 127 = signal not available (SNA)";
CM_ SG_ 1795 VCRIGHT_hvacLHVaneVelocity "Right body controller: hvac LH vane velocity";
CM_ SG_ 1795 VCRIGHT_hvacRHVaneVelocity "Right body controller: hvac RH vane velocity";
CM_ SG_ 1795 VCRIGHT_hvacVehicleSpeed "Right body controller: hvac vehicle speed";
CM_ SG_ 1795 VCRIGHT_hvacMassflowCompensated "Right body controller: hvac massflow compensated";
CM_ SG_ 1795 VCRIGHT_PTCcenterPowerLeft "Right body controller: PT ccenter power left; raw 63 = signal not available (SNA)";
CM_ SG_ 1795 VCRIGHT_PTCouterPowerLeft "Right body controller: PT couter power left; raw 63 = signal not available (SNA)";
CM_ SG_ 1795 VCRIGHT_PTCinnerPowerLeft "Right body controller: PT cinner power left; raw 63 = signal not available (SNA)";
CM_ SG_ 1795 VCRIGHT_PTCcenterPowerRight "Right body controller: PT ccenter power right; raw 63 = signal not available (SNA)";
CM_ SG_ 1795 VCRIGHT_PTCouterPowerRight "Right body controller: PT couter power right; raw 63 = signal not available (SNA)";
CM_ SG_ 1795 VCRIGHT_PTCinnerPowerRight "Right body controller: PT cinner power right; raw 63 = signal not available (SNA)";
CM_ SG_ 1795 VCRIGHT_PTCcenterStoneTempLeft "Right body controller: PT ccenter stone temp left; raw 255 = signal not available (SNA)";
CM_ SG_ 1795 VCRIGHT_PTCcenterStoneTempRight "Right body controller: PT ccenter stone temp right; raw 255 = signal not available (SNA)";
CM_ SG_ 1795 VCRIGHT_PTCinnerStoneTempLeft "Right body controller: PT cinner stone temp left; raw 255 = signal not available (SNA)";
CM_ SG_ 1795 VCRIGHT_PTCinnerStoneTempRight "Right body controller: PT cinner stone temp right; raw 255 = signal not available (SNA)";
CM_ SG_ 1795 VCRIGHT_PTCouterStoneTempLeft "Right body controller: PT couter stone temp left; raw 255 = signal not available (SNA)";
CM_ SG_ 1795 VCRIGHT_PTCouterRodTempLeft "Right body controller: PT couter rod temp left; raw 255 = signal not available (SNA)";
CM_ SG_ 1795 VCRIGHT_PTCouterAirTempLeft "Right body controller: PT couter air temp left; raw 255 = signal not available (SNA)";
CM_ SG_ 1795 VCRIGHT_PTCcenterRodTempLeft "Right body controller: PT ccenter rod temp left; raw 255 = signal not available (SNA)";
CM_ SG_ 1795 VCRIGHT_PTCinnerRodTempLeft "Right body controller: PT cinner rod temp left; raw 255 = signal not available (SNA)";
CM_ SG_ 1795 VCRIGHT_PTCcenterAirTempLeft "Right body controller: PT ccenter air temp left; raw 255 = signal not available (SNA)";
CM_ SG_ 1795 VCRIGHT_PTCinnerAirTempLeft "Right body controller: PT cinner air temp left; raw 255 = signal not available (SNA)";
CM_ SG_ 1795 VCRIGHT_PTCouterStoneTempRight "Right body controller: PT couter stone temp right; raw 255 = signal not available (SNA)";
CM_ SG_ 1795 VCRIGHT_PTCouterRodTempRight "Right body controller: PT couter rod temp right; raw 255 = signal not available (SNA)";
CM_ SG_ 1795 VCRIGHT_PTCouterAirTempRight "Right body controller: PT couter air temp right; raw 255 = signal not available (SNA)";
CM_ SG_ 1795 VCRIGHT_PTCcenterRodTempRight "Right body controller: PT ccenter rod temp right; raw 255 = signal not available (SNA)";
CM_ SG_ 1795 VCRIGHT_PTCinnerRodTempRight "Right body controller: PT cinner rod temp right; raw 255 = signal not available (SNA)";
CM_ SG_ 1795 VCRIGHT_PTCcenterAirTempRight "Right body controller: PT ccenter air temp right; raw 255 = signal not available (SNA)";
CM_ SG_ 1795 VCRIGHT_PTCinnerAirTempRight "Right body controller: PT cinner air temp right; raw 255 = signal not available (SNA)";
CM_ BO_ 259 "Right body controller message: door status";
CM_ SG_ 259 VCRIGHT_doorClosureStatusFront "Status of the door from a closures perspective; raw 0 = signal not available (SNA)";
CM_ SG_ 259 VCRIGHT_doorClosureStatusRear "Status of the door from a closures perspective; raw 0 = signal not available (SNA)";
CM_ SG_ 259 VCRIGHT_frontLatchSwitch "State of front left door latch switch representing door open/closed. 0 is open and 1 is closed";
CM_ SG_ 259 VCRIGHT_rearLatchSwitch "State of rear right door latch switch representing door open/closed. 0 is open and 1 is closed";
CM_ SG_ 259 VCRIGHT_frontHandlePulled "Right body controller: front handle pulled";
CM_ SG_ 259 VCRIGHT_rearHandlePulled "Right body controller: rear handle pulled";
CM_ SG_ 259 VCRIGHT_frontRelActuatorSwitch "State of front left door latch switch representing latch arm/unarmed. Disarms while door handle is pulled.";
CM_ SG_ 259 VCRIGHT_rearRelActuatorSwitch "State of rear right door latch switch representing latch arm/unarmed. Disarms while door handle is pulled";
CM_ SG_ 259 VCRIGHT_frontLatchStatus "Status of right front door latch; raw 0 = signal not available (SNA)";
CM_ SG_ 259 VCRIGHT_rearLatchStatus "Status of rear right door latch; raw 0 = signal not available (SNA)";
CM_ SG_ 259 VCRIGHT_lastDoorReqSourceFront "last source of front door open request";
CM_ SG_ 259 VCRIGHT_lastDoorReqSourceRear "last source of rear door open request";
CM_ SG_ 259 VCRIGHT_frontIntSwitchFaulted "Indicates if the front door interior button is faulted";
CM_ SG_ 259 VCRIGHT_rearIntSwitchFaulted "Indicates if the rear door interior button is faulted";
CM_ SG_ 259 VCRIGHT_frontHandlePulledPersist "Right body controller: front handle pulled persist";
CM_ SG_ 259 VCRIGHT_frontIntSwitchPressed "Right body controller: front int switch pressed";
CM_ SG_ 259 VCRIGHT_rearIntSwitchPressed "Right body controller: rear int switch pressed";
CM_ SG_ 259 VCRIGHT_mirrorTiltXPosition "Value representing right side view mirror tilt horizontal position";
CM_ SG_ 259 VCRIGHT_mirrorTiltYPosition "Value representing right side view mirror tilt vertical position";
CM_ SG_ 259 VCRIGHT_mirrorState "State of the right side view mirror.";
CM_ SG_ 259 VCRIGHT_mirrorFoldState "Fold state for the right side view mirror";
CM_ SG_ 259 VCRIGHT_mirrorDipped "Reports if the side view mirrors in are in the dipped position.";
CM_ SG_ 259 VCRIGHT_trunkLatchStatus "State of the trunk latch; raw 0 = signal not available (SNA)";
CM_ SG_ 259 VCRIGHT_mirrorRecallState "State of Mirror Recall.";
CM_ SG_ 259 VCRIGHT_rearHandlePulledPersist "Right body controller: rear handle pulled persist";
CM_ BO_ 2010 "Right body controller message: door status2";
CM_ SG_ 2010 VCRIGHT_doorStatus2Index "Right body controller: door status2 index";
CM_ SG_ 2010 VCRIGHT_frontLatchRelDuty "Front left door latch motor duty cycle.";
CM_ SG_ 2010 VCRIGHT_BPillarCameraHeaterState "Indicates the state of the right b-pillar camera heater; raw 0 = signal not available (SNA)";
CM_ SG_ 2010 VCRIGHT_doorLatchAjarSwitchVolta "Door latch switch voltage feeding switch logic";
CM_ SG_ 2010 VCRIGHT_doorLatchAjarSwitch_0001 "Door latch switch voltage feeding switch logic";
CM_ SG_ 2010 VCRIGHT_BPillarCameraHeaterCurre "Current drawn by the right b-pillar camera heater; raw 63 = signal not available (SNA)";
CM_ SG_ 2010 VCRIGHT_mirrorTiltXOffset "Communicates post calibration position offset of right side view mirror tilt horizontal position";
CM_ SG_ 2010 VCRIGHT_mirrorTiltYOffset "Communicates post calibration position offset of right side view mirror tilt vertical position";
CM_ BO_ 915 "Right body controller message: epbm debug";
CM_ SG_ 915 VCRIGHT_epbmDebugIndex "Right body controller: epbm debug index";
CM_ SG_ 915 VCRIGHT_epbmCaliperState "Right body controller: epbm caliper state";
CM_ SG_ 915 VCRIGHT_epbmMotorEnabled "Right body controller: epbm motor enabled";
CM_ SG_ 915 VCRIGHT_epbMotorCurrent "Right body controller: epb motor current";
CM_ SG_ 915 VCRIGHT_epbmApplyVoltage "Right body controller: epbm apply voltage";
CM_ SG_ 915 VCRIGHT_epbmReleaseVoltage "Right body controller: epbm release voltage";
CM_ SG_ 915 VCRIGHT_summonFaultReason "Electronic Parking Brake Monitors error code associated with previous summon failure.";
CM_ SG_ 915 VCRIGHT_epbSummonState "Electronic Parking Brake Monitors reading of Electronic Parking Brake's summon state.";
CM_ SG_ 915 VCRIGHT_epbmSummonState "Electronic Parking Brake Monitors summon state.";
CM_ SG_ 915 VCRIGHT_epbUnitStatus "Electronic Parking Brake Monitors reading of Electronic Parking Brake's state.";
CM_ SG_ 915 VCRIGHT_epbmFaultStatus "Electronic Parking Brake Monitors fault state.";
CM_ SG_ 915 VCRIGHT_epbFaultStatus "Electronic Parking Brake Monitors reading of Electronic Parking Brake's fault state.";
CM_ SG_ 915 VCRIGHT_epbmSystemStatus "Electronic Parking Brake Monitors reading of Electronic Parking Brake's state.";
CM_ SG_ 915 VCRIGHT_epbmAutonomyBehavior "Right body controller: epbm autonomy behavior";
CM_ BO_ 1123 "Right body controller message: epbm status";
CM_ SG_ 1123 VCRIGHT_cdpRequestState "If the Electronic Parking Brake makes a Controlled Deceleration for Parking Brake request, when cdpOkayToRequest is EPB_CDP_REQUEST_INVALID, cdpRequestState shall transition to EPB_CDP_REQUEST_INVALID, untill the Electronic Parking Brake Monitor enters unitStatus PARKED. Stability Control listens to this signal to qualify Controlled Deceleration for Parking Brake requests from the Electronic Parking Brake.";
CM_ SG_ 1123 VCRIGHT_epbmSystemStatusQF "Right body controller: epbm system status QF";
CM_ SG_ 1123 VCRIGHT_epbmUnitStatus "Electronic Parking Brake Monitors state.";
CM_ SG_ 1123 VCRIGHT_epbmCdpState "Right body controller: epbm cdp state";
CM_ SG_ 1123 VCRIGHT_epbmRedundantBrakingEnab "Right body controller: epbm redundant braking enabled";
CM_ SG_ 1123 VCRIGHT_epbmStatusCounter "Right body controller: epbm status counter";
CM_ SG_ 1123 VCRIGHT_epbmStatusChecksum "Right body controller: epbm status checksum";
CM_ BO_ 524 "Right body controller message: hvac request";
CM_ SG_ 524 VCRIGHT_wattsDemandEvap "Right body controller: watts demand evap";
CM_ SG_ 524 VCRIGHT_hvacEvapEnabled "Right body controller: hvac evap enabled";
CM_ SG_ 524 VCRIGHT_conditioningRequest "Right body controller: conditioning request";
CM_ SG_ 524 VCRIGHT_tempEvaporator "Evaporator temperature; raw 2047 = signal not available (SNA)";
CM_ SG_ 524 VCRIGHT_tempEvaporatorTarget "Evaporator temperature target; raw 255 = signal not available (SNA)";
CM_ SG_ 524 VCRIGHT_hvacBlowerSpeedRPMReq "Right body controller: hvac blower speed RPM req";
CM_ SG_ 524 VCRIGHT_hvacPerfTestRunning "Right body controller: hvac perf test running";
CM_ SG_ 524 VCRIGHT_evapPerformanceLow "Right body controller: evap performance low";
CM_ SG_ 524 VCRIGHT_tempAmbientRaw "Right body controller: temp ambient raw; raw 0 = signal not available (SNA)";
CM_ SG_ 524 VCRIGHT_hvacHeatingEnabledLeft "Right body controller: hvac heating enabled left";
CM_ SG_ 524 VCRIGHT_hvacHeatingEnabledRight "Right body controller: hvac heating enabled right";
CM_ SG_ 524 VCRIGHT_hvacPerfTestState "The HVAC performance test running state";
CM_ SG_ 524 VCRIGHT_hvacUnavailable "Right body controller: hvac unavailable";
CM_ SG_ 524 VCRIGHT_hvacBlowerRPMActualAP "Right body controller: hvac blower RPM actual AP";
CM_ SG_ 524 VCRIGHT_hvacEvapEnabledInColdAmb "Right body controller: hvac evap enabled in cold ambient";
CM_ BO_ 579 "Right body controller message: hvac status";
CM_ SG_ 579 VCRIGHT_hvacStatusIndex "Right body controller: hvac status index";
CM_ SG_ 579 VCRIGHT_warmingUpStatus "Right body controller: warming up status";
CM_ SG_ 579 VCRIGHT_coolingDownStatus "Right body controller: cooling down status";
CM_ SG_ 579 VCRIGHT_childModeHVACState "Right body controller: child mode HVAC state";
CM_ SG_ 579 VCRIGHT_dogModeState "Reports the state of Dog Mode.";
CM_ SG_ 579 VCRIGHT_hvacCabinTempEstValid "Right body controller: hvac cabin temp est valid";
CM_ SG_ 579 VCRIGHT_COPNotRunningReasonFilte "Reports the reason cabin overheat protection is not running for User Interface (UI).";
CM_ SG_ 579 VCRIGHT_hvacCabinTempEst "Estimated temperature of the cabin";
CM_ SG_ 579 VCRIGHT_hvacAirDistributionMode "Cabin airflow distribution";
CM_ SG_ 579 VCRIGHT_hvacBlowerSegment "Cabin airflow blower set speed segment";
CM_ SG_ 579 VCRIGHT_hvacRecirc "UI airflow recirculation request state";
CM_ SG_ 579 VCRIGHT_hvacACRunning "Air conditioning is active";
CM_ SG_ 579 VCRIGHT_hvacPowerState "Commanded HVAC power state from UI";
CM_ SG_ 579 VCRIGHT_hvacVentStatus "HVAC vent status";
CM_ SG_ 579 VCRIGHT_hvacSecondRowState "Right body controller: hvac second row state";
CM_ SG_ 579 VCRIGHT_hvacSystemNominal "HVAC system state";
CM_ SG_ 579 VCRIGHT_hvacModelInitStatus "Right body controller: hvac model init status";
CM_ SG_ 579 VCRIGHT_hvacMassflowRefrigSysRig "Right body controller: hvac massflow refrig sys right";
CM_ SG_ 579 VCRIGHT_hvacRecircDoorPercent "Reports the HVAC air recirculation massflow fraction target.";
CM_ SG_ 579 VCRIGHT_tempDuctLeft "Fusion of upper and lower left duct temp sensor values for Heat Pump HVAC case, Raw left/right duct temp sensor value for the legacy HVAC case; raw 255 = signal not available (SNA)";
CM_ SG_ 579 VCRIGHT_hvacMassflowRefrigSystem "Right body controller: hvac massflow refrig system";
CM_ SG_ 579 VCRIGHT_tempDuctRight "Fusion of upper and lower right duct temp sensor values for Heat Pump HVAC case, Raw left/right duct temp sensor value for the legacy HVAC case; raw 255 = signal not available (SNA)";
CM_ SG_ 579 VCRIGHT_hvacMassflowRefrigSysLef "Right body controller: hvac massflow refrig sys left";
CM_ SG_ 579 VCRIGHT_hvacDuctTargetLeft "Left airflow duct temperature target; raw 255 = signal not available (SNA)";
CM_ SG_ 579 VCRIGHT_hvacDuctTargetRight "Right airflow duct temperature target; raw 255 = signal not available (SNA)";
CM_ SG_ 579 VCRIGHT_enableTripleCameraFanPow "Right body controller: enable triple camera fan power in sleep";
CM_ SG_ 579 VCRIGHT_tempDuctRightUpper "Right body controller: temp duct right upper; raw 255 = signal not available (SNA)";
CM_ SG_ 579 VCRIGHT_hpSplitTempsEnabled "Right body controller: hp split temps enabled";
CM_ SG_ 579 VCRIGHT_hvacEvapInletTempEstimat "Right body controller: hvac evap inlet temp estimate; raw 1023 = signal not available (SNA)";
CM_ SG_ 579 VCRIGHT_tempMonitorNotNominal "Right body controller: temp monitor not nominal";
CM_ SG_ 579 VCRIGHT_hvacCabinAtTempTarget "Cabin has reached target temp, send signal to UI";
CM_ SG_ 579 VCRIGHT_hvacReqSecondRow "Right body controller: hvac req second row";
CM_ SG_ 579 VCRIGHT_hvacAirflowReason "Reason for cabin airflow";
CM_ SG_ 579 VCRIGHT_autoHvacBlowerShouldLimi "Cabin airflow blower auto set speed recommendation based on NVH";
CM_ SG_ 579 VCRIGHT_hvacReqThirdRow "Right body controller: hvac req third row";
CM_ SG_ 579 VCRIGHT_solarLoadOnVehicle "Right body controller: solar load on vehicle; raw 255 = signal not available (SNA)";
CM_ SG_ 579 VCRIGHT_refrigDistCommanded "The HVAC system has set its settings to run the refrigerant distribution routine";
CM_ SG_ 579 VCRIGHT_hvacFrontRightSeatFanSta "Right body controller: hvac front right seat fan status";
CM_ SG_ 579 VCRIGHT_hvacFrontLeftSeatFanStat "Right body controller: hvac front left seat fan status";
CM_ SG_ 579 VCRIGHT_hvacRefHighPowerRequest "Right body controller: hvac ref high power request";
CM_ SG_ 579 VCRIGHT_windshieldCameraHeaterDu "Right body controller: windshield camera heater duty request";
CM_ SG_ 579 VCRIGHT_extendedHvacPerfTestSupp "The extended HVAC performance test running state";
CM_ SG_ 579 VCRIGHT_hvacFrontRightSeatHeatSt "Right body controller: hvac front right seat heat status";
CM_ SG_ 579 VCRIGHT_hvacSeatFrontLeftTempTar "Front left seat heating target temperature";
CM_ SG_ 579 VCRIGHT_hvacManualToAutoNotify "Right body controller: hvac manual to auto notify";
CM_ SG_ 579 VCRIGHT_hvacRequestsFullAuto "Request that the UI go to full auto HVAC mode";
CM_ SG_ 579 VCRIGHT_passengerPresentHvacCycl "Right body controller: passenger present hvac cycle";
CM_ SG_ 579 VCRIGHT_hvacRequestsAutoIntake "Request that the UI go to auto intake HVAC mode";
CM_ SG_ 579 VCRIGHT_steeringWheelHeatStatus "Right body controller: steering wheel heat status";
CM_ SG_ 579 VCRIGHT_autoDefogStatus "Indicates defog status of auto HVAC, used for providing messaging to the user";
CM_ SG_ 579 VCRIGHT_solarElevation "Right body controller: solar elevation; raw 256 = signal not available (SNA)";
CM_ SG_ 579 VCRIGHT_minsToSunrise "Right body controller: mins to sunrise; raw 255 = signal not available (SNA)";
CM_ SG_ 579 VCRIGHT_minsToSunset "Right body controller: mins to sunset; raw 255 = signal not available (SNA)";
CM_ SG_ 579 VCRIGHT_hvacLimitedReasonRight "Right body controller: hvac limited reason right";
CM_ SG_ 579 VCRIGHT_hvacLimitedReasonLeft "Right body controller: hvac limited reason left";
CM_ SG_ 579 VCRIGHT_hvacOverheatProtActive "Status of cabin overheat protection";
CM_ SG_ 579 VCRIGHT_autoSwingAvailable "Right body controller: auto swing available";
CM_ SG_ 579 VCRIGHT_tempDuctLeftUpper "Right body controller: temp duct left upper; raw 255 = signal not available (SNA)";
CM_ SG_ 579 VCRIGHT_hvacFrontLeftSeatHeatSta "Right body controller: hvac front left seat heat status";
CM_ SG_ 579 VCRIGHT_hvacQdotLeft "Right body controller: hvac qdot left";
CM_ SG_ 579 VCRIGHT_hvacQdotRight "Right body controller: hvac qdot right";
CM_ SG_ 579 VCRIGHT_tempDuctLeftLower "Right body controller: temp duct left lower; raw 255 = signal not available (SNA)";
CM_ SG_ 579 VCRIGHT_tempDuctRightLower "Right body controller: temp duct right lower; raw 255 = signal not available (SNA)";
CM_ SG_ 579 VCRIGHT_foggingControllerResetRe "Right body controller: fogging controller reset reason";
CM_ SG_ 579 VCRIGHT_modeledCabinPressure "Right body controller: modeled cabin pressure";
CM_ SG_ 579 VCRIGHT_blowerTorqueIndex "Right body controller: blower torque index";
CM_ SG_ 579 VCRIGHT_autoSwingLeftPosX "Right body controller: auto swing left pos x";
CM_ SG_ 579 VCRIGHT_autoSwingRightPositionX "Right body controller: auto swing right position x";
CM_ BO_ 1675 "Right body controller message: hvac status2";
CM_ SG_ 1675 VCRIGHT_hvacSeat1RLCushionFanTrg "Right body controller: hvac seat1 RL cushion fan trgt";
CM_ SG_ 1675 VCRIGHT_hvacSeat1RLBackrestFanTr "Right body controller: hvac seat1 RL backrest fan trgt";
CM_ SG_ 1675 VCRIGHT_hvacSeat1RRCushionFanTrg "Right body controller: hvac seat1 RR cushion fan trgt";
CM_ SG_ 1675 VCRIGHT_hvacSeat1RRBackrestFanTr "Right body controller: hvac seat1 RR backrest fan trgt";
CM_ SG_ 1675 VCRIGHT_hvac2RActuatorsEnable "Right body controller: hvac2 r actuators enable";
CM_ SG_ 1675 VCRIGHT_hvac2RLeftLateralTarget "Right body controller: hvac2 r left lateral target";
CM_ SG_ 1675 VCRIGHT_hvac2RLeftVerticalTarget "Right body controller: hvac2 r left vertical target";
CM_ SG_ 1675 VCRIGHT_hvac2RRightLateralTarget "Right body controller: hvac2 r right lateral target";
CM_ SG_ 1675 VCRIGHT_hvac2RRightVerticalTarge "Right body controller: hvac2 r right vertical target";
CM_ BO_ 774 "Right body controller message: info";
CM_ SG_ 774 VCRIGHT_infoIndex "Right body controller: info index";
CM_ SG_ 774 VCRIGHT_infoBuildType "Right body controller: info build type";
CM_ SG_ 774 VCRIGHT_infoBuildConfigId "Right body controller: info build config id";
CM_ SG_ 774 VCRIGHT_infoHardwareId "Right body controller: info hardware id";
CM_ SG_ 774 VCRIGHT_infoComponentId "Right body controller: info component id";
CM_ SG_ 774 VCRIGHT_infoPcbaId "Right body controller: info pcba id";
CM_ SG_ 774 VCRIGHT_infoAssemblyId "Right body controller: info assembly id; raw 255 = signal not available (SNA)";
CM_ SG_ 774 VCRIGHT_infoUsageId "Right body controller: info usage id";
CM_ SG_ 774 VCRIGHT_infoSubUsageId "Right body controller: info sub usage id";
CM_ SG_ 774 VCRIGHT_infoAppCrc "Right body controller: info app crc";
CM_ SG_ 774 VCRIGHT_infoLUMBARRAppCRC "Right body controller: info LUMBARR app CRC";
CM_ SG_ 774 VCRIGHT_infoAppGitHash "Right body controller: info app git hash";
CM_ SG_ 774 VCRIGHT_infoBootGitHash "Right body controller: info boot git hash";
CM_ SG_ 774 VCRIGHT_infoPlatformType "Right body controller: info platform type";
CM_ SG_ 774 VCRIGHT_infoBootUdsProtoVersion "Right body controller: info boot uds proto version";
CM_ SG_ 774 VCRIGHT_infoBootCrc "Right body controller: info boot crc";
BA_DEF_ BO_ "GenMsgCycleTime" INT 0 3600000;
BA_DEF_ BO_ "GenMsgSendType" ENUM "Cyclic","NotUsed","NotUsed","NotUsed","NotUsed","NotUsed","NotUsed","IfActive","NoMsgSendType","NotUsed";
BA_DEF_ BO_ "VFrameFormat" ENUM "StandardCAN","ExtendedCAN","reserved","J1939PG","reserved","reserved","reserved","reserved","reserved","reserved","reserved","reserved","reserved","reserved","StandardCAN_FD","ExtendedCAN_FD";
BA_DEF_ BO_ "CANFD_BRS" ENUM "0","1";
BA_DEF_ SG_ "GenSigSNA" STRING;
BA_DEF_ SG_ "SystemSignalLongSymbol" STRING;
BA_DEF_ SG_ "Confidence" ENUM "validated","plausible","layout-only","contradicted";
BA_DEF_DEF_ "GenMsgCycleTime" 0;
BA_DEF_DEF_ "GenMsgSendType" "NoMsgSendType";
BA_DEF_DEF_ "VFrameFormat" "StandardCAN";
BA_DEF_DEF_ "CANFD_BRS" "1";
BA_DEF_DEF_ "GenSigSNA" "";
BA_DEF_DEF_ "SystemSignalLongSymbol" "";
BA_DEF_DEF_ "Confidence" "layout-only";
BA_ "GenMsgCycleTime" BO_ 960 100;
BA_ "GenMsgSendType" BO_ 960 0;
BA_ "GenMsgCycleTime" BO_ 1795 10;
BA_ "GenMsgSendType" BO_ 1795 0;
BA_ "GenMsgCycleTime" BO_ 259 100;
BA_ "GenMsgSendType" BO_ 259 0;
BA_ "GenMsgCycleTime" BO_ 2010 100;
BA_ "GenMsgSendType" BO_ 2010 0;
BA_ "GenMsgCycleTime" BO_ 915 100;
BA_ "GenMsgSendType" BO_ 915 0;
BA_ "GenMsgCycleTime" BO_ 1123 100;
BA_ "GenMsgSendType" BO_ 1123 0;
BA_ "GenMsgCycleTime" BO_ 524 100;
BA_ "GenMsgSendType" BO_ 524 0;
BA_ "GenMsgCycleTime" BO_ 579 20;
BA_ "GenMsgSendType" BO_ 579 0;
BA_ "GenMsgCycleTime" BO_ 1675 100;
BA_ "GenMsgSendType" BO_ 1675 0;
BA_ "GenMsgCycleTime" BO_ 774 1000;
BA_ "GenMsgSendType" BO_ 774 0;
BA_ "Confidence" SG_ 2011 VCRIGHT_a518_seatState 1;
BA_ "GenSigSNA" SG_ 2011 VCRIGHT_a518_seatState "15";
BA_ "Confidence" SG_ 2011 VCRIGHT_a520_epbConfig 1;
BA_ "Confidence" SG_ 2011 VCRIGHT_a520_gtwEpbConfig 1;
BA_ "Confidence" SG_ 2011 VCRIGHT_a525_GTW_twelveVBatteryT 1;
BA_ "SystemSignalLongSymbol" SG_ 2011 VCRIGHT_a525_GTW_twelveVBatteryT "VCRIGHT_a525_GTW_twelveVBatteryType";
BA_ "Confidence" SG_ 2011 VCRIGHT_a525_newLVBatteryType 1;
BA_ "Confidence" SG_ 2011 VCRIGHT_a525_initialLVBatteryTyp 1;
BA_ "SystemSignalLongSymbol" SG_ 2011 VCRIGHT_a525_initialLVBatteryTyp "VCRIGHT_a525_initialLVBatteryType";
BA_ "SystemSignalLongSymbol" SG_ 2011 VCRIGHT_a538_cabinTempSensorFaul "VCRIGHT_a538_cabinTempSensorFault";
BA_ "SystemSignalLongSymbol" SG_ 2011 VCRIGHT_a538_cabinModelNotInitia "VCRIGHT_a538_cabinModelNotInitialized";
BA_ "SystemSignalLongSymbol" SG_ 2011 VCRIGHT_a538_blowerFaultOrStoppe "VCRIGHT_a538_blowerFaultOrStopped";
BA_ "SystemSignalLongSymbol" SG_ 2011 VCRIGHT_a538_compressorFaultOrSt "VCRIGHT_a538_compressorFaultOrStandby";
BA_ "SystemSignalLongSymbol" SG_ 2011 VCRIGHT_a538_heatPumpModeNotAtta "VCRIGHT_a538_heatPumpModeNotAttainable";
BA_ "SystemSignalLongSymbol" SG_ 2011 VCRIGHT_a539_hvacSystemNotNomina "VCRIGHT_a539_hvacSystemNotNominal";
BA_ "SystemSignalLongSymbol" SG_ 2011 VCRIGHT_a539_modeledCabinTempOut "VCRIGHT_a539_modeledCabinTempOutOfRange";
BA_ "SystemSignalLongSymbol" SG_ 2011 VCRIGHT_a539_modeledCabinTempExc "VCRIGHT_a539_modeledCabinTempExceedingSetTemp";
BA_ "SystemSignalLongSymbol" SG_ 2011 VCRIGHT_a539_cabinTempSensorFaul "VCRIGHT_a539_cabinTempSensorFault";
BA_ "SystemSignalLongSymbol" SG_ 2011 VCRIGHT_a539_cabinTempSensorOutO "VCRIGHT_a539_cabinTempSensorOutOfRange";
BA_ "SystemSignalLongSymbol" SG_ 2011 VCRIGHT_a539_modeledCabinTempDev "VCRIGHT_a539_modeledCabinTempDeviation";
BA_ "Confidence" SG_ 2011 VCRIGHT_a545_GTW_twelveVBatteryT 1;
BA_ "SystemSignalLongSymbol" SG_ 2011 VCRIGHT_a545_GTW_twelveVBatteryT "VCRIGHT_a545_GTW_twelveVBatteryType";
BA_ "Confidence" SG_ 2011 VCRIGHT_a545_newLVBatteryType 1;
BA_ "SystemSignalLongSymbol" SG_ 2011 VCRIGHT_a551_restrictDoorRelease "VCRIGHT_a551_restrictDoorReleaseSignalFront";
BA_ "SystemSignalLongSymbol" SG_ 2011 VCRIGHT_a551_interiorReleaseReqC "VCRIGHT_a551_interiorReleaseReqCountFront";
BA_ "SystemSignalLongSymbol" SG_ 2011 VCRIGHT_a551_lastRequestSourceFr "VCRIGHT_a551_lastRequestSourceFront";
BA_ "SystemSignalLongSymbol" SG_ 2011 VCRIGHT_a551_restrictDoorRe_0001 "VCRIGHT_a551_restrictDoorReleaseSignalRear";
BA_ "SystemSignalLongSymbol" SG_ 2011 VCRIGHT_a551_interiorReleas_0001 "VCRIGHT_a551_interiorReleaseReqCountRear";
BA_ "SystemSignalLongSymbol" SG_ 2011 VCRIGHT_a551_lastRequestSourceRe "VCRIGHT_a551_lastRequestSourceRear";
BA_ "SystemSignalLongSymbol" SG_ 2011 VCRIGHT_a560_isRearwardEndstopUn "VCRIGHT_a560_isRearwardEndstopUncalibrated";
BA_ "SystemSignalLongSymbol" SG_ 2011 VCRIGHT_a560_isAbsPosSensorUncal "VCRIGHT_a560_isAbsPosSensorUncalibrated";
BA_ "Confidence" SG_ 2011 VCRIGHT_a560_seatState 1;
BA_ "GenSigSNA" SG_ 2011 VCRIGHT_a560_seatState "15";
BA_ "Confidence" SG_ 2011 VCRIGHT_a560_motorType 1;
BA_ "Confidence" SG_ 2011 VCRIGHT_a560_absPosSensState 1;
BA_ "Confidence" SG_ 2011 VCRIGHT_a563_angle 1;
BA_ "Confidence" SG_ 2011 VCRIGHT_a563_seatStatePrev 1;
BA_ "GenSigSNA" SG_ 2011 VCRIGHT_a563_seatStatePrev "15";
BA_ "Confidence" SG_ 2011 VCRIGHT_a563_obstacleDetectReaso 1;
BA_ "SystemSignalLongSymbol" SG_ 2011 VCRIGHT_a563_obstacleDetectReaso "VCRIGHT_a563_obstacleDetectReason";
BA_ "SystemSignalLongSymbol" SG_ 2011 VCRIGHT_a563_accelLookbackTripDe "VCRIGHT_a563_accelLookbackTripDepth";
BA_ "Confidence" SG_ 2011 VCRIGHT_a563_duty 1;
BA_ "Confidence" SG_ 2011 VCRIGHT_a563_currentAbsFilt 1;
BA_ "Confidence" SG_ 2011 VCRIGHT_a563_motorType 1;
BA_ "SystemSignalLongSymbol" SG_ 2011 VCRIGHT_a563_absolutePosSensorFo "VCRIGHT_a563_absolutePosSensorForward";
BA_ "Confidence" SG_ 2011 VCRIGHT_a563_cabinTemp 1;
BA_ "SystemSignalLongSymbol" SG_ 2011 VCRIGHT_a567_isRearwardEndstopUn "VCRIGHT_a567_isRearwardEndstopUncalibrated";
BA_ "SystemSignalLongSymbol" SG_ 2011 VCRIGHT_a567_isAbsPosSensorUncal "VCRIGHT_a567_isAbsPosSensorUncalibrated";
BA_ "Confidence" SG_ 2011 VCRIGHT_a568_seatState 1;
BA_ "GenSigSNA" SG_ 2011 VCRIGHT_a568_seatState "15";
BA_ "Confidence" SG_ 2011 VCRIGHT_a570_seatHeatCurrent 1;
BA_ "Confidence" SG_ 2011 VCRIGHT_a570_seatHeatTmp 1;
BA_ "Confidence" SG_ 2011 VCRIGHT_a571_seatHeatCurrent 1;
BA_ "Confidence" SG_ 2011 VCRIGHT_a571_seatHeatTmp 1;
BA_ "Confidence" SG_ 2011 VCRIGHT_a572_seatHeatCurrent 1;
BA_ "Confidence" SG_ 2011 VCRIGHT_a572_seatHeatTmp 1;
BA_ "Confidence" SG_ 2011 VCRIGHT_a573_seatHeatCurrent 1;
BA_ "Confidence" SG_ 2011 VCRIGHT_a573_seatHeatTmp 1;
BA_ "Confidence" SG_ 2011 VCRIGHT_a579_liftgateFollowerSto 1;
BA_ "SystemSignalLongSymbol" SG_ 2011 VCRIGHT_a579_liftgateFollowerSto "VCRIGHT_a579_liftgateFollowerStoppingCondition";
BA_ "Confidence" SG_ 2011 VCRIGHT_a579_liftgateFollowerPos 1;
BA_ "SystemSignalLongSymbol" SG_ 2011 VCRIGHT_a579_liftgateFollowerPos "VCRIGHT_a579_liftgateFollowerPosition";
BA_ "Confidence" SG_ 2011 VCRIGHT_a579_liftgateFollowerLat 1;
BA_ "GenSigSNA" SG_ 2011 VCRIGHT_a579_liftgateFollowerLat "0";
BA_ "SystemSignalLongSymbol" SG_ 2011 VCRIGHT_a579_liftgateFollowerLat "VCRIGHT_a579_liftgateFollowerLatchStatus";
BA_ "Confidence" SG_ 2011 VCRIGHT_a585_ambientTemp 1;
BA_ "GenSigSNA" SG_ 2011 VCRIGHT_a585_ambientTemp "0";
BA_ "Confidence" SG_ 2011 VCRIGHT_a586_ambientTemp 1;
BA_ "GenSigSNA" SG_ 2011 VCRIGHT_a586_ambientTemp "0";
BA_ "Confidence" SG_ 2011 VCRIGHT_a590_seatMotorCurrent 1;
BA_ "Confidence" SG_ 2011 VCRIGHT_a590_seatMotorState 1;
BA_ "Confidence" SG_ 2011 VCRIGHT_a590_seatSwitchBack 1;
BA_ "GenSigSNA" SG_ 2011 VCRIGHT_a590_seatSwitchBack "0";
BA_ "Confidence" SG_ 2011 VCRIGHT_a590_seatSwitchForward 1;
BA_ "GenSigSNA" SG_ 2011 VCRIGHT_a590_seatSwitchForward "0";
BA_ "Confidence" SG_ 2011 VCRIGHT_a591_seatMotorCurrent 1;
BA_ "Confidence" SG_ 2011 VCRIGHT_a591_seatMotorPosReal 1;
BA_ "Confidence" SG_ 2011 VCRIGHT_a591_seatMotorState 1;
BA_ "Confidence" SG_ 2011 VCRIGHT_a591_seatSwitchBack 1;
BA_ "GenSigSNA" SG_ 2011 VCRIGHT_a591_seatSwitchBack "0";
BA_ "Confidence" SG_ 2011 VCRIGHT_a591_seatSwitchForward 1;
BA_ "GenSigSNA" SG_ 2011 VCRIGHT_a591_seatSwitchForward "0";
BA_ "Confidence" SG_ 2011 VCRIGHT_a592_seatMotorCurrent 1;
BA_ "Confidence" SG_ 2011 VCRIGHT_a592_seatMotorPosReal 1;
BA_ "Confidence" SG_ 2011 VCRIGHT_a592_seatMotorState 1;
BA_ "Confidence" SG_ 2011 VCRIGHT_a592_seatSwitchBack 1;
BA_ "GenSigSNA" SG_ 2011 VCRIGHT_a592_seatSwitchBack "0";
BA_ "Confidence" SG_ 2011 VCRIGHT_a592_seatSwitchForward 1;
BA_ "GenSigSNA" SG_ 2011 VCRIGHT_a592_seatSwitchForward "0";
BA_ "Confidence" SG_ 2011 VCRIGHT_a593_seatMotorCurrent 1;
BA_ "Confidence" SG_ 2011 VCRIGHT_a593_seatMotorPosReal 1;
BA_ "Confidence" SG_ 2011 VCRIGHT_a593_seatMotorState 1;
BA_ "Confidence" SG_ 2011 VCRIGHT_a593_seatSwitchBack 1;
BA_ "GenSigSNA" SG_ 2011 VCRIGHT_a593_seatSwitchBack "0";
BA_ "Confidence" SG_ 2011 VCRIGHT_a593_seatSwitchForward 1;
BA_ "GenSigSNA" SG_ 2011 VCRIGHT_a593_seatSwitchForward "0";
BA_ "Confidence" SG_ 2011 VCRIGHT_a594_seatMotorCurrent 1;
BA_ "Confidence" SG_ 2011 VCRIGHT_a594_seatMotorDCurrent 1;
BA_ "Confidence" SG_ 2011 VCRIGHT_a594_seatMotorPosReal 1;
BA_ "Confidence" SG_ 2011 VCRIGHT_a594_seatMotorState 1;
BA_ "Confidence" SG_ 2011 VCRIGHT_a595_seatMotorCurrent 1;
BA_ "Confidence" SG_ 2011 VCRIGHT_a595_seatMotorDCurrent 1;
BA_ "Confidence" SG_ 2011 VCRIGHT_a595_seatMotorPosReal 1;
BA_ "Confidence" SG_ 2011 VCRIGHT_a595_seatMotorState 1;
BA_ "Confidence" SG_ 2011 VCRIGHT_a596_frontDoorLatchAjarS 1;
BA_ "SystemSignalLongSymbol" SG_ 2011 VCRIGHT_a596_frontDoorLatchAjarS "VCRIGHT_a596_frontDoorLatchAjarSwitchVoltage";
BA_ "Confidence" SG_ 2011 VCRIGHT_a597_rearDoorLatchAjarSw 1;
BA_ "SystemSignalLongSymbol" SG_ 2011 VCRIGHT_a597_rearDoorLatchAjarSw "VCRIGHT_a597_rearDoorLatchAjarSwitchVoltage";
BA_ "Confidence" SG_ 2011 VCRIGHT_a599_GTW_twelveVBatteryT 1;
BA_ "SystemSignalLongSymbol" SG_ 2011 VCRIGHT_a599_GTW_twelveVBatteryT "VCRIGHT_a599_GTW_twelveVBatteryType";
BA_ "Confidence" SG_ 2011 VCRIGHT_a599_newLVBatteryType 1;
BA_ "Confidence" SG_ 2011 VCRIGHT_a599_initialLVBatteryTyp 1;
BA_ "SystemSignalLongSymbol" SG_ 2011 VCRIGHT_a599_initialLVBatteryTyp "VCRIGHT_a599_initialLVBatteryType";
BA_ "SystemSignalLongSymbol" SG_ 2011 VCRIGHT_a605_excessiveMacFailure "VCRIGHT_a605_excessiveMacFailures";
BA_ "Confidence" SG_ 960 VCRIGHT_matrixIndex 1;
BA_ "SystemSignalLongSymbol" SG_ 960 VCRIGHT_a065_emiosIsrRateLimited "VCRIGHT_a065_emiosIsrRateLimitedDbg";
BA_ "SystemSignalLongSymbol" SG_ 960 VCRIGHT_a066_emiosIsrShortPeriod "VCRIGHT_a066_emiosIsrShortPeriodDetectedDbg";
BA_ "SystemSignalLongSymbol" SG_ 960 VCRIGHT_a123_VC_SECONDARY_LIGHTI "VCRIGHT_a123_VC_SECONDARY_LIGHTING_LEADER_MIA";
BA_ "SystemSignalLongSymbol" SG_ 960 VCRIGHT_a127_hvacActOvercurrentD "VCRIGHT_a127_hvacActOvercurrentDBG";
BA_ "SystemSignalLongSymbol" SG_ 960 VCRIGHT_a143_mirrorManuallyFolde "VCRIGHT_a143_mirrorManuallyFolded";
BA_ "SystemSignalLongSymbol" SG_ 960 VCRIGHT_a175_windowSealDefectFro "VCRIGHT_a175_windowSealDefectFront";
BA_ "SystemSignalLongSymbol" SG_ 960 VCRIGHT_a176_windowSealDefectRea "VCRIGHT_a176_windowSealDefectRear";
BA_ "SystemSignalLongSymbol" SG_ 960 VCRIGHT_a178_trunkSwitchVCBATTMI "VCRIGHT_a178_trunkSwitchVCBATTMIA";
BA_ "SystemSignalLongSymbol" SG_ 960 VCRIGHT_a179_trunkSwitchVCFRONTM "VCRIGHT_a179_trunkSwitchVCFRONTMIA";
BA_ "SystemSignalLongSymbol" SG_ 960 VCRIGHT_a180_frontDoorLatchRehom "VCRIGHT_a180_frontDoorLatchRehome";
BA_ "SystemSignalLongSymbol" SG_ 960 VCRIGHT_a183_doorStateFactoryTes "VCRIGHT_a183_doorStateFactoryTest";
BA_ "SystemSignalLongSymbol" SG_ 960 VCRIGHT_a215_currentDesyncWarnin "VCRIGHT_a215_currentDesyncWarning";
BA_ "SystemSignalLongSymbol" SG_ 960 VCRIGHT_a220_reverseLightFaultUs "VCRIGHT_a220_reverseLightFaultUser";
BA_ "SystemSignalLongSymbol" SG_ 960 VCRIGHT_a221_undervoltageLoadshe "VCRIGHT_a221_undervoltageLoadshedTriggered";
BA_ "SystemSignalLongSymbol" SG_ 960 VCRIGHT_a222_rearFasciaFogLightF "VCRIGHT_a222_rearFasciaFogLightFaultUser";
BA_ "SystemSignalLongSymbol" SG_ 960 VCRIGHT_a261_emergencyLatchRelRe "VCRIGHT_a261_emergencyLatchRelRear";
BA_ "SystemSignalLongSymbol" SG_ 960 VCRIGHT_a267_seatTrackHCEncStlDb "VCRIGHT_a267_seatTrackHCEncStlDbg";
BA_ "SystemSignalLongSymbol" SG_ 960 VCRIGHT_a277_BLERightUnderVoltag "VCRIGHT_a277_BLERightUnderVoltage";
BA_ "SystemSignalLongSymbol" SG_ 960 VCRIGHT_a278_hvacPtcHeatingUnava "VCRIGHT_a278_hvacPtcHeatingUnavailable";
BA_ "SystemSignalLongSymbol" SG_ 960 VCRIGHT_a284_gloveboxUnderCurren "VCRIGHT_a284_gloveboxUnderCurrentDetected";
BA_ "SystemSignalLongSymbol" SG_ 960 VCRIGHT_a285_gloveboxOverCurrent "VCRIGHT_a285_gloveboxOverCurrentDetected";
BA_ "SystemSignalLongSymbol" SG_ 960 VCRIGHT_a290_occupancyFaultedFro "VCRIGHT_a290_occupancyFaultedFront";
BA_ "SystemSignalLongSymbol" SG_ 960 VCRIGHT_a294_occupancyFaultedRea "VCRIGHT_a294_occupancyFaultedRearR";
BA_ "SystemSignalLongSymbol" SG_ 960 VCRIGHT_a295_occupancyFaulted3Ro "VCRIGHT_a295_occupancyFaulted3RowL";
BA_ "SystemSignalLongSymbol" SG_ 960 VCRIGHT_a296_occupancyFaulted3Ro "VCRIGHT_a296_occupancyFaulted3RowR";
BA_ "SystemSignalLongSymbol" SG_ 960 VCRIGHT_a301_airwaveRightVertica "VCRIGHT_a301_airwaveRightVerticalWarning";
BA_ "SystemSignalLongSymbol" SG_ 960 VCRIGHT_a302_airwaveRightVertica "VCRIGHT_a302_airwaveRightVerticalUnavailable";
BA_ "SystemSignalLongSymbol" SG_ 960 VCRIGHT_a304_frontIntHandleUnexp "VCRIGHT_a304_frontIntHandleUnexpectedVoltage";
BA_ "SystemSignalLongSymbol" SG_ 960 VCRIGHT_a305_rearIntHandleUnexpe "VCRIGHT_a305_rearIntHandleUnexpectedVoltage";
BA_ "SystemSignalLongSymbol" SG_ 960 VCRIGHT_a308_airwaveRightLateral "VCRIGHT_a308_airwaveRightLateralUnavailable";
BA_ "SystemSignalLongSymbol" SG_ 960 VCRIGHT_a311_rightBrakeLightFaul "VCRIGHT_a311_rightBrakeLightFault";
BA_ "SystemSignalLongSymbol" SG_ 960 VCRIGHT_a313_rightFootwellLightF "VCRIGHT_a313_rightFootwellLightFault";
BA_ "SystemSignalLongSymbol" SG_ 960 VCRIGHT_a314_rightMapPocketLight "VCRIGHT_a314_rightMapPocketLightFault";
BA_ "SystemSignalLongSymbol" SG_ 960 VCRIGHT_a315_rightInteriorTrunkL "VCRIGHT_a315_rightInteriorTrunkLightFault";
BA_ "SystemSignalLongSymbol" SG_ 960 VCRIGHT_a316_mirrorPrematureFold "VCRIGHT_a316_mirrorPrematureFoldStall";
BA_ "SystemSignalLongSymbol" SG_ 960 VCRIGHT_a318_leftExteriorTrunkLi "VCRIGHT_a318_leftExteriorTrunkLightFault";
BA_ "SystemSignalLongSymbol" SG_ 960 VCRIGHT_a319_rightExteriorTrunkL "VCRIGHT_a319_rightExteriorTrunkLightFault";
BA_ "SystemSignalLongSymbol" SG_ 960 VCRIGHT_a320_windowReportCracked "VCRIGHT_a320_windowReportCrackedAtTrimClear";
BA_ "SystemSignalLongSymbol" SG_ 960 VCRIGHT_a321_windowRezeroedDebug "VCRIGHT_a321_windowRezeroedDebugF";
BA_ "SystemSignalLongSymbol" SG_ 960 VCRIGHT_a322_windowRezeroedDebug "VCRIGHT_a322_windowRezeroedDebugR";
BA_ "SystemSignalLongSymbol" SG_ 960 VCRIGHT_a325_airwaveLeftVertical "VCRIGHT_a325_airwaveLeftVerticalUnavailable";
BA_ "SystemSignalLongSymbol" SG_ 960 VCRIGHT_a326_airwaveLeftLateralU "VCRIGHT_a326_airwaveLeftLateralUnavailable";
BA_ "SystemSignalLongSymbol" SG_ 960 VCRIGHT_a327_airwaveLeftLateralW "VCRIGHT_a327_airwaveLeftLateralWarning";
BA_ "SystemSignalLongSymbol" SG_ 960 VCRIGHT_a328_airwaveLeftVertical "VCRIGHT_a328_airwaveLeftVerticalWarning";
BA_ "SystemSignalLongSymbol" SG_ 960 VCRIGHT_a329_airwaveRightLateral "VCRIGHT_a329_airwaveRightLateralWarning";
BA_ "SystemSignalLongSymbol" SG_ 960 VCRIGHT_a336_windowDropRevTherma "VCRIGHT_a336_windowDropRevThermalF";
BA_ "SystemSignalLongSymbol" SG_ 960 VCRIGHT_a337_windowDropRevTherma "VCRIGHT_a337_windowDropRevThermalR";
BA_ "SystemSignalLongSymbol" SG_ 960 VCRIGHT_a343_rearDefrostUndercur "VCRIGHT_a343_rearDefrostUndercurrent";
BA_ "SystemSignalLongSymbol" SG_ 960 VCRIGHT_a344_rearDefrostOvercurr "VCRIGHT_a344_rearDefrostOvercurrent";
BA_ "SystemSignalLongSymbol" SG_ 960 VCRIGHT_a345_HVACPTCHeaterPwrEFu "VCRIGHT_a345_HVACPTCHeaterPwrEFuseFault";
BA_ "SystemSignalLongSymbol" SG_ 960 VCRIGHT_a346_cabinRadarEFuseFaul "VCRIGHT_a346_cabinRadarEFuseFault";
BA_ "SystemSignalLongSymbol" SG_ 960 VCRIGHT_a347_nonContMonitorClear "VCRIGHT_a347_nonContMonitorClearedDBG";
BA_ "SystemSignalLongSymbol" SG_ 960 VCRIGHT_a352_audioCurrentSpikeDa "VCRIGHT_a352_audioCurrentSpikeData";
BA_ "SystemSignalLongSymbol" SG_ 960 VCRIGHT_a359_hvacUpperModeWarnin "VCRIGHT_a359_hvacUpperModeWarning";
BA_ "SystemSignalLongSymbol" SG_ 960 VCRIGHT_a360_detectedStationaryW "VCRIGHT_a360_detectedStationaryWhileMoving";
BA_ "SystemSignalLongSymbol" SG_ 960 VCRIGHT_a361_stationaryThreshold "VCRIGHT_a361_stationaryThresholdsIncorrect";
BA_ "SystemSignalLongSymbol" SG_ 960 VCRIGHT_a362_movingThresholdsInc "VCRIGHT_a362_movingThresholdsIncorrect";
BA_ "SystemSignalLongSymbol" SG_ 960 VCRIGHT_a363_hvacLowerModeWarnin "VCRIGHT_a363_hvacLowerModeWarning";
BA_ "SystemSignalLongSymbol" SG_ 960 VCRIGHT_a365_pitchUnlatchDisable "VCRIGHT_a365_pitchUnlatchDisabled";
BA_ "SystemSignalLongSymbol" SG_ 960 VCRIGHT_a368_ductLeftLowerTempSn "VCRIGHT_a368_ductLeftLowerTempSns";
BA_ "SystemSignalLongSymbol" SG_ 960 VCRIGHT_a369_ductRightLowerTempS "VCRIGHT_a369_ductRightLowerTempSns";
BA_ "SystemSignalLongSymbol" SG_ 960 VCRIGHT_a370_seat2RowPitchUnlatc "VCRIGHT_a370_seat2RowPitchUnlatched";
BA_ "SystemSignalLongSymbol" SG_ 960 VCRIGHT_a371_seat2RowTrackUnlatc "VCRIGHT_a371_seat2RowTrackUnlatched";
BA_ "SystemSignalLongSymbol" SG_ 960 VCRIGHT_a372_seat2RowBackrestUnl "VCRIGHT_a372_seat2RowBackrestUnlatched";
BA_ "SystemSignalLongSymbol" SG_ 960 VCRIGHT_a373_windowSwOpenReqInDo "VCRIGHT_a373_windowSwOpenReqInDogMode";
BA_ "SystemSignalLongSymbol" SG_ 960 VCRIGHT_a375_windowPinchOverride "VCRIGHT_a375_windowPinchOverrideNudge";
BA_ "SystemSignalLongSymbol" SG_ 960 VCRIGHT_a376_seat2RowBridgeCurre "VCRIGHT_a376_seat2RowBridgeCurrentExceeded";
BA_ "SystemSignalLongSymbol" SG_ 960 VCRIGHT_a378_ductLeftUpperTempSn "VCRIGHT_a378_ductLeftUpperTempSns";
BA_ "SystemSignalLongSymbol" SG_ 960 VCRIGHT_a379_ductRightUpperTempS "VCRIGHT_a379_ductRightUpperTempSns";
BA_ "SystemSignalLongSymbol" SG_ 960 VCRIGHT_a382_leftLiftgateTailLig "VCRIGHT_a382_leftLiftgateTailLightFault";
BA_ "SystemSignalLongSymbol" SG_ 960 VCRIGHT_a385_glareShieldHeaterUn "VCRIGHT_a385_glareShieldHeaterUnavailable";
BA_ "SystemSignalLongSymbol" SG_ 960 VCRIGHT_a407_aptivOCSInterfaceEr "VCRIGHT_a407_aptivOCSInterfaceError";
BA_ "SystemSignalLongSymbol" SG_ 960 VCRIGHT_a409_aptivOCSDeviceError "VCRIGHT_a409_aptivOCSDeviceErrorDebug";
BA_ "SystemSignalLongSymbol" SG_ 960 VCRIGHT_a411_undervoltageSelfTes "VCRIGHT_a411_undervoltageSelfTestFailure";
BA_ "SystemSignalLongSymbol" SG_ 960 VCRIGHT_a412_rightBrakeTailLight "VCRIGHT_a412_rightBrakeTailLightFault";
BA_ "SystemSignalLongSymbol" SG_ 960 VCRIGHT_a413_centerHighMountStop "VCRIGHT_a413_centerHighMountStopLightFault";
BA_ "SystemSignalLongSymbol" SG_ 960 VCRIGHT_a414_rearFasciaReverseLi "VCRIGHT_a414_rearFasciaReverseLightFault";
BA_ "SystemSignalLongSymbol" SG_ 960 VCRIGHT_a415_rearFasciaFogLightF "VCRIGHT_a415_rearFasciaFogLightFault";
BA_ "SystemSignalLongSymbol" SG_ 960 VCRIGHT_a416_rearFasciaTailLight "VCRIGHT_a416_rearFasciaTailLightFault";
BA_ "SystemSignalLongSymbol" SG_ 960 VCRIGHT_a417_rearFasciaLeftTurnL "VCRIGHT_a417_rearFasciaLeftTurnLightFault";
BA_ "SystemSignalLongSymbol" SG_ 960 VCRIGHT_a418_rearFasciaRightTurn "VCRIGHT_a418_rearFasciaRightTurnLightFault";
BA_ "SystemSignalLongSymbol" SG_ 960 VCRIGHT_a419_tailFasciaLeftLight "VCRIGHT_a419_tailFasciaLeftLightFault";
BA_ "SystemSignalLongSymbol" SG_ 960 VCRIGHT_a420_tailFasciaRightLigh "VCRIGHT_a420_tailFasciaRightLightFault";
BA_ "SystemSignalLongSymbol" SG_ 960 VCRIGHT_a422_undervoltageSelfTes "VCRIGHT_a422_undervoltageSelfTestStuckOff";
BA_ "SystemSignalLongSymbol" SG_ 960 VCRIGHT_a446_cabinHVACUnavailabl "VCRIGHT_a446_cabinHVACUnavailableContext";
BA_ "SystemSignalLongSymbol" SG_ 960 VCRIGHT_a450_ptcForcedOutOfSeqRo "VCRIGHT_a450_ptcForcedOutOfSeqRod";
BA_ "SystemSignalLongSymbol" SG_ 960 VCRIGHT_a451_ptcSeqRodOutOfRetri "VCRIGHT_a451_ptcSeqRodOutOfRetries";
BA_ "SystemSignalLongSymbol" SG_ 960 VCRIGHT_a454_ptcHeaterBadRodDete "VCRIGHT_a454_ptcHeaterBadRodDetected";
BA_ "SystemSignalLongSymbol" SG_ 960 VCRIGHT_a483_rightTurnLightFault "VCRIGHT_a483_rightTurnLightFaultUser";
BA_ "SystemSignalLongSymbol" SG_ 960 VCRIGHT_a484_rightBrakeLightFaul "VCRIGHT_a484_rightBrakeLightFaultUser";
BA_ "SystemSignalLongSymbol" SG_ 960 VCRIGHT_a485_leftTailLightFaultU "VCRIGHT_a485_leftTailLightFaultUser";
BA_ "SystemSignalLongSymbol" SG_ 960 VCRIGHT_a486_rightTailLightFault "VCRIGHT_a486_rightTailLightFaultUser";
BA_ "SystemSignalLongSymbol" SG_ 960 VCRIGHT_a487_centerHighMountStop "VCRIGHT_a487_centerHighMountStopLightFaultUser";
BA_ "SystemSignalLongSymbol" SG_ 960 VCRIGHT_a488_undervoltageSelfTes "VCRIGHT_a488_undervoltageSelfTestStuckOnDebug";
BA_ "SystemSignalLongSymbol" SG_ 960 VCRIGHT_a489_undervoltageSelfTes "VCRIGHT_a489_undervoltageSelfTestStuckOn";
BA_ "SystemSignalLongSymbol" SG_ 960 VCRIGHT_a490_vehicleOccupiedOnOT "VCRIGHT_a490_vehicleOccupiedOnOTAStart";
BA_ "SystemSignalLongSymbol" SG_ 960 VCRIGHT_a491_BPillarCameraHeater "VCRIGHT_a491_BPillarCameraHeaterFault";
BA_ "SystemSignalLongSymbol" SG_ 960 VCRIGHT_a492_uvSelfTestLoadUnatt "VCRIGHT_a492_uvSelfTestLoadUnattemptedOnDbg";
BA_ "SystemSignalLongSymbol" SG_ 960 VCRIGHT_a497_CANMsgMACVerificati "VCRIGHT_a497_CANMsgMACVerificationKeyNotProvisioned";
BA_ "SystemSignalLongSymbol" SG_ 960 VCRIGHT_a498_CANMsgMACVerificati "VCRIGHT_a498_CANMsgMACVerificationFailure";
BA_ "SystemSignalLongSymbol" SG_ 960 VCRIGHT_a510_3RowSeatUncalibrate "VCRIGHT_a510_3RowSeatUncalibrated";
BA_ "SystemSignalLongSymbol" SG_ 960 VCRIGHT_a511_3RowSeatPositionNon "VCRIGHT_a511_3RowSeatPositionNonsensical";
BA_ "SystemSignalLongSymbol" SG_ 960 VCRIGHT_a512_3RowSeatAbsPosOffse "VCRIGHT_a512_3RowSeatAbsPosOffsetApplied";
BA_ "SystemSignalLongSymbol" SG_ 960 VCRIGHT_a513_3RowSeatObstacleDet "VCRIGHT_a513_3RowSeatObstacleDetected";
BA_ "SystemSignalLongSymbol" SG_ 960 VCRIGHT_a515_3RowSeatAbsPosSenso "VCRIGHT_a515_3RowSeatAbsPosSensorTransitionDbg";
BA_ "SystemSignalLongSymbol" SG_ 960 VCRIGHT_a516_3RowSeatStatsFromLa "VCRIGHT_a516_3RowSeatStatsFromLastStateDbg";
BA_ "SystemSignalLongSymbol" SG_ 960 VCRIGHT_a517_3RowSeatRequestWhil "VCRIGHT_a517_3RowSeatRequestWhileUncalibrated";
BA_ "SystemSignalLongSymbol" SG_ 960 VCRIGHT_a518_3RowSeatClashAvoida "VCRIGHT_a518_3RowSeatClashAvoidanceBlocked";
BA_ "SystemSignalLongSymbol" SG_ 960 VCRIGHT_a525_LVBatterySWMisconfi "VCRIGHT_a525_LVBatterySWMisconfiguration";
BA_ "SystemSignalLongSymbol" SG_ 960 VCRIGHT_a527_continuousFeedUnexp "VCRIGHT_a527_continuousFeedUnexpectedVoltage";
BA_ "SystemSignalLongSymbol" SG_ 960 VCRIGHT_a528_unableToRunStuckOnT "VCRIGHT_a528_unableToRunStuckOnTest";
BA_ "SystemSignalLongSymbol" SG_ 960 VCRIGHT_a529_airflowFeedBackMode "VCRIGHT_a529_airflowFeedBackModelError";
BA_ "SystemSignalLongSymbol" SG_ 960 VCRIGHT_a531_airflowModelTmpComp "VCRIGHT_a531_airflowModelTmpCompDisabled";
BA_ "SystemSignalLongSymbol" SG_ 960 VCRIGHT_a532_airflowModelFeedFor "VCRIGHT_a532_airflowModelFeedForwardError";
BA_ "SystemSignalLongSymbol" SG_ 960 VCRIGHT_a537_solarCalcsNotNomina "VCRIGHT_a537_solarCalcsNotNominal";
BA_ "SystemSignalLongSymbol" SG_ 960 VCRIGHT_a538_hvacSystemNotNomina "VCRIGHT_a538_hvacSystemNotNominal";
BA_ "SystemSignalLongSymbol" SG_ 960 VCRIGHT_a540_hvacActuatorDitherD "VCRIGHT_a540_hvacActuatorDitherDebug";
BA_ "SystemSignalLongSymbol" SG_ 960 VCRIGHT_a542_steeringWheelHeatin "VCRIGHT_a542_steeringWheelHeatingInhibited";
BA_ "SystemSignalLongSymbol" SG_ 960 VCRIGHT_a545_LVBatteryTypeUnknow "VCRIGHT_a545_LVBatteryTypeUnknown";
BA_ "SystemSignalLongSymbol" SG_ 960 VCRIGHT_a546_mirrorFoldTypeChang "VCRIGHT_a546_mirrorFoldTypeChanged";
BA_ "SystemSignalLongSymbol" SG_ 960 VCRIGHT_a551_interiorDoorRequest "VCRIGHT_a551_interiorDoorRequestInhibited";
BA_ "SystemSignalLongSymbol" SG_ 960 VCRIGHT_a560_2RowSeatUncalibrate "VCRIGHT_a560_2RowSeatUncalibrated";
BA_ "SystemSignalLongSymbol" SG_ 960 VCRIGHT_a561_2RowSeatPositionNon "VCRIGHT_a561_2RowSeatPositionNonsensical";
BA_ "SystemSignalLongSymbol" SG_ 960 VCRIGHT_a562_2RowSeatAbsPosOffse "VCRIGHT_a562_2RowSeatAbsPosOffsetApplied";
BA_ "SystemSignalLongSymbol" SG_ 960 VCRIGHT_a563_2RowSeatObstacleDet "VCRIGHT_a563_2RowSeatObstacleDetected";
BA_ "SystemSignalLongSymbol" SG_ 960 VCRIGHT_a565_2RowSeatAbsPosSenso "VCRIGHT_a565_2RowSeatAbsPosSensorTransitionDbg";
BA_ "SystemSignalLongSymbol" SG_ 960 VCRIGHT_a566_2RowSeatStatsFromLa "VCRIGHT_a566_2RowSeatStatsFromLastStateDbg";
BA_ "SystemSignalLongSymbol" SG_ 960 VCRIGHT_a567_2RowSeatRequestWhil "VCRIGHT_a567_2RowSeatRequestWhileUncalibrated";
BA_ "SystemSignalLongSymbol" SG_ 960 VCRIGHT_a568_2RowSeatClashAvoida "VCRIGHT_a568_2RowSeatClashAvoidanceBlocked";
BA_ "SystemSignalLongSymbol" SG_ 960 VCRIGHT_a571_seatHeatDisabledRea "VCRIGHT_a571_seatHeatDisabledRearL";
BA_ "SystemSignalLongSymbol" SG_ 960 VCRIGHT_a572_seatHeatDisabledRea "VCRIGHT_a572_seatHeatDisabledRearC";
BA_ "SystemSignalLongSymbol" SG_ 960 VCRIGHT_a573_seatHeatDisabledRea "VCRIGHT_a573_seatHeatDisabledRearR";
BA_ "SystemSignalLongSymbol" SG_ 960 VCRIGHT_a574_2RowSeatStatsFromLa "VCRIGHT_a574_2RowSeatStatsFromLastStateDbg2";
BA_ "SystemSignalLongSymbol" SG_ 960 VCRIGHT_a575_3RowSeatStatsFromLa "VCRIGHT_a575_3RowSeatStatsFromLastStateDbg2";
BA_ "SystemSignalLongSymbol" SG_ 960 VCRIGHT_a579_liftgateFollowerUne "VCRIGHT_a579_liftgateFollowerUnexpectedStop";
BA_ "SystemSignalLongSymbol" SG_ 960 VCRIGHT_a580_debugLiftgateFollow "VCRIGHT_a580_debugLiftgateFollowerCurrentSpike";
BA_ "SystemSignalLongSymbol" SG_ 960 VCRIGHT_a583_doorRemoteUnlatched "VCRIGHT_a583_doorRemoteUnlatchedFront";
BA_ "SystemSignalLongSymbol" SG_ 960 VCRIGHT_a584_doorRemoteUnlatched "VCRIGHT_a584_doorRemoteUnlatchedRear";
BA_ "SystemSignalLongSymbol" SG_ 960 VCRIGHT_a585_doorRemoteUnlatchFa "VCRIGHT_a585_doorRemoteUnlatchFailedFront";
BA_ "SystemSignalLongSymbol" SG_ 960 VCRIGHT_a586_doorRemoteUnlatchFa "VCRIGHT_a586_doorRemoteUnlatchFailedRear";
BA_ "SystemSignalLongSymbol" SG_ 960 VCRIGHT_a589_defogSysDriverlessS "VCRIGHT_a589_defogSysDriverlessSelfTest";
BA_ "SystemSignalLongSymbol" SG_ 960 VCRIGHT_a590_seatEncStallThighSu "VCRIGHT_a590_seatEncStallThighSupport";
BA_ "SystemSignalLongSymbol" SG_ 960 VCRIGHT_a591_seatCurrUnderThighS "VCRIGHT_a591_seatCurrUnderThighSupport";
BA_ "SystemSignalLongSymbol" SG_ 960 VCRIGHT_a592_seatUncalThighSuppo "VCRIGHT_a592_seatUncalThighSupport";
BA_ "SystemSignalLongSymbol" SG_ 960 VCRIGHT_a593_seatEncOverThighSup "VCRIGHT_a593_seatEncOverThighSupport";
BA_ "SystemSignalLongSymbol" SG_ 960 VCRIGHT_a594_seatThighSupportSta "VCRIGHT_a594_seatThighSupportStallDebug";
BA_ "SystemSignalLongSymbol" SG_ 960 VCRIGHT_a595_seatThighSupportHCE "VCRIGHT_a595_seatThighSupportHCEncStlDbg";
BA_ "SystemSignalLongSymbol" SG_ 960 VCRIGHT_a596_frontDoorLatchUnexp "VCRIGHT_a596_frontDoorLatchUnexpectedVoltage";
BA_ "SystemSignalLongSymbol" SG_ 960 VCRIGHT_a597_rearDoorLatchUnexpe "VCRIGHT_a597_rearDoorLatchUnexpectedVoltage";
BA_ "SystemSignalLongSymbol" SG_ 960 VCRIGHT_a598_childModeMonitorTri "VCRIGHT_a598_childModeMonitorTrip";
BA_ "SystemSignalLongSymbol" SG_ 960 VCRIGHT_a599_LVBatteryTypeUnsupp "VCRIGHT_a599_LVBatteryTypeUnsupported";
BA_ "SystemSignalLongSymbol" SG_ 960 VCRIGHT_a605_CANMsgMACVerificati "VCRIGHT_a605_CANMsgMACVerificationKeyMismatch";
BA_ "Confidence" SG_ 1795 VCRIGHT_debugThermal10HzIndex 1;
BA_ "Confidence" SG_ 1795 VCRIGHT_hvacPanelFloorSplitRow1 0;
BA_ "Confidence" SG_ 1795 VCRIGHT_hvacDefrostPercent 0;
BA_ "Confidence" SG_ 1795 VCRIGHT_hvacRow2Percent 0;
BA_ "Confidence" SG_ 1795 VCRIGHT_hvacPanelFloorSplitRow2 0;
BA_ "Confidence" SG_ 1795 VCRIGHT_hvacFreshMassCounter 0;
BA_ "Confidence" SG_ 1795 VCRIGHT_hvacRecircMassCounter 0;
BA_ "Confidence" SG_ 1795 VCRIGHT_setTempAdjustmentLeft 0;
BA_ "GenSigSNA" SG_ 1795 VCRIGHT_setTempAdjustmentLeft "127";
BA_ "Confidence" SG_ 1795 VCRIGHT_setTempAdjustmentRight 0;
BA_ "GenSigSNA" SG_ 1795 VCRIGHT_setTempAdjustmentRight "127";
BA_ "Confidence" SG_ 1795 VCRIGHT_hvacLHVaneVelocity 0;
BA_ "Confidence" SG_ 1795 VCRIGHT_hvacRHVaneVelocity 0;
BA_ "Confidence" SG_ 1795 VCRIGHT_hvacVehicleSpeed 0;
BA_ "Confidence" SG_ 1795 VCRIGHT_hvacMassflowCompensated 0;
BA_ "Confidence" SG_ 1795 VCRIGHT_PTCcenterPowerLeft 0;
BA_ "GenSigSNA" SG_ 1795 VCRIGHT_PTCcenterPowerLeft "63";
BA_ "Confidence" SG_ 1795 VCRIGHT_PTCouterPowerLeft 0;
BA_ "GenSigSNA" SG_ 1795 VCRIGHT_PTCouterPowerLeft "63";
BA_ "Confidence" SG_ 1795 VCRIGHT_PTCinnerPowerLeft 0;
BA_ "GenSigSNA" SG_ 1795 VCRIGHT_PTCinnerPowerLeft "63";
BA_ "Confidence" SG_ 1795 VCRIGHT_PTCcenterPowerRight 0;
BA_ "GenSigSNA" SG_ 1795 VCRIGHT_PTCcenterPowerRight "63";
BA_ "Confidence" SG_ 1795 VCRIGHT_PTCouterPowerRight 0;
BA_ "GenSigSNA" SG_ 1795 VCRIGHT_PTCouterPowerRight "63";
BA_ "Confidence" SG_ 1795 VCRIGHT_PTCinnerPowerRight 0;
BA_ "GenSigSNA" SG_ 1795 VCRIGHT_PTCinnerPowerRight "63";
BA_ "Confidence" SG_ 1795 VCRIGHT_PTCcenterStoneTempLeft 0;
BA_ "GenSigSNA" SG_ 1795 VCRIGHT_PTCcenterStoneTempLeft "255";
BA_ "Confidence" SG_ 1795 VCRIGHT_PTCcenterStoneTempRight 0;
BA_ "GenSigSNA" SG_ 1795 VCRIGHT_PTCcenterStoneTempRight "255";
BA_ "Confidence" SG_ 1795 VCRIGHT_PTCinnerStoneTempLeft 0;
BA_ "GenSigSNA" SG_ 1795 VCRIGHT_PTCinnerStoneTempLeft "255";
BA_ "Confidence" SG_ 1795 VCRIGHT_PTCinnerStoneTempRight 0;
BA_ "GenSigSNA" SG_ 1795 VCRIGHT_PTCinnerStoneTempRight "255";
BA_ "Confidence" SG_ 1795 VCRIGHT_PTCouterStoneTempLeft 0;
BA_ "GenSigSNA" SG_ 1795 VCRIGHT_PTCouterStoneTempLeft "255";
BA_ "Confidence" SG_ 1795 VCRIGHT_PTCouterRodTempLeft 0;
BA_ "GenSigSNA" SG_ 1795 VCRIGHT_PTCouterRodTempLeft "255";
BA_ "Confidence" SG_ 1795 VCRIGHT_PTCouterAirTempLeft 0;
BA_ "GenSigSNA" SG_ 1795 VCRIGHT_PTCouterAirTempLeft "255";
BA_ "Confidence" SG_ 1795 VCRIGHT_PTCcenterRodTempLeft 0;
BA_ "GenSigSNA" SG_ 1795 VCRIGHT_PTCcenterRodTempLeft "255";
BA_ "Confidence" SG_ 1795 VCRIGHT_PTCinnerRodTempLeft 0;
BA_ "GenSigSNA" SG_ 1795 VCRIGHT_PTCinnerRodTempLeft "255";
BA_ "Confidence" SG_ 1795 VCRIGHT_PTCcenterAirTempLeft 0;
BA_ "GenSigSNA" SG_ 1795 VCRIGHT_PTCcenterAirTempLeft "255";
BA_ "Confidence" SG_ 1795 VCRIGHT_PTCinnerAirTempLeft 0;
BA_ "GenSigSNA" SG_ 1795 VCRIGHT_PTCinnerAirTempLeft "255";
BA_ "Confidence" SG_ 1795 VCRIGHT_PTCouterStoneTempRight 0;
BA_ "GenSigSNA" SG_ 1795 VCRIGHT_PTCouterStoneTempRight "255";
BA_ "Confidence" SG_ 1795 VCRIGHT_PTCouterRodTempRight 0;
BA_ "GenSigSNA" SG_ 1795 VCRIGHT_PTCouterRodTempRight "255";
BA_ "Confidence" SG_ 1795 VCRIGHT_PTCouterAirTempRight 0;
BA_ "GenSigSNA" SG_ 1795 VCRIGHT_PTCouterAirTempRight "255";
BA_ "Confidence" SG_ 1795 VCRIGHT_PTCcenterRodTempRight 0;
BA_ "GenSigSNA" SG_ 1795 VCRIGHT_PTCcenterRodTempRight "255";
BA_ "Confidence" SG_ 1795 VCRIGHT_PTCinnerRodTempRight 0;
BA_ "GenSigSNA" SG_ 1795 VCRIGHT_PTCinnerRodTempRight "255";
BA_ "Confidence" SG_ 1795 VCRIGHT_PTCcenterAirTempRight 0;
BA_ "GenSigSNA" SG_ 1795 VCRIGHT_PTCcenterAirTempRight "255";
BA_ "Confidence" SG_ 1795 VCRIGHT_PTCinnerAirTempRight 0;
BA_ "GenSigSNA" SG_ 1795 VCRIGHT_PTCinnerAirTempRight "255";
BA_ "Confidence" SG_ 259 VCRIGHT_doorClosureStatusFront 0;
BA_ "GenSigSNA" SG_ 259 VCRIGHT_doorClosureStatusFront "0";
BA_ "Confidence" SG_ 259 VCRIGHT_doorClosureStatusRear 0;
BA_ "GenSigSNA" SG_ 259 VCRIGHT_doorClosureStatusRear "0";
BA_ "Confidence" SG_ 259 VCRIGHT_frontLatchSwitch 0;
BA_ "Confidence" SG_ 259 VCRIGHT_rearLatchSwitch 0;
BA_ "Confidence" SG_ 259 VCRIGHT_frontHandlePulled 0;
BA_ "Confidence" SG_ 259 VCRIGHT_rearHandlePulled 0;
BA_ "Confidence" SG_ 259 VCRIGHT_frontRelActuatorSwitch 0;
BA_ "Confidence" SG_ 259 VCRIGHT_rearRelActuatorSwitch 0;
BA_ "Confidence" SG_ 259 VCRIGHT_frontLatchStatus 0;
BA_ "GenSigSNA" SG_ 259 VCRIGHT_frontLatchStatus "0";
BA_ "Confidence" SG_ 259 VCRIGHT_rearLatchStatus 0;
BA_ "GenSigSNA" SG_ 259 VCRIGHT_rearLatchStatus "0";
BA_ "Confidence" SG_ 259 VCRIGHT_lastDoorReqSourceFront 0;
BA_ "Confidence" SG_ 259 VCRIGHT_lastDoorReqSourceRear 0;
BA_ "Confidence" SG_ 259 VCRIGHT_frontIntSwitchFaulted 0;
BA_ "Confidence" SG_ 259 VCRIGHT_rearIntSwitchFaulted 0;
BA_ "Confidence" SG_ 259 VCRIGHT_frontHandlePulledPersist 0;
BA_ "Confidence" SG_ 259 VCRIGHT_frontIntSwitchPressed 0;
BA_ "Confidence" SG_ 259 VCRIGHT_rearIntSwitchPressed 0;
BA_ "Confidence" SG_ 259 VCRIGHT_mirrorTiltXPosition 0;
BA_ "Confidence" SG_ 259 VCRIGHT_mirrorTiltYPosition 0;
BA_ "Confidence" SG_ 259 VCRIGHT_mirrorState 0;
BA_ "Confidence" SG_ 259 VCRIGHT_mirrorFoldState 0;
BA_ "Confidence" SG_ 259 VCRIGHT_mirrorDipped 0;
BA_ "Confidence" SG_ 259 VCRIGHT_trunkLatchStatus 0;
BA_ "GenSigSNA" SG_ 259 VCRIGHT_trunkLatchStatus "0";
BA_ "Confidence" SG_ 259 VCRIGHT_mirrorRecallState 0;
BA_ "Confidence" SG_ 259 VCRIGHT_rearHandlePulledPersist 0;
BA_ "Confidence" SG_ 2010 VCRIGHT_doorStatus2Index 1;
BA_ "Confidence" SG_ 2010 VCRIGHT_frontLatchRelDuty 0;
BA_ "Confidence" SG_ 2010 VCRIGHT_BPillarCameraHeaterState 0;
BA_ "GenSigSNA" SG_ 2010 VCRIGHT_BPillarCameraHeaterState "0";
BA_ "Confidence" SG_ 2010 VCRIGHT_doorLatchAjarSwitchVolta 0;
BA_ "SystemSignalLongSymbol" SG_ 2010 VCRIGHT_doorLatchAjarSwitchVolta "VCRIGHT_doorLatchAjarSwitchVoltageF";
BA_ "Confidence" SG_ 2010 VCRIGHT_doorLatchAjarSwitch_0001 0;
BA_ "SystemSignalLongSymbol" SG_ 2010 VCRIGHT_doorLatchAjarSwitch_0001 "VCRIGHT_doorLatchAjarSwitchVoltageR";
BA_ "Confidence" SG_ 2010 VCRIGHT_BPillarCameraHeaterCurre 0;
BA_ "GenSigSNA" SG_ 2010 VCRIGHT_BPillarCameraHeaterCurre "63";
BA_ "SystemSignalLongSymbol" SG_ 2010 VCRIGHT_BPillarCameraHeaterCurre "VCRIGHT_BPillarCameraHeaterCurrent";
BA_ "Confidence" SG_ 2010 VCRIGHT_mirrorTiltXOffset 0;
BA_ "Confidence" SG_ 2010 VCRIGHT_mirrorTiltYOffset 0;
BA_ "Confidence" SG_ 915 VCRIGHT_epbmDebugIndex 1;
BA_ "Confidence" SG_ 915 VCRIGHT_epbmCaliperState 0;
BA_ "Confidence" SG_ 915 VCRIGHT_epbmMotorEnabled 0;
BA_ "Confidence" SG_ 915 VCRIGHT_epbMotorCurrent 0;
BA_ "Confidence" SG_ 915 VCRIGHT_epbmApplyVoltage 0;
BA_ "Confidence" SG_ 915 VCRIGHT_epbmReleaseVoltage 0;
BA_ "Confidence" SG_ 915 VCRIGHT_summonFaultReason 0;
BA_ "Confidence" SG_ 915 VCRIGHT_epbSummonState 0;
BA_ "Confidence" SG_ 915 VCRIGHT_epbmSummonState 0;
BA_ "Confidence" SG_ 915 VCRIGHT_epbUnitStatus 0;
BA_ "Confidence" SG_ 915 VCRIGHT_epbmFaultStatus 0;
BA_ "Confidence" SG_ 915 VCRIGHT_epbFaultStatus 0;
BA_ "Confidence" SG_ 915 VCRIGHT_epbmSystemStatus 0;
BA_ "Confidence" SG_ 915 VCRIGHT_epbmAutonomyBehavior 0;
BA_ "Confidence" SG_ 1123 VCRIGHT_cdpRequestState 0;
BA_ "Confidence" SG_ 1123 VCRIGHT_epbmSystemStatusQF 0;
BA_ "Confidence" SG_ 1123 VCRIGHT_epbmUnitStatus 0;
BA_ "Confidence" SG_ 1123 VCRIGHT_epbmCdpState 0;
BA_ "Confidence" SG_ 1123 VCRIGHT_epbmRedundantBrakingEnab 0;
BA_ "SystemSignalLongSymbol" SG_ 1123 VCRIGHT_epbmRedundantBrakingEnab "VCRIGHT_epbmRedundantBrakingEnabled";
BA_ "Confidence" SG_ 1123 VCRIGHT_epbmStatusCounter 0;
BA_ "Confidence" SG_ 1123 VCRIGHT_epbmStatusChecksum 0;
BA_ "Confidence" SG_ 524 VCRIGHT_wattsDemandEvap 0;
BA_ "Confidence" SG_ 524 VCRIGHT_hvacEvapEnabled 0;
BA_ "Confidence" SG_ 524 VCRIGHT_conditioningRequest 0;
BA_ "Confidence" SG_ 524 VCRIGHT_tempEvaporator 0;
BA_ "GenSigSNA" SG_ 524 VCRIGHT_tempEvaporator "2047";
BA_ "Confidence" SG_ 524 VCRIGHT_tempEvaporatorTarget 0;
BA_ "GenSigSNA" SG_ 524 VCRIGHT_tempEvaporatorTarget "255";
BA_ "Confidence" SG_ 524 VCRIGHT_hvacBlowerSpeedRPMReq 0;
BA_ "Confidence" SG_ 524 VCRIGHT_hvacPerfTestRunning 0;
BA_ "Confidence" SG_ 524 VCRIGHT_evapPerformanceLow 0;
BA_ "Confidence" SG_ 524 VCRIGHT_tempAmbientRaw 0;
BA_ "GenSigSNA" SG_ 524 VCRIGHT_tempAmbientRaw "0";
BA_ "Confidence" SG_ 524 VCRIGHT_hvacHeatingEnabledLeft 0;
BA_ "Confidence" SG_ 524 VCRIGHT_hvacHeatingEnabledRight 0;
BA_ "Confidence" SG_ 524 VCRIGHT_hvacPerfTestState 0;
BA_ "Confidence" SG_ 524 VCRIGHT_hvacUnavailable 0;
BA_ "Confidence" SG_ 524 VCRIGHT_hvacBlowerRPMActualAP 0;
BA_ "Confidence" SG_ 524 VCRIGHT_hvacEvapEnabledInColdAmb 0;
BA_ "SystemSignalLongSymbol" SG_ 524 VCRIGHT_hvacEvapEnabledInColdAmb "VCRIGHT_hvacEvapEnabledInColdAmbient";
BA_ "Confidence" SG_ 579 VCRIGHT_hvacStatusIndex 1;
BA_ "Confidence" SG_ 579 VCRIGHT_warmingUpStatus 0;
BA_ "Confidence" SG_ 579 VCRIGHT_coolingDownStatus 0;
BA_ "Confidence" SG_ 579 VCRIGHT_childModeHVACState 0;
BA_ "Confidence" SG_ 579 VCRIGHT_dogModeState 0;
BA_ "Confidence" SG_ 579 VCRIGHT_hvacCabinTempEstValid 0;
BA_ "Confidence" SG_ 579 VCRIGHT_COPNotRunningReasonFilte 0;
BA_ "SystemSignalLongSymbol" SG_ 579 VCRIGHT_COPNotRunningReasonFilte "VCRIGHT_COPNotRunningReasonFiltered";
BA_ "Confidence" SG_ 579 VCRIGHT_hvacCabinTempEst 0;
BA_ "Confidence" SG_ 579 VCRIGHT_hvacAirDistributionMode 0;
BA_ "Confidence" SG_ 579 VCRIGHT_hvacBlowerSegment 0;
BA_ "Confidence" SG_ 579 VCRIGHT_hvacRecirc 0;
BA_ "Confidence" SG_ 579 VCRIGHT_hvacACRunning 0;
BA_ "Confidence" SG_ 579 VCRIGHT_hvacPowerState 0;
BA_ "Confidence" SG_ 579 VCRIGHT_hvacVentStatus 0;
BA_ "Confidence" SG_ 579 VCRIGHT_hvacSecondRowState 0;
BA_ "Confidence" SG_ 579 VCRIGHT_hvacSystemNominal 0;
BA_ "Confidence" SG_ 579 VCRIGHT_hvacModelInitStatus 0;
BA_ "Confidence" SG_ 579 VCRIGHT_hvacMassflowRefrigSysRig 0;
BA_ "SystemSignalLongSymbol" SG_ 579 VCRIGHT_hvacMassflowRefrigSysRig "VCRIGHT_hvacMassflowRefrigSysRight";
BA_ "Confidence" SG_ 579 VCRIGHT_hvacRecircDoorPercent 0;
BA_ "Confidence" SG_ 579 VCRIGHT_tempDuctLeft 0;
BA_ "GenSigSNA" SG_ 579 VCRIGHT_tempDuctLeft "255";
BA_ "Confidence" SG_ 579 VCRIGHT_hvacMassflowRefrigSystem 0;
BA_ "Confidence" SG_ 579 VCRIGHT_tempDuctRight 0;
BA_ "GenSigSNA" SG_ 579 VCRIGHT_tempDuctRight "255";
BA_ "Confidence" SG_ 579 VCRIGHT_hvacMassflowRefrigSysLef 0;
BA_ "SystemSignalLongSymbol" SG_ 579 VCRIGHT_hvacMassflowRefrigSysLef "VCRIGHT_hvacMassflowRefrigSysLeft";
BA_ "Confidence" SG_ 579 VCRIGHT_hvacDuctTargetLeft 0;
BA_ "GenSigSNA" SG_ 579 VCRIGHT_hvacDuctTargetLeft "255";
BA_ "Confidence" SG_ 579 VCRIGHT_hvacDuctTargetRight 0;
BA_ "GenSigSNA" SG_ 579 VCRIGHT_hvacDuctTargetRight "255";
BA_ "Confidence" SG_ 579 VCRIGHT_enableTripleCameraFanPow 0;
BA_ "SystemSignalLongSymbol" SG_ 579 VCRIGHT_enableTripleCameraFanPow "VCRIGHT_enableTripleCameraFanPowerInSleep";
BA_ "Confidence" SG_ 579 VCRIGHT_tempDuctRightUpper 0;
BA_ "GenSigSNA" SG_ 579 VCRIGHT_tempDuctRightUpper "255";
BA_ "Confidence" SG_ 579 VCRIGHT_hpSplitTempsEnabled 0;
BA_ "Confidence" SG_ 579 VCRIGHT_hvacEvapInletTempEstimat 0;
BA_ "GenSigSNA" SG_ 579 VCRIGHT_hvacEvapInletTempEstimat "1023";
BA_ "SystemSignalLongSymbol" SG_ 579 VCRIGHT_hvacEvapInletTempEstimat "VCRIGHT_hvacEvapInletTempEstimate";
BA_ "Confidence" SG_ 579 VCRIGHT_tempMonitorNotNominal 0;
BA_ "Confidence" SG_ 579 VCRIGHT_hvacCabinAtTempTarget 0;
BA_ "Confidence" SG_ 579 VCRIGHT_hvacReqSecondRow 0;
BA_ "Confidence" SG_ 579 VCRIGHT_hvacAirflowReason 0;
BA_ "Confidence" SG_ 579 VCRIGHT_autoHvacBlowerShouldLimi 0;
BA_ "SystemSignalLongSymbol" SG_ 579 VCRIGHT_autoHvacBlowerShouldLimi "VCRIGHT_autoHvacBlowerShouldLimit";
BA_ "Confidence" SG_ 579 VCRIGHT_hvacReqThirdRow 0;
BA_ "Confidence" SG_ 579 VCRIGHT_solarLoadOnVehicle 0;
BA_ "GenSigSNA" SG_ 579 VCRIGHT_solarLoadOnVehicle "255";
BA_ "Confidence" SG_ 579 VCRIGHT_refrigDistCommanded 0;
BA_ "Confidence" SG_ 579 VCRIGHT_hvacFrontRightSeatFanSta 0;
BA_ "SystemSignalLongSymbol" SG_ 579 VCRIGHT_hvacFrontRightSeatFanSta "VCRIGHT_hvacFrontRightSeatFanStatus";
BA_ "Confidence" SG_ 579 VCRIGHT_hvacFrontLeftSeatFanStat 0;
BA_ "SystemSignalLongSymbol" SG_ 579 VCRIGHT_hvacFrontLeftSeatFanStat "VCRIGHT_hvacFrontLeftSeatFanStatus";
BA_ "Confidence" SG_ 579 VCRIGHT_hvacRefHighPowerRequest 0;
BA_ "Confidence" SG_ 579 VCRIGHT_windshieldCameraHeaterDu 0;
BA_ "SystemSignalLongSymbol" SG_ 579 VCRIGHT_windshieldCameraHeaterDu "VCRIGHT_windshieldCameraHeaterDutyRequest";
BA_ "Confidence" SG_ 579 VCRIGHT_extendedHvacPerfTestSupp 0;
BA_ "SystemSignalLongSymbol" SG_ 579 VCRIGHT_extendedHvacPerfTestSupp "VCRIGHT_extendedHvacPerfTestSupportState";
BA_ "Confidence" SG_ 579 VCRIGHT_hvacFrontRightSeatHeatSt 0;
BA_ "SystemSignalLongSymbol" SG_ 579 VCRIGHT_hvacFrontRightSeatHeatSt "VCRIGHT_hvacFrontRightSeatHeatStatus";
BA_ "Confidence" SG_ 579 VCRIGHT_hvacSeatFrontLeftTempTar 0;
BA_ "SystemSignalLongSymbol" SG_ 579 VCRIGHT_hvacSeatFrontLeftTempTar "VCRIGHT_hvacSeatFrontLeftTempTarget";
BA_ "Confidence" SG_ 579 VCRIGHT_hvacManualToAutoNotify 0;
BA_ "Confidence" SG_ 579 VCRIGHT_hvacRequestsFullAuto 0;
BA_ "Confidence" SG_ 579 VCRIGHT_passengerPresentHvacCycl 0;
BA_ "SystemSignalLongSymbol" SG_ 579 VCRIGHT_passengerPresentHvacCycl "VCRIGHT_passengerPresentHvacCycle";
BA_ "Confidence" SG_ 579 VCRIGHT_hvacRequestsAutoIntake 0;
BA_ "Confidence" SG_ 579 VCRIGHT_steeringWheelHeatStatus 0;
BA_ "Confidence" SG_ 579 VCRIGHT_autoDefogStatus 0;
BA_ "Confidence" SG_ 579 VCRIGHT_solarElevation 0;
BA_ "GenSigSNA" SG_ 579 VCRIGHT_solarElevation "256";
BA_ "Confidence" SG_ 579 VCRIGHT_minsToSunrise 0;
BA_ "GenSigSNA" SG_ 579 VCRIGHT_minsToSunrise "255";
BA_ "Confidence" SG_ 579 VCRIGHT_minsToSunset 0;
BA_ "GenSigSNA" SG_ 579 VCRIGHT_minsToSunset "255";
BA_ "Confidence" SG_ 579 VCRIGHT_hvacLimitedReasonRight 0;
BA_ "Confidence" SG_ 579 VCRIGHT_hvacLimitedReasonLeft 0;
BA_ "Confidence" SG_ 579 VCRIGHT_hvacOverheatProtActive 0;
BA_ "Confidence" SG_ 579 VCRIGHT_autoSwingAvailable 0;
BA_ "Confidence" SG_ 579 VCRIGHT_tempDuctLeftUpper 0;
BA_ "GenSigSNA" SG_ 579 VCRIGHT_tempDuctLeftUpper "255";
BA_ "Confidence" SG_ 579 VCRIGHT_hvacFrontLeftSeatHeatSta 0;
BA_ "SystemSignalLongSymbol" SG_ 579 VCRIGHT_hvacFrontLeftSeatHeatSta "VCRIGHT_hvacFrontLeftSeatHeatStatus";
BA_ "Confidence" SG_ 579 VCRIGHT_hvacQdotLeft 0;
BA_ "Confidence" SG_ 579 VCRIGHT_hvacQdotRight 0;
BA_ "Confidence" SG_ 579 VCRIGHT_tempDuctLeftLower 0;
BA_ "GenSigSNA" SG_ 579 VCRIGHT_tempDuctLeftLower "255";
BA_ "Confidence" SG_ 579 VCRIGHT_tempDuctRightLower 0;
BA_ "GenSigSNA" SG_ 579 VCRIGHT_tempDuctRightLower "255";
BA_ "Confidence" SG_ 579 VCRIGHT_foggingControllerResetRe 0;
BA_ "SystemSignalLongSymbol" SG_ 579 VCRIGHT_foggingControllerResetRe "VCRIGHT_foggingControllerResetReason";
BA_ "Confidence" SG_ 579 VCRIGHT_modeledCabinPressure 0;
BA_ "Confidence" SG_ 579 VCRIGHT_blowerTorqueIndex 0;
BA_ "Confidence" SG_ 579 VCRIGHT_autoSwingLeftPosX 0;
BA_ "Confidence" SG_ 579 VCRIGHT_autoSwingRightPositionX 0;
BA_ "Confidence" SG_ 1675 VCRIGHT_hvacSeat1RLCushionFanTrg 0;
BA_ "SystemSignalLongSymbol" SG_ 1675 VCRIGHT_hvacSeat1RLCushionFanTrg "VCRIGHT_hvacSeat1RLCushionFanTrgt";
BA_ "Confidence" SG_ 1675 VCRIGHT_hvacSeat1RLBackrestFanTr 0;
BA_ "SystemSignalLongSymbol" SG_ 1675 VCRIGHT_hvacSeat1RLBackrestFanTr "VCRIGHT_hvacSeat1RLBackrestFanTrgt";
BA_ "Confidence" SG_ 1675 VCRIGHT_hvacSeat1RRCushionFanTrg 0;
BA_ "SystemSignalLongSymbol" SG_ 1675 VCRIGHT_hvacSeat1RRCushionFanTrg "VCRIGHT_hvacSeat1RRCushionFanTrgt";
BA_ "Confidence" SG_ 1675 VCRIGHT_hvacSeat1RRBackrestFanTr 0;
BA_ "SystemSignalLongSymbol" SG_ 1675 VCRIGHT_hvacSeat1RRBackrestFanTr "VCRIGHT_hvacSeat1RRBackrestFanTrgt";
BA_ "Confidence" SG_ 1675 VCRIGHT_hvac2RActuatorsEnable 0;
BA_ "Confidence" SG_ 1675 VCRIGHT_hvac2RLeftLateralTarget 0;
BA_ "Confidence" SG_ 1675 VCRIGHT_hvac2RLeftVerticalTarget 0;
BA_ "Confidence" SG_ 1675 VCRIGHT_hvac2RRightLateralTarget 0;
BA_ "Confidence" SG_ 1675 VCRIGHT_hvac2RRightVerticalTarge 0;
BA_ "SystemSignalLongSymbol" SG_ 1675 VCRIGHT_hvac2RRightVerticalTarge "VCRIGHT_hvac2RRightVerticalTarget";
BA_ "Confidence" SG_ 774 VCRIGHT_infoIndex 1;
BA_ "Confidence" SG_ 774 VCRIGHT_infoBuildType 0;
BA_ "Confidence" SG_ 774 VCRIGHT_infoBuildConfigId 0;
BA_ "Confidence" SG_ 774 VCRIGHT_infoHardwareId 0;
BA_ "Confidence" SG_ 774 VCRIGHT_infoComponentId 0;
BA_ "Confidence" SG_ 774 VCRIGHT_infoPcbaId 0;
BA_ "Confidence" SG_ 774 VCRIGHT_infoAssemblyId 0;
BA_ "GenSigSNA" SG_ 774 VCRIGHT_infoAssemblyId "255";
BA_ "Confidence" SG_ 774 VCRIGHT_infoUsageId 0;
BA_ "Confidence" SG_ 774 VCRIGHT_infoSubUsageId 0;
BA_ "Confidence" SG_ 774 VCRIGHT_infoAppCrc 0;
BA_ "Confidence" SG_ 774 VCRIGHT_infoLUMBARRAppCRC 0;
BA_ "Confidence" SG_ 774 VCRIGHT_infoAppGitHash 0;
BA_ "Confidence" SG_ 774 VCRIGHT_infoBootGitHash 0;
BA_ "Confidence" SG_ 774 VCRIGHT_infoPlatformType 0;
BA_ "Confidence" SG_ 774 VCRIGHT_infoBootUdsProtoVersion 0;
BA_ "Confidence" SG_ 774 VCRIGHT_infoBootCrc 0;
VAL_ 2011 VCRIGHT_a518_seatState 15 "SNA" 12 "CALIBRATING_ABSOLUTE_SENSOR" 11 "CALIBRATING_ZERO_POSITION" 10 "WAITING_TO_CLEAR_FOR_UNFOLD" 9 "WAITING_TO_CLEAR_FOR_FOLD" 8 "MOVING_REARWARD_TO_POSITION" 7 "MOVING_FORWARD_TO_POSITION" 6 "UNFOLDING" 5 "FOLDING" 4 "ADJUSTING_REARWARD_FAST" 3 "ADJUSTING_FORWARD_FAST" 2 "ADJUSTING_REARWARD_COMFORT" 1 "ADJUSTING_FORWARD_COMFORT" 0 "STOPPED" ;
VAL_ 2011 VCRIGHT_a520_epbConfig 11 "CT_MANDO" 10 "MODEL3_ZF" 9 "MODELS_CERAMIC" 8 "MODELY_PERFORMANCE_V2" 7 "MODEL3_PERFORMANCE_V2" 6 "MODELX_BASE" 5 "MODELY_PERFORMANCE" 4 "MODELY_BASE" 3 "MODELS_BASE" 2 "MODEL3_PERFORMANCE" 1 "MODEL3_BASE" 0 "UNKNOWN" ;
VAL_ 2011 VCRIGHT_a520_gtwEpbConfig 11 "CT_MANDO" 10 "MODEL3_ZF" 9 "MODELS_CERAMIC" 8 "MODELY_PERFORMANCE_V2" 7 "MODEL3_PERFORMANCE_V2" 6 "MODELX_BASE" 5 "MODELY_PERFORMANCE" 4 "MODELY_BASE" 3 "MODELS_BASE" 2 "MODEL3_PERFORMANCE" 1 "MODEL3_BASE" 0 "UNKNOWN" ;
VAL_ 2011 VCRIGHT_a525_GTW_twelveVBatteryT 3 "TESLA_16V_LI_ION" 2 "CATL_LI_ION" 1 "CLARIOS_B24_FLOODED" 0 "ATLASBX_B24_FLOODED" ;
VAL_ 2011 VCRIGHT_a525_newLVBatteryType 5 "TESLA_48V_LI_ION" 4 "TESLA_16V_LI_ION" 3 "CATL_LI_ION" 2 "CLARIOS_B24_FLOODED" 1 "ATLASBX_B24_FLOODED" 0 "UNKNOWN" ;
VAL_ 2011 VCRIGHT_a525_initialLVBatteryTyp 5 "TESLA_48V_LI_ION" 4 "TESLA_16V_LI_ION" 3 "CATL_LI_ION" 2 "CLARIOS_B24_FLOODED" 1 "ATLASBX_B24_FLOODED" 0 "UNKNOWN" ;
VAL_ 2011 VCRIGHT_a545_GTW_twelveVBatteryT 3 "TESLA_16V_LI_ION" 2 "CATL_LI_ION" 1 "CLARIOS_B24_FLOODED" 0 "ATLASBX_B24_FLOODED" ;
VAL_ 2011 VCRIGHT_a545_newLVBatteryType 5 "TESLA_48V_LI_ION" 4 "TESLA_16V_LI_ION" 3 "CATL_LI_ION" 2 "CLARIOS_B24_FLOODED" 1 "ATLASBX_B24_FLOODED" 0 "UNKNOWN" ;
VAL_ 2011 VCRIGHT_a560_seatState 15 "SNA" 12 "CALIBRATING_ABSOLUTE_SENSOR" 11 "CALIBRATING_ZERO_POSITION" 10 "WAITING_TO_CLEAR_FOR_UNFOLD" 9 "WAITING_TO_CLEAR_FOR_FOLD" 8 "MOVING_REARWARD_TO_POSITION" 7 "MOVING_FORWARD_TO_POSITION" 6 "UNFOLDING" 5 "FOLDING" 4 "ADJUSTING_REARWARD_FAST" 3 "ADJUSTING_FORWARD_FAST" 2 "ADJUSTING_REARWARD_COMFORT" 1 "ADJUSTING_FORWARD_COMFORT" 0 "STOPPED" ;
VAL_ 2011 VCRIGHT_a560_motorType 1 "KEIPER" 0 "SHB_OR_UNKNOWN" ;
VAL_ 2011 VCRIGHT_a560_absPosSensState 3 "DISCONNECTED" 2 "FORWARD" 1 "REARWARD" 0 "FAULTED" ;
VAL_ 2011 VCRIGHT_a563_seatStatePrev 15 "SNA" 12 "CALIBRATING_ABSOLUTE_SENSOR" 11 "CALIBRATING_ZERO_POSITION" 10 "WAITING_TO_CLEAR_FOR_UNFOLD" 9 "WAITING_TO_CLEAR_FOR_FOLD" 8 "MOVING_REARWARD_TO_POSITION" 7 "MOVING_FORWARD_TO_POSITION" 6 "UNFOLDING" 5 "FOLDING" 4 "ADJUSTING_REARWARD_FAST" 3 "ADJUSTING_FORWARD_FAST" 2 "ADJUSTING_REARWARD_COMFORT" 1 "ADJUSTING_FORWARD_COMFORT" 0 "STOPPED" ;
VAL_ 2011 VCRIGHT_a563_obstacleDetectReaso 8 "MAX_SPEED_DIFF" 7 "SPEED_THRESHOLD" 6 "MEDIUM_CURRENT_THRESHOLD" 5 "ACCEL_LOOKBACK_COMP_ABS" 4 "ACCEL_LOOKBACK_UNCOMP_REL" 3 "ACCEL_LOOKBACK_UNCOMP_ABS" 2 "MOTOR_ENCODER_STALL" 1 "MOTOR_CURRENT_STALL" 0 "NONE" ;
VAL_ 2011 VCRIGHT_a563_motorType 1 "KEIPER" 0 "SHB_OR_UNKNOWN" ;
VAL_ 2011 VCRIGHT_a568_seatState 15 "SNA" 12 "CALIBRATING_ABSOLUTE_SENSOR" 11 "CALIBRATING_ZERO_POSITION" 10 "WAITING_TO_CLEAR_FOR_UNFOLD" 9 "WAITING_TO_CLEAR_FOR_FOLD" 8 "MOVING_REARWARD_TO_POSITION" 7 "MOVING_FORWARD_TO_POSITION" 6 "UNFOLDING" 5 "FOLDING" 4 "ADJUSTING_REARWARD_FAST" 3 "ADJUSTING_FORWARD_FAST" 2 "ADJUSTING_REARWARD_COMFORT" 1 "ADJUSTING_FORWARD_COMFORT" 0 "STOPPED" ;
VAL_ 2011 VCRIGHT_a579_liftgateFollowerSto 3 "PINCH_SENSITIVE" 2 "OBSTACLE_CURRENT_SPIKE" 1 "OBSTACLE_CURRENT" 0 "NONE" ;
VAL_ 2011 VCRIGHT_a579_liftgateFollowerLat 8 "FAULT" 7 "DEFAULT" 6 "TIMEOUT" 5 "AJAR" 4 "OPENING" 3 "CLOSING" 2 "CLOSED" 1 "OPENED" 0 "SNA" ;
VAL_ 2011 VCRIGHT_a585_ambientTemp 0 "SNA" ;
VAL_ 2011 VCRIGHT_a586_ambientTemp 0 "SNA" ;
VAL_ 2011 VCRIGHT_a590_seatMotorState 5 "UNDEFINED" 4 "CALIBRATING" 3 "RECALLING" 2 "MOVING_DOWN" 1 "MOVING_UP" 0 "STOPPED" ;
VAL_ 2011 VCRIGHT_a590_seatSwitchBack 3 "FAULT" 2 "ON" 1 "OFF" 0 "SNA" ;
VAL_ 2011 VCRIGHT_a590_seatSwitchForward 3 "FAULT" 2 "ON" 1 "OFF" 0 "SNA" ;
VAL_ 2011 VCRIGHT_a591_seatMotorState 5 "UNDEFINED" 4 "CALIBRATING" 3 "RECALLING" 2 "MOVING_DOWN" 1 "MOVING_UP" 0 "STOPPED" ;
VAL_ 2011 VCRIGHT_a591_seatSwitchBack 3 "FAULT" 2 "ON" 1 "OFF" 0 "SNA" ;
VAL_ 2011 VCRIGHT_a591_seatSwitchForward 3 "FAULT" 2 "ON" 1 "OFF" 0 "SNA" ;
VAL_ 2011 VCRIGHT_a592_seatMotorState 5 "UNDEFINED" 4 "CALIBRATING" 3 "RECALLING" 2 "MOVING_DOWN" 1 "MOVING_UP" 0 "STOPPED" ;
VAL_ 2011 VCRIGHT_a592_seatSwitchBack 3 "FAULT" 2 "ON" 1 "OFF" 0 "SNA" ;
VAL_ 2011 VCRIGHT_a592_seatSwitchForward 3 "FAULT" 2 "ON" 1 "OFF" 0 "SNA" ;
VAL_ 2011 VCRIGHT_a593_seatMotorState 5 "UNDEFINED" 4 "CALIBRATING" 3 "RECALLING" 2 "MOVING_DOWN" 1 "MOVING_UP" 0 "STOPPED" ;
VAL_ 2011 VCRIGHT_a593_seatSwitchBack 3 "FAULT" 2 "ON" 1 "OFF" 0 "SNA" ;
VAL_ 2011 VCRIGHT_a593_seatSwitchForward 3 "FAULT" 2 "ON" 1 "OFF" 0 "SNA" ;
VAL_ 2011 VCRIGHT_a594_seatMotorState 5 "UNDEFINED" 4 "CALIBRATING" 3 "RECALLING" 2 "MOVING_DOWN" 1 "MOVING_UP" 0 "STOPPED" ;
VAL_ 2011 VCRIGHT_a595_seatMotorState 5 "UNDEFINED" 4 "CALIBRATING" 3 "RECALLING" 2 "MOVING_DOWN" 1 "MOVING_UP" 0 "STOPPED" ;
VAL_ 2011 VCRIGHT_a599_GTW_twelveVBatteryT 3 "TESLA_16V_LI_ION" 2 "CATL_LI_ION" 1 "CLARIOS_B24_FLOODED" 0 "ATLASBX_B24_FLOODED" ;
VAL_ 2011 VCRIGHT_a599_newLVBatteryType 5 "TESLA_48V_LI_ION" 4 "TESLA_16V_LI_ION" 3 "CATL_LI_ION" 2 "CLARIOS_B24_FLOODED" 1 "ATLASBX_B24_FLOODED" 0 "UNKNOWN" ;
VAL_ 2011 VCRIGHT_a599_initialLVBatteryTyp 5 "TESLA_48V_LI_ION" 4 "TESLA_16V_LI_ION" 3 "CATL_LI_ION" 2 "CLARIOS_B24_FLOODED" 1 "ATLASBX_B24_FLOODED" 0 "UNKNOWN" ;
VAL_ 960 VCRIGHT_matrixIndex 10 "AlertMatrix10" 9 "AlertMatrix9" 8 "AlertMatrix8" 7 "AlertMatrix7" 6 "AlertMatrix6" 5 "AlertMatrix5" 4 "AlertMatrix4" 3 "AlertMatrix3" 2 "AlertMatrix2" 1 "AlertMatrix1" 0 "AlertMatrix0" ;
VAL_ 1795 VCRIGHT_debugThermal10HzIndex 10 "END" 9 "HVAC_ACTUATOR_TUNNING" 8 "HVAC_PTC_COI_DEV4" 7 "HVAC_PTC_COI_DEV3" 6 "HVAC_PTC_COI_DEV2" 5 "HVAC_PTC_COI_DEV1" 4 "actuatorStatus" 3 "cabinModel" 2 "airflow" 1 "temps" 0 "heaterAndEvapWatts" ;
VAL_ 1795 VCRIGHT_setTempAdjustmentLeft 127 "SNA" ;
VAL_ 1795 VCRIGHT_setTempAdjustmentRight 127 "SNA" ;
VAL_ 1795 VCRIGHT_PTCcenterPowerLeft 63 "SNA" ;
VAL_ 1795 VCRIGHT_PTCouterPowerLeft 63 "SNA" ;
VAL_ 1795 VCRIGHT_PTCinnerPowerLeft 63 "SNA" ;
VAL_ 1795 VCRIGHT_PTCcenterPowerRight 63 "SNA" ;
VAL_ 1795 VCRIGHT_PTCouterPowerRight 63 "SNA" ;
VAL_ 1795 VCRIGHT_PTCinnerPowerRight 63 "SNA" ;
VAL_ 1795 VCRIGHT_PTCcenterStoneTempLeft 255 "SNA" ;
VAL_ 1795 VCRIGHT_PTCcenterStoneTempRight 255 "SNA" ;
VAL_ 1795 VCRIGHT_PTCinnerStoneTempLeft 255 "SNA" ;
VAL_ 1795 VCRIGHT_PTCinnerStoneTempRight 255 "SNA" ;
VAL_ 1795 VCRIGHT_PTCouterStoneTempLeft 255 "SNA" ;
VAL_ 1795 VCRIGHT_PTCouterRodTempLeft 255 "SNA" ;
VAL_ 1795 VCRIGHT_PTCouterAirTempLeft 255 "SNA" ;
VAL_ 1795 VCRIGHT_PTCcenterRodTempLeft 255 "SNA" ;
VAL_ 1795 VCRIGHT_PTCinnerRodTempLeft 255 "SNA" ;
VAL_ 1795 VCRIGHT_PTCcenterAirTempLeft 255 "SNA" ;
VAL_ 1795 VCRIGHT_PTCinnerAirTempLeft 255 "SNA" ;
VAL_ 1795 VCRIGHT_PTCouterStoneTempRight 255 "SNA" ;
VAL_ 1795 VCRIGHT_PTCouterRodTempRight 255 "SNA" ;
VAL_ 1795 VCRIGHT_PTCouterAirTempRight 255 "SNA" ;
VAL_ 1795 VCRIGHT_PTCcenterRodTempRight 255 "SNA" ;
VAL_ 1795 VCRIGHT_PTCinnerRodTempRight 255 "SNA" ;
VAL_ 1795 VCRIGHT_PTCcenterAirTempRight 255 "SNA" ;
VAL_ 1795 VCRIGHT_PTCinnerAirTempRight 255 "SNA" ;
VAL_ 259 VCRIGHT_doorClosureStatusFront 8 "CLOSURE_STATUS_FAULT" 2 "CLOSURE_STATUS_CLOSED" 1 "CLOSURE_STATUS_OPEN" 0 "CLOSURE_STATUS_SNA" ;
VAL_ 259 VCRIGHT_doorClosureStatusRear 8 "CLOSURE_STATUS_FAULT" 2 "CLOSURE_STATUS_CLOSED" 1 "CLOSURE_STATUS_OPEN" 0 "CLOSURE_STATUS_SNA" ;
VAL_ 259 VCRIGHT_frontLatchStatus 8 "LATCH_FAULT" 7 "LATCH_DEFAULT" 6 "LATCH_TIMEOUT" 5 "LATCH_AJAR" 4 "LATCH_OPENING" 3 "LATCH_CLOSING" 2 "LATCH_CLOSED" 1 "LATCH_OPENED" 0 "LATCH_SNA" ;
VAL_ 259 VCRIGHT_rearLatchStatus 8 "LATCH_FAULT" 7 "LATCH_DEFAULT" 6 "LATCH_TIMEOUT" 5 "LATCH_AJAR" 4 "LATCH_OPENING" 3 "LATCH_CLOSING" 2 "LATCH_CLOSED" 1 "LATCH_OPENED" 0 "LATCH_SNA" ;
VAL_ 259 VCRIGHT_lastDoorReqSourceFront 4 "DOOR_REQUEST_SOURCE_ECU" 3 "DOOR_REQUEST_SOURCE_VCSEC" 2 "DOOR_REQUEST_SOURCE_EXTERIOR_HANDLE" 1 "DOOR_REQUEST_SOURCE_INTERIOR_BUTTON" 0 "DOOR_REQUEST_SOURCE_UNKNOWN" ;
VAL_ 259 VCRIGHT_lastDoorReqSourceRear 4 "DOOR_REQUEST_SOURCE_ECU" 3 "DOOR_REQUEST_SOURCE_VCSEC" 2 "DOOR_REQUEST_SOURCE_EXTERIOR_HANDLE" 1 "DOOR_REQUEST_SOURCE_INTERIOR_BUTTON" 0 "DOOR_REQUEST_SOURCE_UNKNOWN" ;
VAL_ 259 VCRIGHT_mirrorState 5 "MIRROR_STATE_CALIBRATION" 4 "MIRROR_STATE_RECALL" 3 "MIRROR_STATE_FOLD_UNFOLD" 2 "MIRROR_STATE_TILT_Y" 1 "MIRROR_STATE_TILT_X" 0 "MIRROR_STATE_IDLE" ;
VAL_ 259 VCRIGHT_mirrorFoldState 4 "MIRROR_FOLD_STATE_UNFOLDING" 3 "MIRROR_FOLD_STATE_FOLDING" 2 "MIRROR_FOLD_STATE_UNFOLDED" 1 "MIRROR_FOLD_STATE_FOLDED" 0 "MIRROR_FOLD_STATE_UNKNOWN" ;
VAL_ 259 VCRIGHT_trunkLatchStatus 8 "LATCH_FAULT" 7 "LATCH_DEFAULT" 6 "LATCH_TIMEOUT" 5 "LATCH_AJAR" 4 "LATCH_OPENING" 3 "LATCH_CLOSING" 2 "LATCH_CLOSED" 1 "LATCH_OPENED" 0 "LATCH_SNA" ;
VAL_ 259 VCRIGHT_mirrorRecallState 5 "MIRROR_RECALL_STATE_RECALLING_STOPPED" 4 "MIRROR_RECALL_STATE_RECALLING_FAILED" 3 "MIRROR_RECALL_STATE_RECALLING_COMPLETE" 2 "MIRROR_RECALL_STATE_RECALLING_AXIS_2" 1 "MIRROR_RECALL_STATE_RECALLING_AXIS_1" 0 "MIRROR_RECALL_STATE_INIT" ;
VAL_ 2010 VCRIGHT_doorStatus2Index 1 "MUX1" 0 "MUX0" ;
VAL_ 2010 VCRIGHT_BPillarCameraHeaterState 4 "HEATER_STATE_FAULT" 3 "HEATER_STATE_OFF_UNAVAILABLE" 2 "HEATER_STATE_OFF" 1 "HEATER_STATE_ON" 0 "HEATER_STATE_SNA" ;
VAL_ 2010 VCRIGHT_BPillarCameraHeaterCurre 63 "SNA" ;
VAL_ 915 VCRIGHT_epbmDebugIndex 1 "TRANSITIONS" 0 "STATES" ;
VAL_ 915 VCRIGHT_epbmCaliperState 6 "EPB_SAVED_CALIPERSTATE_WINCHMODE" 5 "EPB_SAVED_CALIPERSTATE_SERVICE" 4 "EPB_SAVED_CALIPERSTATE_OPEN" 3 "EPB_SAVED_CALIPERSTATE_PARK" 2 "EPB_SAVED_CALIPERSTATE_REAPPLY" 1 "EPB_SAVED_CALIPERSTATE_UNKNOWN" 0 "EPB_SAVED_CALIPERSTATE_UNSAVED" ;
VAL_ 915 VCRIGHT_summonFaultReason 30 "EPB_SUMMONFAULT_MONITOR_TYPE_UNKNOWN" 29 "EPB_SUMMONFAULT_AP_MONITOR" 28 "EPB_SUMMONFAULT_REMOTE_DID_NOT_START" 27 "EPB_SUMMONFAULT_INVALID_REMOTE_STATE" 26 "EPB_SUMMONFAULT_START_IN_UNAVAILABLE" 25 "EPB_SUMMONFAULT_REMOTE_UNIT_FAULTED" 24 "EPB_SUMMONFAULT_LOCAL_UNIT_FAULTED" 23 "EPB_SUMMONFAULT_REMOTE_SUMMON_FAULTED" 22 "EPB_SUMMONFAULT_EPBREMOTE_MIA" 21 "EPB_SUMMONFAULT_PASSIVE_REQUEST" 20 "EPB_SUMMONFAULT_DI_STATE_INVALID" 19 "EPB_SUMMONFAULT_EPB_FAULT" 18 "EPB_SUMMONFAULT_MISMATCH" 17 "EPB_SUMMONFAULT_OOC" 16 "EPB_SUMMONFAULT_PM_REQUEST" 15 "EPB_SUMMONFAULT_PM_MIA" 14 "EPB_SUMMONFAULT_PARK_MIA" 13 "EPB_SUMMONFAULT_EXTERNAL" 12 "EPB_SUMMONFAULT_SPEED" 11 "EPB_SUMMONFAULT_EPBM_REQUEST" 10 "EPB_SUMMONFAULT_EAC_NOT_ALLOWED" 9 "EPB_SUMMONFAULT_VEH_CAN_FAULT" 8 "EPB_SUMMONFAULT_ESP_FAULT" 7 "EPB_SUMMONFAULT_DAS_FAULT" 6 "EPB_SUMMONFAULT_DI_APC_FAULT" 5 "EPB_SUMMONFAULT_DI_FAULT" 4 "EPB_SUMMONFAULT_EPBM_MIA" 3 "EPB_SUMMONFAULT_ESP_MIA" 2 "EPB_SUMMONFAULT_DAS_MIA" 1 "EPB_SUMMONFAULT_DI_MIA" 0 "EPB_SUMMONFAULT_NONE" ;
VAL_ 915 VCRIGHT_epbSummonState 6 "EPB_SUMMON_UNAVAILABLE" 5 "EPB_SUMMON_FAULT" 4 "EPB_SUMMON_COMPLETE" 3 "EPB_SUMMON_ACTIVE" 2 "EPB_SUMMON_ARMED" 1 "EPB_SUMMON_IDLE" 0 "EPB_SUMMON_INIT" ;
VAL_ 915 VCRIGHT_epbmSummonState 6 "EPB_SUMMON_UNAVAILABLE" 5 "EPB_SUMMON_FAULT" 4 "EPB_SUMMON_COMPLETE" 3 "EPB_SUMMON_ACTIVE" 2 "EPB_SUMMON_ARMED" 1 "EPB_SUMMON_IDLE" 0 "EPB_SUMMON_INIT" ;
VAL_ 915 VCRIGHT_epbUnitStatus 23 "EPB_STATUS_COUNT" 22 "EPB_STATUS_AUTONOMY_OPEN" 21 "EPB_STATUS_FREE_ROLL_MODE" 20 "EPB_STATUS_DYNAMIC_PARKING" 19 "EPB_STATUS_EXTERNAL_PARKING" 18 "EPB_STATUS_RELEASING_FOR_EXTERNAL_PARK" 17 "EPB_STATUS_EXTERNAL_DYNAMIC" 16 "EPB_STATUS_SUMMON_PARKING" 15 "EPB_STATUS_SUMMON_RELEASING" 14 "EPB_STATUS_SUMMON" 13 "EPB_STATUS_WINCHMODE_PENDING" 12 "EPB_STATUS_PARK_PENDING" 11 "EPB_STATUS_SERVICE_RELEASING" 10 "EPB_STATUS_RELEASING" 9 "EPB_STATUS_DYNAMIC_APPLYING" 8 "EPB_STATUS_PARKING" 7 "EPB_STATUS_WINCHMODE_RELEASING" 6 "EPB_STATUS_WINCHMODE" 5 "EPB_STATUS_SERVICE" 4 "EPB_STATUS_START" 3 "EPB_STATUS_PARK" 2 "EPB_STATUS_DYNAMIC" 1 "EPB_STATUS_OPEN" 0 "EPB_STATUS_UNKNOWN" ;
VAL_ 915 VCRIGHT_epbmFaultStatus 3 "EPB_STATUS_FAULT_IDLE" 2 "EPB_STATUS_FAULT" 1 "EPB_STATUS_RETRY" 0 "EPB_STATUS_NOMINAL" ;
VAL_ 915 VCRIGHT_epbFaultStatus 3 "EPB_STATUS_FAULT_IDLE" 2 "EPB_STATUS_FAULT" 1 "EPB_STATUS_RETRY" 0 "EPB_STATUS_NOMINAL" ;
VAL_ 915 VCRIGHT_epbmSystemStatus 8 "EPB_VEHICLE_STATUS_MISMATCH" 7 "EPB_VEHICLE_STATUS_FAULT_SECURE" 6 "EPB_VEHICLE_STATUS_FAULT" 5 "EPB_VEHICLE_STATUS_RELEASING" 4 "EPB_VEHICLE_STATUS_PARKING" 3 "EPB_VEHICLE_STATUS_DYNAMIC" 2 "EPB_VEHICLE_STATUS_PARKED" 1 "EPB_VEHICLE_STATUS_RELEASED" 0 "EPB_VEHICLE_STATUS_UNKNOWN" ;
VAL_ 915 VCRIGHT_epbmAutonomyBehavior 2 "DRIVERLESS_NO_TAKEOVER" 1 "DRIVERLESS_TAKEOVER" 0 "DRIVER" ;
VAL_ 1123 VCRIGHT_cdpRequestState 1 "EPB_CDP_REQUEST_VALID" 0 "EPB_CDP_REQUEST_INVALID" ;
VAL_ 1123 VCRIGHT_epbmSystemStatusQF 1 "EPBM_SYSTEM_STATUS_INVALID" 0 "EPBM_SYSTEM_STATUS_VALID" ;
VAL_ 1123 VCRIGHT_epbmUnitStatus 23 "EPB_STATUS_COUNT" 22 "EPB_STATUS_AUTONOMY_OPEN" 21 "EPB_STATUS_FREE_ROLL_MODE" 20 "EPB_STATUS_DYNAMIC_PARKING" 19 "EPB_STATUS_EXTERNAL_PARKING" 18 "EPB_STATUS_RELEASING_FOR_EXTERNAL_PARK" 17 "EPB_STATUS_EXTERNAL_DYNAMIC" 16 "EPB_STATUS_SUMMON_PARKING" 15 "EPB_STATUS_SUMMON_RELEASING" 14 "EPB_STATUS_SUMMON" 13 "EPB_STATUS_WINCHMODE_PENDING" 12 "EPB_STATUS_PARK_PENDING" 11 "EPB_STATUS_SERVICE_RELEASING" 10 "EPB_STATUS_RELEASING" 9 "EPB_STATUS_DYNAMIC_APPLYING" 8 "EPB_STATUS_PARKING" 7 "EPB_STATUS_WINCHMODE_RELEASING" 6 "EPB_STATUS_WINCHMODE" 5 "EPB_STATUS_SERVICE" 4 "EPB_STATUS_START" 3 "EPB_STATUS_PARK" 2 "EPB_STATUS_DYNAMIC" 1 "EPB_STATUS_OPEN" 0 "EPB_STATUS_UNKNOWN" ;
VAL_ 1123 VCRIGHT_epbmCdpState 2 "EPB_CDP_STATE_FAULT" 1 "EPB_CDP_STATE_VALID" 0 "EPB_CDP_STATE_UNKNOWN" ;
VAL_ 524 VCRIGHT_tempEvaporator 2047 "SNA" ;
VAL_ 524 VCRIGHT_tempEvaporatorTarget 255 "SNA" ;
VAL_ 524 VCRIGHT_tempAmbientRaw 0 "SNA" ;
VAL_ 524 VCRIGHT_hvacPerfTestState 2 "BLOWING" 1 "WAITING" 0 "STOPPED" ;
VAL_ 579 VCRIGHT_hvacStatusIndex 5 "MISC3" 4 "MISC2" 3 "MISC" 2 "VCFRONT2" 1 "VCFRONT" 0 "UI" ;
VAL_ 579 VCRIGHT_childModeHVACState 2 "ACTIVE_COMPROMISED" 1 "ACTIVE" 0 "IDLE" ;
VAL_ 579 VCRIGHT_dogModeState 15 "DOG_MODE_INVALID" 6 "DOG_MODE_RUNNING_TEMP_MONITOR_TRIP" 5 "DOG_MODE_RUNNING_DEVICE_OR_MODEL_FAULT" 4 "DOG_MODE_RUNNING" 3 "DOG_MODE_AVAILABLE" 2 "DOG_MODE_INITIALIZING" 1 "DOG_MODE_UNAVAILABLE_CABIN_TOO_HOT" 0 "DOG_MODE_UNAVAILABLE_MODEL_DEVICE_FAULT" ;
VAL_ 579 VCRIGHT_COPNotRunningReasonFilte 7 "CABIN_BELOW_THRESHOLD" 6 "WAITING" 5 "LOW_SOLAR_LOAD" 4 "TIMEOUT" 3 "ENERGY_CONSUMPTION_LIMIT" 2 "USER_INTERACTION" 1 "DISABLED" 0 "NONE" ;
VAL_ 579 VCRIGHT_hvacAirDistributionMode 7 "DEFROST_PANEL_FLOOR" 6 "DEFROST_PANEL" 5 "DEFROST_FLOOR" 4 "DEFROST" 3 "PANEL_FLOOR" 2 "PANEL" 1 "FLOOR" 0 "NONE" ;
VAL_ 579 VCRIGHT_hvacBlowerSegment 11 "11" 10 "10" 9 "9" 8 "8" 7 "7" 6 "6" 5 "5" 4 "4" 3 "3" 2 "2" 1 "1" 0 "OFF" ;
VAL_ 579 VCRIGHT_hvacRecirc 2 "FRESH" 1 "RECIRC" 0 "AUTO" ;
VAL_ 579 VCRIGHT_hvacACRunning 1 "ON" 0 "OFF" ;
VAL_ 579 VCRIGHT_hvacPowerState 4 "OVERHEAT_PROTECT" 3 "OVERHEAT_PROTECT_FANONLY" 2 "PRECONDITION" 1 "ON" 0 "OFF" ;
VAL_ 579 VCRIGHT_hvacVentStatus 3 "OFF" 2 "RIGHT" 1 "LEFT" 0 "BOTH" ;
VAL_ 579 VCRIGHT_hvacSecondRowState 4 "HIGH" 3 "MED" 2 "LOW" 1 "OFF" 0 "AUTO" ;
VAL_ 579 VCRIGHT_hvacModelInitStatus 9 "NOT_INIT_CAMERA_POCKET_BEING_INITIALIZED" 8 "INIT_FORWARD_CALC_LIMP" 7 "INIT_FROM_SENSORS_PREDICTION_ERROR_LIMP" 6 "INIT_FROM_SENSORS_LIMP" 5 "INIT_WAITING_FOR_SENSORS" 4 "INIT_FORWARD_CALC" 3 "INIT_FROM_SENSORS_PREDICTION_ERROR" 2 "INIT_FROM_SENSORS" 1 "NOT_INIT_WAIT_FOR_GTW" 0 "NOT_INIT_WAIT_FOR_SENSORS" ;
VAL_ 579 VCRIGHT_tempDuctLeft 255 "SNA" ;
VAL_ 579 VCRIGHT_tempDuctRight 255 "SNA" ;
VAL_ 579 VCRIGHT_hvacDuctTargetLeft 255 "SNA" ;
VAL_ 579 VCRIGHT_hvacDuctTargetRight 255 "SNA" ;
VAL_ 579 VCRIGHT_tempDuctRightUpper 255 "SNA" ;
VAL_ 579 VCRIGHT_hvacEvapInletTempEstimat 1023 "SNA" ;
VAL_ 579 VCRIGHT_hvacAirflowReason 21 "NONE" 20 "ODOR_ROUTINE" 19 "DRIVERLESS_SELF_TEST" 18 "VOC_PURGE" 17 "STRATIFICATION_TOP_PAD_AREA" 16 "HOT_DUCT_LOCKOUT" 15 "COLD_DUCT_LOCKOUT" 14 "BIOWEAPON_DEFENSE" 13 "EVAP_OIL_PURGE" 12 "EVAP_DRYING" 11 "SCREEN_PROTECTION" 10 "CABIN_OVERHEAT_PROTECT" 9 "CABIN_PURGE" 8 "OUTLET_TEMP_LIMIT" 7 "OCCUPANT_CONVECTION_REQUIREMENT" 6 "STRATIFICATION_INTERIOR_SURFACES" 5 "STRATIFICATION_GLASS_ROOF" 4 "MINIMUM_AUTO_AIRFLOW" 3 "CABIN_TEMPERATURE_CONTROL" 2 "UI_SHORTCUT" 1 "MANUAL_FAN_SPEED" 0 "HVAC_OFF" ;
VAL_ 579 VCRIGHT_solarLoadOnVehicle 255 "SNA" ;
VAL_ 579 VCRIGHT_hvacFrontRightSeatFanSta 3 "FAN_REQUEST_LEVEL3" 2 "FAN_REQUEST_LEVEL2" 1 "FAN_REQUEST_LEVEL1" 0 "FAN_REQUEST_OFF" ;
VAL_ 579 VCRIGHT_hvacFrontLeftSeatFanStat 3 "FAN_REQUEST_LEVEL3" 2 "FAN_REQUEST_LEVEL2" 1 "FAN_REQUEST_LEVEL1" 0 "FAN_REQUEST_OFF" ;
VAL_ 579 VCRIGHT_extendedHvacPerfTestSupp 10 "STOP" 9 "COUNT" 8 "8_CABIN_PURGE" 7 "7_BATTERY_COOL" 6 "6_BATTERY_HEAT_COP1" 5 "5_CABIN_HEAT_COP1" 4 "4_CABIN_COOL" 3 "3_SPLIT_REHEAT_COOL_DOMINANT" 2 "2_BATT_HEAT_CABIN_REHEAT_AS" 1 "1_CABIN_HEAT_AS" 0 "INIT" ;
VAL_ 579 VCRIGHT_hvacFrontRightSeatHeatSt 3 "HEATER_REQUEST_LEVEL3" 2 "HEATER_REQUEST_LEVEL2" 1 "HEATER_REQUEST_LEVEL1" 0 "HEATER_REQUEST_OFF" ;
VAL_ 579 VCRIGHT_hvacSeatFrontLeftTempTar 0 "OFF" ;
VAL_ 579 VCRIGHT_hvacManualToAutoNotify 6 "MISC3" 5 "MISC2" 4 "COMFORT_FORWARD_LOOK" 3 "FOGGING_COMFORT" 2 "FOGGING" 1 "COMFORT" 0 "OFF" ;
VAL_ 579 VCRIGHT_hvacRequestsFullAuto 7 "MISC4" 6 "MISC3" 5 "MISC2" 4 "MISC1" 3 "HVAC_OFF_FOGGING_RISK" 2 "MANUAL_HVAC_HIGH_FOGGING_RISK" 1 "HIGH_BLOWER_SPEED" 0 "NOT_ALLOWED" ;
VAL_ 579 VCRIGHT_steeringWheelHeatStatus 3 "STEERING_WHEEL_HEAT_LEVEL3" 2 "STEERING_WHEEL_HEAT_LEVEL2" 1 "STEERING_WHEEL_HEAT_LEVEL1" 0 "STEERING_WHEEL_HEAT_OFF" ;
VAL_ 579 VCRIGHT_autoDefogStatus 2 "INTERMEDIATE_DEFOG" 1 "DEFOG" 0 "NONE" ;
VAL_ 579 VCRIGHT_solarElevation -256 "SNA" ;
VAL_ 579 VCRIGHT_minsToSunrise 255 "SNA" ;
VAL_ 579 VCRIGHT_minsToSunset 255 "SNA" ;
VAL_ 579 VCRIGHT_hvacLimitedReasonRight 7 "HVAC_LIMITING_MANUAL_BLOWER" 6 "HVAC_LIMITING_CDL_AND_QDLH" 5 "HVAC_LIMITING_HDL_AND_QDLC" 4 "HVAC_LIMITING_QDOT_LIMITED_HEATING" 3 "HVAC_LIMITING_QDOT_LIMITED_COOLING" 2 "HVAC_LIMITING_COLD_DUCT_LOCKOUT" 1 "HVAC_LIMITING_HOT_DUCT_LOCKOUT" 0 "HVAC_LIMITING_NONE" ;
VAL_ 579 VCRIGHT_hvacLimitedReasonLeft 7 "HVAC_LIMITING_MANUAL_BLOWER" 6 "HVAC_LIMITING_CDL_AND_QDLH" 5 "HVAC_LIMITING_HDL_AND_QDLC" 4 "HVAC_LIMITING_QDOT_LIMITED_HEATING" 3 "HVAC_LIMITING_QDOT_LIMITED_COOLING" 2 "HVAC_LIMITING_COLD_DUCT_LOCKOUT" 1 "HVAC_LIMITING_HOT_DUCT_LOCKOUT" 0 "HVAC_LIMITING_NONE" ;
VAL_ 579 VCRIGHT_tempDuctLeftUpper 255 "SNA" ;
VAL_ 579 VCRIGHT_hvacFrontLeftSeatHeatSta 3 "HEATER_REQUEST_LEVEL3" 2 "HEATER_REQUEST_LEVEL2" 1 "HEATER_REQUEST_LEVEL1" 0 "HEATER_REQUEST_OFF" ;
VAL_ 579 VCRIGHT_tempDuctLeftLower 255 "SNA" ;
VAL_ 579 VCRIGHT_tempDuctRightLower 255 "SNA" ;
VAL_ 774 VCRIGHT_infoIndex 255 "END" 41 "SUBCOMPONENT14" 40 "SUBCOMPONENT13" 39 "SUBCOMPONENT12" 38 "SUBCOMPONENT11" 37 "SUBCOMPONENT10" 36 "SUBCOMPONENT9" 35 "SUBCOMPONENT8" 34 "SUBCOMPONENT7" 33 "SUBCOMPONENT6" 32 "SUBCOMPONENT5" 31 "SUBCOMPONENT4" 24 "SUBCOMPONENT3" 23 "SUBCOMPONENT2" 20 "UDS_PROTOCOL_BOOTCRC" 19 "VERSION_DEPRECATED" 18 "BOOTLOADER_GITHASH" 17 "APP_GITHASH" 16 "SUBCOMPONENT1" 15 "BOOTLOADER_CRC" 14 "BOOTLOADER_SVN" 13 "APP_CRC" 11 "PCBAID_ASSYID_USAGEID" 10 "BUILD_HWID_COMPONENTID" 9 "DEPRECATED_9" 8 "DEPRECATED_8" 7 "DEPRECATED_7" 6 "DEPRECATED_6" 5 "DEPRECATED_5" 4 "DEPRECATED_4" 3 "DEPRECATED_3" 2 "DEPRECATED_2" 1 "DEPRECATED_1" 0 "DEPRECATED_0" ;
VAL_ 774 VCRIGHT_infoBuildType 4 "INFO_MFG_BUILD" 3 "INFO_TRACEABLE_CI_BUILD" 2 "INFO_LOCAL_BUILD" 1 "INFO_PLATFORM_BUILD" 0 "INFO_UNKNOWN_BUILD" ;
VAL_ 774 VCRIGHT_infoAssemblyId 255 "ASSEMBLY_SNA" 1 "ASSEMBLY1" ;
